VERSION ""

NS_ :

BS_:

BU_: TM

BO_ 732 TPMS1: 8 Vector__XXX
 SG_ TpmsTireSensorConfig : 47|2@0+ (1,0) [0|3] ""  TM
 SG_ TPMSPresence : 49|1@0+ (1,0) [0|1] ""  TM
 SG_ LowTirePresAlertSpare : 14|1@0+ (1,0) [0|1] ""  TM
 SG_ LowTirePresAlertRL : 13|1@0+ (1,0) [0|1] ""  TM
 SG_ LowTirePresAlertRR : 12|1@0+ (1,0) [0|1] ""  TM
 SG_ LowTirePresAlertFR : 11|1@0+ (1,0) [0|1] ""  TM
 SG_ LowTirePresAlertFL : 10|1@0+ (1,0) [0|1] ""  TM
 SG_ HighTirePresAlertSpare : 4|1@0+ (1,0) [0|1] ""  TM
 SG_ HighTirePresAlertRL : 2|1@0+ (1,0) [0|1] ""  TM
 SG_ HighTirePresAlertRR : 3|1@0+ (1,0) [0|1] ""  TM
 SG_ HighTirePresAlertFR : 1|1@0+ (1,0) [0|1] ""  TM
 SG_ HighTirePresAlertFL : 0|1@0+ (1,0) [0|1] ""  TM
 SG_ HighTireTempAlertSpare : 9|1@0+ (1,0) [0|1] ""  TM
 SG_ HighTireTempAlertRL : 7|1@0+ (1,0) [0|1] ""  TM
 SG_ HighTireTempAlertRR : 8|1@0+ (1,0) [0|1] ""  TM
 SG_ HighTireTempAlertFR : 6|1@0+ (1,0) [0|1] ""  TM
 SG_ HighTireTempAlertFL : 5|1@0+ (1,0) [0|1] ""  TM
 SG_ PresLeakageAlertSpare : 19|1@0+ (1,0) [0|1] ""  TM
 SG_ PresLeakageAlertRL : 17|1@0+ (1,0) [0|1] ""  TM
 SG_ PresLeakageAlertRR : 18|1@0+ (1,0) [0|1] ""  TM
 SG_ PresLeakageAlertFR : 16|1@0+ (1,0) [0|1] ""  TM
 SG_ PresLeakageAlertFL : 15|1@0+ (1,0) [0|1] ""  TM
 SG_ TpmsAlertStatus : 45|2@0+ (1,0) [0|3] ""  TM
 SG_ TpmsReceiverRXFault : 48|1@0+ (1,0) [0|1] ""  TM
 SG_ SensorMalfncFaultSpare : 29|1@0+ (1,0) [0|1] ""  TM
 SG_ SensorMalfncFaultRL : 27|1@0+ (1,0) [0|1] ""  TM
 SG_ SensorMalfncFaultRR : 28|1@0+ (1,0) [0|1] ""  TM
 SG_ SensorMalfncFaultFR : 26|1@0+ (1,0) [0|1] ""  TM
 SG_ SensorMalfncFaultFL : 25|1@0+ (1,0) [0|1] ""  TM
 SG_ TpmsFaultStatus : 39|2@0+ (1,0) [0|3] ""  TM
 SG_ TpmsNotLearntFault : 40|1@0+ (1,0) [0|1] ""  TM
 SG_ SensorMissingFaultRL : 32|1@0+ (1,0) [0|1] ""  TM
 SG_ SensorMissingFaultRR : 33|1@0+ (1,0) [0|1] ""  TM
 SG_ SensorMissingFaultFR : 31|1@0+ (1,0) [0|1] ""  TM
 SG_ SensorMissingFaultFL : 30|1@0+ (1,0) [0|1] ""  TM
 SG_ TpmsLearnStatus : 51|2@0+ (1,0) [0|3] ""  TM
 SG_ SpareTireSwapFlagRL : 36|1@0+ (1,0) [0|1] ""  TM
 SG_ SpareTireSwapFlagRR : 37|1@0+ (1,0) [0|1] ""  TM
 SG_ SpareTireSwapFlagFR : 35|1@0+ (1,0) [0|1] ""  TM
 SG_ SpareTireSwapFlagFL : 34|1@0+ (1,0) [0|1] ""  TM
 SG_ SensorLearningStatus : 43|3@0+ (1,0) [0|7] ""  TM
 SG_ SensorDetectFlagSpare : 24|1@0+ (1,0) [0|1] ""  TM
 SG_ SensorDetectFlagRL : 22|1@0+ (1,0) [0|1] ""  TM
 SG_ SensorDetectFlagRR : 23|1@0+ (1,0) [0|1] ""  TM
 SG_ SensorDetectFlagFR : 21|1@0+ (1,0) [0|1] ""  TM
 SG_ SensorDetectFlagFL : 20|1@0+ (1,0) [0|1] ""  TM

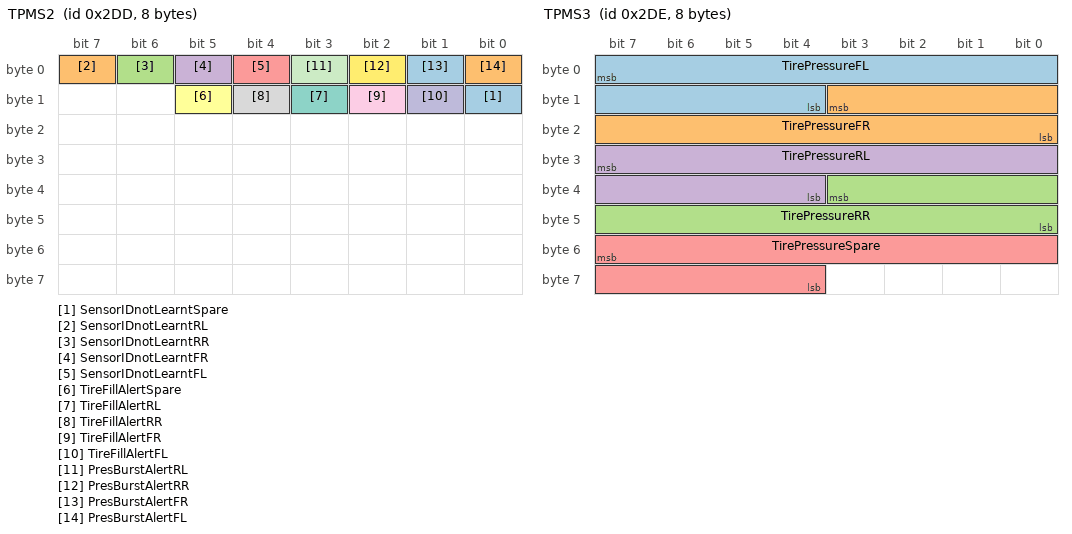
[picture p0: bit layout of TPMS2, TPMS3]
BO_ 733 TPMS2: 8 Vector__XXX
 SG_ SensorIDnotLearntSpare : 8|1@0+ (1,0) [0|1] ""  TM
 SG_ SensorIDnotLearntRL : 7|1@0+ (1,0) [0|1] ""  TM
 SG_ SensorIDnotLearntRR : 6|1@0+ (1,0) [0|1] ""  TM
 SG_ SensorIDnotLearntFR : 5|1@0+ (1,0) [0|1] ""  TM
 SG_ SensorIDnotLearntFL : 4|1@0+ (1,0) [0|1] ""  TM
 SG_ TireFillAlertSpare : 13|1@0+ (1,0) [0|1] ""  TM
 SG_ TireFillAlertRL : 11|1@0+ (1,0) [0|1] ""  TM
 SG_ TireFillAlertRR : 12|1@0+ (1,0) [0|1] ""  TM
 SG_ TireFillAlertFR : 10|1@0+ (1,0) [0|1] ""  TM
 SG_ TireFillAlertFL : 9|1@0+ (1,0) [0|1] ""  TM
 SG_ PresBurstAlertRL : 3|1@0+ (1,0) [0|1] ""  TM
 SG_ PresBurstAlertRR : 2|1@0+ (1,0) [0|1] ""  TM
 SG_ PresBurstAlertFR : 1|1@0+ (1,0) [0|1] ""  TM
 SG_ PresBurstAlertFL : 0|1@0+ (1,0) [0|1] ""  TM

BO_ 734 TPMS3: 8 Vector__XXX
 SG_ TirePressureFL : 7|12@0+ (0.1,0) [0|409.5] "Psi"  TM
 SG_ TirePressureFR : 11|12@0+ (0.1,0) [0|409.5] "Psi"  TM
 SG_ TirePressureRR : 35|12@0+ (0.1,0) [0|409.5] "Psi"  TM
 SG_ TirePressureRL : 31|12@0+ (0.1,0) [0|409.5] "Psi"  TM
 SG_ TirePressureSpare : 55|12@0+ (0.1,0) [0|409.5] "Psi"  TM

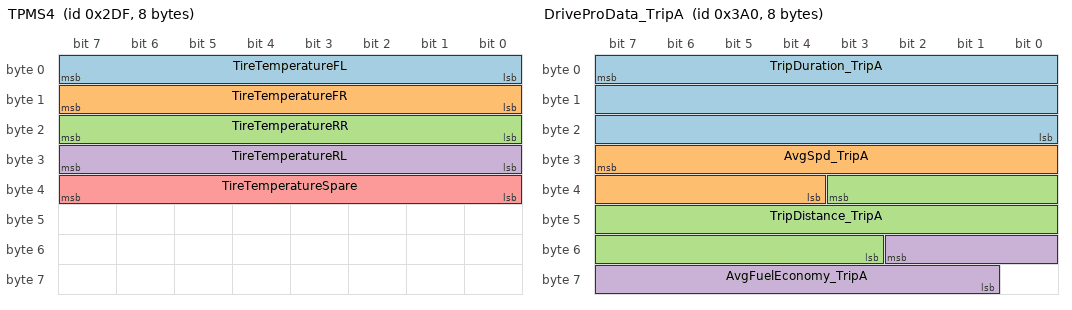
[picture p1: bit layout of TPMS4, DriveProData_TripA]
BO_ 735 TPMS4: 8 Vector__XXX
 SG_ TireTemperatureFL : 7|8@0+ (1,-40) [-40|215] "Deg C"  TM
 SG_ TireTemperatureFR : 15|8@0+ (1,-40) [-40|215] "Deg C"  TM
 SG_ TireTemperatureRR : 23|8@0+ (1,-40) [-40|215] "Deg C"  TM
 SG_ TireTemperatureRL : 31|8@0+ (1,-40) [-40|215] "Deg C"  TM
 SG_ TireTemperatureSpare : 39|8@0+ (1,-40) [-40|215] "Deg C"  TM

BO_ 744 HU_CCM_VR_Control: 8 Vector__XXX
 SG_ HuCCmFanSpdDuringVR : 5|4@0+ (1,0) [0|15] ""  TM
 SG_ HuCCmVRSession : 7|2@0+ (1,0) [0|3] ""  TM

BO_ 928 DriveProData_TripA: 8 Vector__XXX
 SG_ TripDuration_TripA : 7|24@0+ (1,0) [0|3600000] "sec"  TM
 SG_ AvgSpd_TripA : 31|12@0+ (0.03125,0) [0|127.96875] "m/s"  TM
 SG_ TripDistance_TripA : 35|17@0+ (0.1,0) [0|9999.9] "Km"  TM
 SG_ AvgFuelEconomy_TripA : 50|10@0+ (0.1,0) [0|99.9] "Km/L"  TM

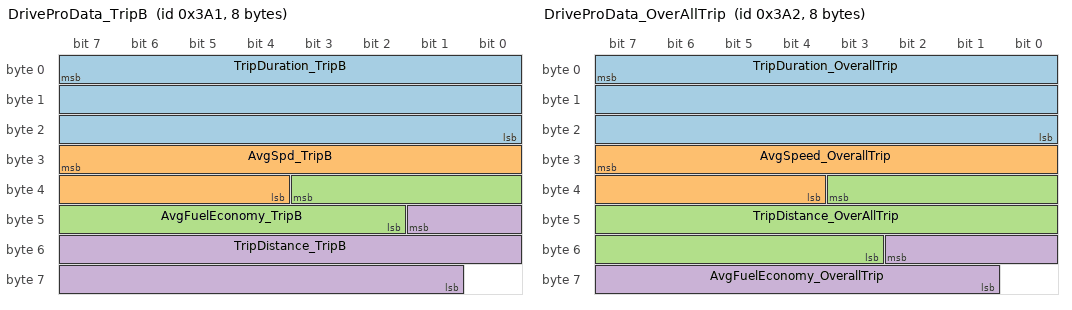
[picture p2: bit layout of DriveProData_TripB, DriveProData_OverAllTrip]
BO_ 929 DriveProData_TripB: 8 Vector__XXX
 SG_ TripDuration_TripB : 7|24@0+ (1,0) [0|3600000] "sec"  TM
 SG_ AvgSpd_TripB : 31|12@0+ (0.03125,0) [0|127.96875] "m/s"  TM
 SG_ AvgFuelEconomy_TripB : 35|10@0+ (0.1,0) [0|99.9] "Km/L"  TM
 SG_ TripDistance_TripB : 41|17@0+ (0.1,0) [0|9999.9] "Km"  TM

BO_ 930 DriveProData_OverAllTrip: 8 Vector__XXX
 SG_ TripDuration_OverallTrip : 7|24@0+ (1,0) [0|3600000] "sec"  TM
 SG_ AvgSpeed_OverallTrip : 31|12@0+ (0.03125,0) [0|127.96875] "m/s"  TM
 SG_ TripDistance_OverAllTrip : 35|17@0+ (0.1,0) [0|9999.9] "Km"  TM
 SG_ AvgFuelEconomy_OverallTrip : 50|10@0+ (0.1,0) [0|99.9] "Km/L"  TM

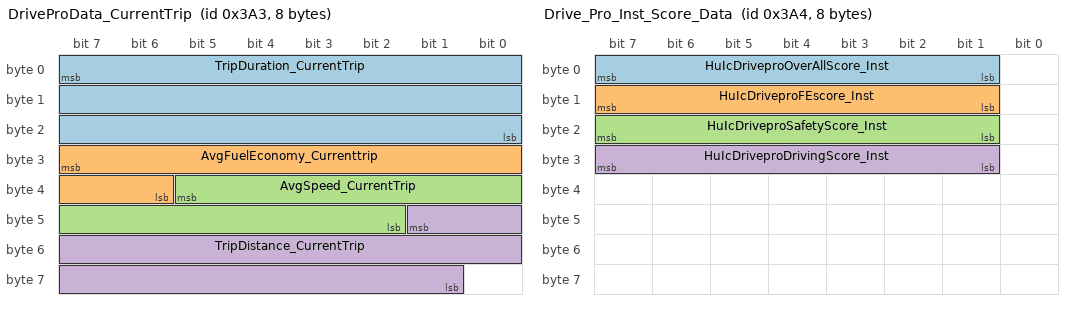
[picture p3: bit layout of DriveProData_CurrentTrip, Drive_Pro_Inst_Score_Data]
BO_ 931 DriveProData_CurrentTrip: 8 Vector__XXX
 SG_ TripDuration_CurrentTrip : 7|24@0+ (1,0) [0|3600000] "sec"  TM
 SG_ AvgFuelEconomy_Currenttrip : 31|10@0+ (0.1,0) [0|99.9] "Km/L"  TM
 SG_ AvgSpeed_CurrentTrip : 37|12@0+ (0.03125,0) [0|127.96875] "m/s"  TM
 SG_ TripDistance_CurrentTrip : 41|17@0+ (0.1,0) [0|9999.9] "Km"  TM

BO_ 932 Drive_Pro_Inst_Score_Data: 8 Vector__XXX
 SG_ HuIcDriveproOverAllScore_Inst : 7|7@0+ (0.1,0) [0|10] ""  TM
 SG_ HuIcDriveproFEscore_Inst : 15|7@0+ (0.1,0) [0|10] ""  TM
 SG_ HuIcDriveproSafetyScore_Inst : 23|7@0+ (0.1,0) [0|10] ""  TM
 SG_ HuIcDriveproDrivingScore_Inst : 31|7@0+ (0.1,0) [0|10] ""  TM

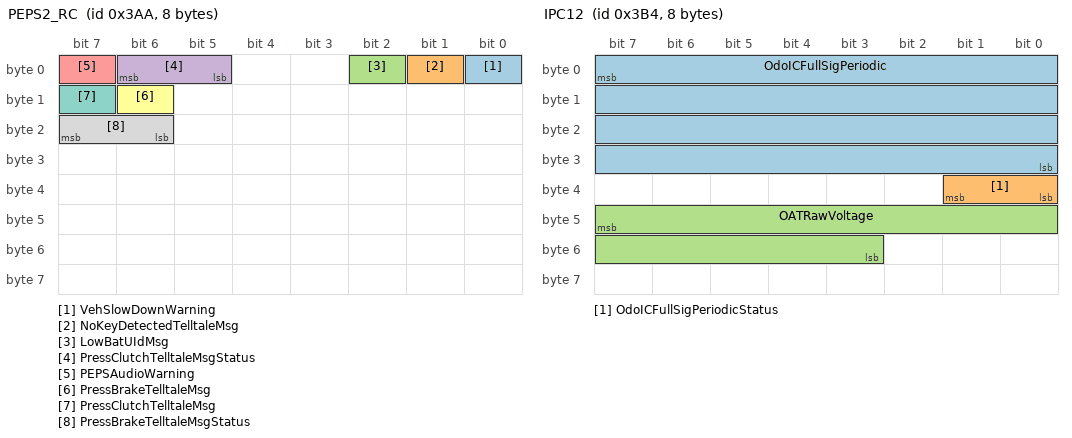
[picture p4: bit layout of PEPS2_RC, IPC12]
BO_ 938 PEPS2_RC: 8 Vector__XXX
 SG_ VehSlowDownWarning : 0|1@0+ (1,0) [0|1] ""  TM
 SG_ NoKeyDetectedTelltaleMsg : 1|1@0+ (1,0) [0|1] ""  TM
 SG_ LowBatUIdMsg : 2|1@0+ (1,0) [0|1] ""  TM
 SG_ PressClutchTelltaleMsgStatus : 6|2@0+ (1,0) [0|3] ""  TM
 SG_ PEPSAudioWarning : 7|1@0+ (1,0) [0|1] ""  TM
 SG_ PressBrakeTelltaleMsg : 14|1@0+ (1,0) [0|1] ""  TM
 SG_ PressClutchTelltaleMsg : 15|1@0+ (1,0) [0|1] ""  TM
 SG_ PressBrakeTelltaleMsgStatus : 23|2@0+ (1,0) [0|3] ""  TM

BO_ 946 BCM_IC_RC4: 8 Vector__XXX
 SG_ DoorStateRearLHStatus : 1|2@0+ (1,0) [0|3] ""  TM
 SG_ DoorStatePassStatus : 3|2@0+ (1,0) [0|3] ""  TM
 SG_ DoorStatePass : 4|1@0+ (1,0) [0|1] ""  TM
 SG_ DoorStateDrvrStatus : 6|2@0+ (1,0) [0|3] ""  TM
 SG_ DoorStateDrvr : 7|1@0+ (1,0) [0|1] ""  TM
 SG_ DoorStateRearRH : 8|1@0+ (1,0) [0|1] ""  TM
 SG_ DoorStateRearRHStatus : 10|2@0+ (1,0) [0|3] ""  TM
 SG_ DoorStateRearLH : 11|1@0+ (1,0) [0|1] ""  TM
 SG_ WiperState : 14|3@0+ (1,0) [0|7] ""  TM
 SG_ TailgateState : 15|1@0+ (1,0) [0|1] ""  TM
 SG_ WiperStateStatus : 17|2@0+ (1,0) [0|3] ""  TM
 SG_ TailgateStateStatus : 19|2@0+ (1,0) [0|3] ""  TM
 SG_ PositionLmpMalFn : 20|1@0+ (1,0) [0|1] ""  TM
 SG_ TrailerState : 21|1@0+ (1,0) [0|1] ""  TM
 SG_ PositionLmpMalFnStatus : 23|2@0+ (1,0) [0|3] ""  TM
 SG_ BrakeLmpMalFn : 24|1@0+ (1,0) [0|1] ""  TM
 SG_ BrakeLmpMalFnStatus : 26|2@0+ (1,0) [0|3] ""  TM
 SG_ RevLampMalFn : 27|1@0+ (1,0) [0|1] ""  TM
 SG_ RevLampMalFnStatus : 29|2@0+ (1,0) [0|3] ""  TM
 SG_ TrailerStateStatus : 31|2@0+ (1,0) [0|3] ""  TM
 SG_ LowBeamMalFn : 32|1@0+ (1,0) [0|1] ""  TM
 SG_ HighBeamTelltale : 33|1@0+ (1,0) [0|1] ""  TM
 SG_ HighBeamTelltaleStatus : 35|2@0+ (1,0) [0|3] ""  TM
 SG_ DRLTelltale : 36|1@0+ (1,0) [0|1] ""  TM
 SG_ FrontFogTelltale : 37|1@0+ (1,0) [0|1] ""  TM
 SG_ RearFogTelltaleStatus : 39|2@0+ (1,0) [0|3] ""  TM
 SG_ FrontFogTelltaleStatus : 41|2@0+ (1,0) [0|3] ""  TM
 SG_ DRLTelltaleStatus : 43|2@0+ (1,0) [0|3] ""  TM
 SG_ InfoTheftMsg : 45|2@0+ (1,0) [0|3] ""  TM
 SG_ WiperHighLowIntermtStateStatus : 47|2@0+ (1,0) [0|3] ""  TM
 SG_ WiperHighLowIntermtState : 50|3@0+ (1,0) [0|7] ""  TM
 SG_ LowBeamMalFnStatus : 52|2@0+ (1,0) [0|3] ""  TM
 SG_ ESSSwSig : 53|1@0+ (1,0) [0|1] ""  TM
 SG_ BonnetState : 54|1@0+ (1,0) [0|1] ""  TM
 SG_ RearFogTelltale : 55|1@0+ (1,0) [0|1] ""  TM
 SG_ BonnetStateStatus : 57|2@0+ (1,0) [0|3] ""  TM
 SG_ VehicleUnLockTypeConfgStatus : 59|2@0+ (1,0) [0|3] ""  TM
 SG_ VehicleUnLockTypeConfg : 61|2@0+ (1,0) [0|3] ""  TM
 SG_ ESSSwSigStatus : 63|2@0+ (1,0) [0|3] ""  TM

BO_ 948 IPC12: 8 Vector__XXX
 SG_ OdoICFullSigPeriodic : 7|32@0+ (1,0) [0|999999000] "m"  TM
 SG_ OdoICFullSigPeriodicStatus : 33|2@0+ (1,0) [0|3] ""  TM
 SG_ OATRawVoltage : 47|13@0+ (0.001,0) [0|5] "v"  TM

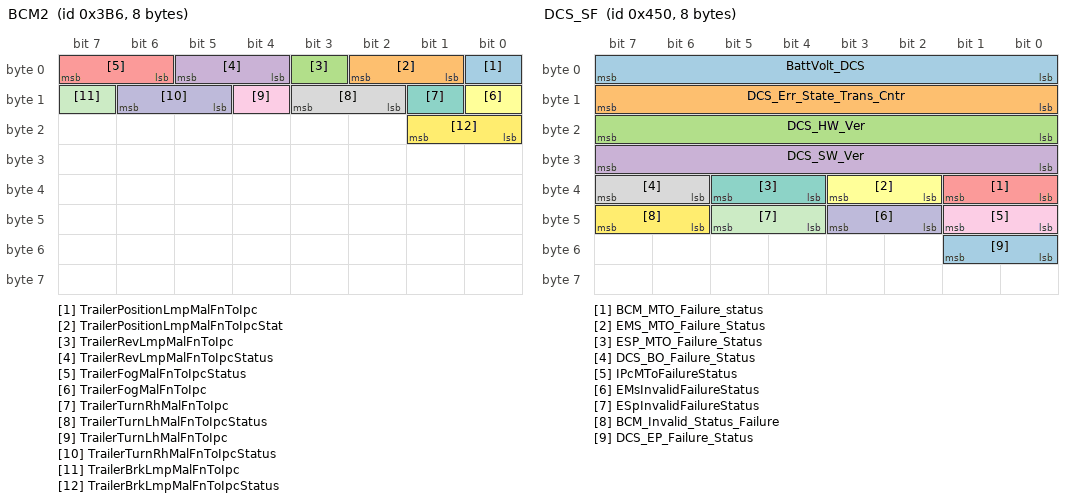
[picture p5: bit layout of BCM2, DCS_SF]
BO_ 950 BCM2: 8 Vector__XXX
 SG_ TrailerPositionLmpMalFnToIpc : 0|1@0+ (1,0) [0|1] ""  TM
 SG_ TrailerPositionLmpMalFnToIpcStat : 2|2@0+ (1,0) [0|3] ""  TM
 SG_ TrailerRevLmpMalFnToIpc : 3|1@0+ (1,0) [0|1] ""  TM
 SG_ TrailerRevLmpMalFnToIpcStatus : 5|2@0+ (1,0) [0|3] ""  TM
 SG_ TrailerFogMalFnToIpcStatus : 7|2@0+ (1,0) [0|3] ""  TM
 SG_ TrailerFogMalFnToIpc : 8|1@0+ (1,0) [0|1] ""  TM
 SG_ TrailerTurnRhMalFnToIpc : 9|1@0+ (1,0) [0|1] ""  TM
 SG_ TrailerTurnLhMalFnToIpcStatus : 11|2@0+ (1,0) [0|3] ""  TM
 SG_ TrailerTurnLhMalFnToIpc : 12|1@0+ (1,0) [0|1] ""  TM
 SG_ TrailerTurnRhMalFnToIpcStatus : 14|2@0+ (1,0) [0|3] ""  TM
 SG_ TrailerBrkLmpMalFnToIpc : 15|1@0+ (1,0) [0|1] ""  TM
 SG_ TrailerBrkLmpMalFnToIpcStatus : 17|2@0+ (1,0) [0|3] ""  TM

BO_ 1068 IPC7: 8 Vector__XXX
 SG_ IcHuVcInfo : 7|40@0+ (1,0) [0|0] ""  TM
 SG_ ICDrvModeFunVariant : 47|16@0+ (1,0) [0|65535] ""  TM

BO_ 1069 IPC9: 8 Vector__XXX
 SG_ IcHuVcInfonew : 7|64@0+ (1,0) [0|1.8446744074E+019] ""  TM

BO_ 1104 DCS_SF: 8 Vector__XXX
 SG_ BattVolt_DCS : 7|8@0+ (0.1,0) [0|25] "V"  TM
 SG_ DCS_Err_State_Trans_Cntr : 15|8@0+ (1,0) [0|255] ""  TM
 SG_ DCS_HW_Ver : 23|8@0+ (1,0) [0|99] ""  TM
 SG_ DCS_SW_Ver : 31|8@0+ (1,0) [0|255] ""  TM
 SG_ BCM_MTO_Failure_status : 33|2@0+ (1,0) [0|3] ""  TM
 SG_ EMS_MTO_Failure_Status : 35|2@0+ (1,0) [0|3] ""  TM
 SG_ ESP_MTO_Failure_Status : 37|2@0+ (1,0) [0|3] ""  TM
 SG_ DCS_BO_Failure_Status : 39|2@0+ (1,0) [0|3] ""  TM
 SG_ IPcMToFailureStatus : 41|2@0+ (1,0) [0|3] ""  TM
 SG_ EMsInvalidFailureStatus : 43|2@0+ (1,0) [0|3] ""  TM
 SG_ ESpInvalidFailureStatus : 45|2@0+ (1,0) [0|3] ""  TM
 SG_ BCM_Invalid_Status_Failure : 47|2@0+ (1,0) [0|3] ""  TM
 SG_ DCS_EP_Failure_Status : 49|2@0+ (1,0) [0|3] ""  TM

BO_ 1120 HU6: 8 Vector__XXX
 SG_ HuIcTpSig : 7|64@0+ (1,0) [0|0] ""  TM

BO_ 1121 IPC13: 8 Vector__XXX
 SG_ IcHuTpSig : 7|64@0+ (1,0) [0|0] ""  TM

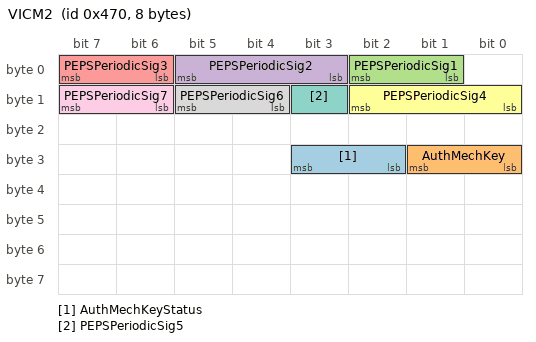
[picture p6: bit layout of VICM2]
BO_ 1136 VICM2: 8 Vector__XXX
 SG_ AuthMechKeyStatus : 27|2@0+ (1,0) [0|3] ""  TM
 SG_ AuthMechKey : 25|2@0+ (1,0) [0|3] ""  TM
 SG_ PEPSPeriodicSig1 : 2|2@0+ (1,0) [0|3] ""  TM
 SG_ PEPSPeriodicSig2 : 5|3@0+ (1,0) [0|7] ""  TM
 SG_ PEPSPeriodicSig3 : 7|2@0+ (1,0) [0|3] ""  TM
 SG_ PEPSPeriodicSig4 : 10|3@0+ (1,0) [0|7] ""  TM
 SG_ PEPSPeriodicSig5 : 11|1@0+ (1,0) [0|1] ""  TM
 SG_ PEPSPeriodicSig6 : 13|2@0+ (1,0) [0|3] ""  TM
 SG_ PEPSPeriodicSig7 : 15|2@0+ (1,0) [0|3] ""  TM

BO_ 1140 EMS_SF: 8 Vector__XXX
 SG_ Telematics_MTO_Failure_Status : 29|2@0+ (1,0) [0|3] ""  TM
 SG_ Telematics_Invalid_Failure__0000 : 31|2@0+ (1,0) [0|3] ""  TM
 SG_ HU_MTO_Failure_Status : 25|2@0+ (1,0) [0|3] ""  TM
 SG_ HU_Invalid_Failure_Status : 27|2@0+ (1,0) [0|3] ""  TM
 SG_ CCM_Invalid_Failure_Status : 37|2@0+ (1,0) [0|3] ""  TM
 SG_ EMS_SW_Version : 7|16@0+ (1,0) [0|255] ""  TM
 SG_ AT_AMT_DCT_MTO_Failure_Status : 17|2@0+ (1,0) [0|3] ""  TM
 SG_ EPAS_Invalid_Failure_Status : 19|2@0+ (1,0) [0|3] ""  TM
 SG_ BCmMToFailureStatus : 21|2@0+ (1,0) [0|3] ""  TM
 SG_ EPAS_MTO_Failure_Status : 23|2@0+ (1,0) [0|3] ""  TM
 SG_ EMS_BO_Failure_Status : 33|2@0+ (1,0) [0|3] ""  TM
 SG_ EMS_EP_Failure_Status : 35|2@0+ (1,0) [0|3] ""  TM
 SG_ ABS_ESP_MTO_Failure_Status : 39|2@0+ (1,0) [0|3] ""  TM
 SG_ PEPS_MTO_Failure_Status : 41|2@0+ (1,0) [0|3] ""  TM
 SG_ AT_AMT_DCT_Invalid_Failure_Statu : 43|2@0+ (1,0) [0|3] ""  TM
 SG_ ABS_ESP_Invalid_Failure_Status : 45|2@0+ (1,0) [0|3] ""  TM
 SG_ IPcInvalidFailureStatus : 47|2@0+ (1,0) [0|3] ""  TM
 SG_ BCmInvalidFailureStatus : 49|2@0+ (1,0) [0|3] ""  TM
 SG_ IPcMToFailureStatus : 51|2@0+ (1,0) [0|3] ""  TM
 SG_ CCM_MTO_Failure_Status : 53|2@0+ (1,0) [0|3] ""  TM
 SG_ DCS_Invalid_Failure_Status : 55|2@0+ (1,0) [0|3] ""  TM
 SG_ DCS_MTO_Failure_Status : 57|2@0+ (1,0) [0|3] ""  TM
 SG_ ABS_ESP_MRC_Failure_Status : 59|2@0+ (1,0) [0|3] ""  TM
 SG_ ABS_ESP_CRC_Failure_Status : 61|2@0+ (1,0) [0|3] ""  TM
 SG_ SRS_MTO_Failure_Status : 63|2@0+ (1,0) [0|3] ""  TM

BO_ 1154 EPAS_SF: 8 Vector__XXX
 SG_ EPAS_SW_Version : 7|8@0+ (1,0) [0|255] ""  TM
 SG_ BattVolt_EPAS : 23|8@0+ (0.1,0) [0|25] "V"  TM
 SG_ ABsESpMRcFailureStatus : 33|2@0+ (1,0) [0|3] ""  TM
 SG_ ABsESpCRcFailureStatus : 35|2@0+ (1,0) [0|3] ""  TM
 SG_ EMsInvalidFailureStatus : 37|2@0+ (1,0) [0|3] ""  TM
 SG_ ABsESpMToFailureStatus : 39|2@0+ (1,0) [0|3] ""  TM
 SG_ IPC_MRC_Failure_Status : 41|2@0+ (1,0) [0|3] ""  TM
 SG_ IPC_CRC_Failure_Status : 43|2@0+ (1,0) [0|3] ""  TM
 SG_ EPAS_EP_Failure_Status : 45|2@0+ (1,0) [0|3] ""  TM
 SG_ EPAS_BO_Failure_Status : 47|2@0+ (1,0) [0|3] ""  TM
 SG_ IPcInvalidFailureStatus : 49|2@0+ (1,0) [0|3] ""  TM
 SG_ BCM_MTO_Failure_status : 51|2@0+ (1,0) [0|3] ""  TM
 SG_ IPcMToFailureStatus : 53|2@0+ (1,0) [0|3] ""  TM
 SG_ EMsMToFailureStatus : 55|2@0+ (1,0) [0|3] ""  TM
 SG_ ABsESpInvalidFailureStatus : 57|2@0+ (1,0) [0|3] ""  TM
 SG_ AMT_AT_DCT_MTO_Failure_Status : 59|2@0+ (1,0) [0|3] ""  TM
 SG_ AMT_AT_DCT_Invalid_Failure_Statu : 63|2@0+ (1,0) [0|3] ""  TM

CM_ SG_ 732 TpmsTireSensorConfig "TPMS Tire Sensor Configuration";
CM_ SG_ 732 TPMSPresence "TPMS Presence";
CM_ SG_ 732 LowTirePresAlertSpare "Low Tire Pressure Alert Spare";
CM_ SG_ 732 LowTirePresAlertRL "Low Tire Pressure Alert Rear Left";
CM_ SG_ 732 LowTirePresAlertRR "Low Tire Pressure Alert Rear Right";
CM_ SG_ 732 LowTirePresAlertFR "Low Tire Pressure Alert Front Right
";
CM_ SG_ 732 LowTirePresAlertFL "Low Tire Pressure Alert Front Left";
CM_ SG_ 732 HighTirePresAlertSpare "High Tire Pressure Alert Spare";
CM_ SG_ 732 HighTirePresAlertRL "High Tire Pressure Alert Rear Left";
CM_ SG_ 732 HighTirePresAlertRR "High Tire Pressure Alert Rear Right";
CM_ SG_ 732 HighTirePresAlertFR "High Tire Pressure Alert Front Right";
CM_ SG_ 732 HighTirePresAlertFL "High Tire Pressure Alert Front Left";
CM_ SG_ 732 HighTireTempAlertSpare "High Tire Temperature Alert Spart";
CM_ SG_ 732 HighTireTempAlertRL "High Tire Temperature Alert Rear Left";
CM_ SG_ 732 HighTireTempAlertRR "High Tire Temperature Alert Rear Right";
CM_ SG_ 732 HighTireTempAlertFR "High Tire Temperature Alert Front Right";
CM_ SG_ 732 HighTireTempAlertFL "High Tire Temperature Alert Front Left";
CM_ SG_ 732 PresLeakageAlertSpare "Pressure Leakage Alert Spare";
CM_ SG_ 732 PresLeakageAlertRL "Pressure Leakage Alert Rear Left";
CM_ SG_ 732 PresLeakageAlertRR "Pressure Leakage Alert Rear Right";
CM_ SG_ 732 PresLeakageAlertFR "Pressure Leakage Alert Front Right";
CM_ SG_ 732 PresLeakageAlertFL "Pressure Leakage Alert Front Left";
CM_ SG_ 732 TpmsAlertStatus "PMS Alert Status";
CM_ SG_ 732 TpmsReceiverRXFault "TPMS Receiver Rx Fault";
CM_ SG_ 732 SensorMalfncFaultSpare "Sensor Malfunction Fault Spare";
CM_ SG_ 732 SensorMalfncFaultRL "Sensor Malfunction Fault Rear Left";
CM_ SG_ 732 SensorMalfncFaultRR "Sensor Malfunction Fault Rear Right";
CM_ SG_ 732 SensorMalfncFaultFR "Sensor Malfunction Fault Front Right
";
CM_ SG_ 732 SensorMalfncFaultFL "Sensor Malfunction Fault Front Left";
CM_ SG_ 732 TpmsFaultStatus "TPMS Fault Status";
CM_ SG_ 732 TpmsNotLearntFault "TPMS Not Learnt Fault";
CM_ SG_ 732 SensorMissingFaultRL "Sensor Missing Fault Rear Left";
CM_ SG_ 732 SensorMissingFaultRR "Sensor Missing Fault Rear Right";
CM_ SG_ 732 SensorMissingFaultFR "Sensor Missing Fault Front Right";
CM_ SG_ 732 SensorMissingFaultFL "Sensor Missing Fault Front Left";
CM_ SG_ 732 TpmsLearnStatus "TPMS Learning Status";
CM_ SG_ 732 SpareTireSwapFlagRL "Spare Tire Swap Flag Rear Left";
CM_ SG_ 732 SpareTireSwapFlagRR "Spare Tire Swap Flag Rear Right";
CM_ SG_ 732 SpareTireSwapFlagFR "Spare Tire Swap Flag Front Right";
CM_ SG_ 732 SpareTireSwapFlagFL "Spare Tire Swap Flag Front Left";
CM_ SG_ 732 SensorLearningStatus "Tire Sensor Learning Status";
CM_ SG_ 732 SensorDetectFlagSpare "Sensor Detect Flag Spare";
CM_ SG_ 732 SensorDetectFlagRL "Sensor Detect Flag Rear Left";
CM_ SG_ 732 SensorDetectFlagRR "Sensor Detect Flag Rear Right";
CM_ SG_ 732 SensorDetectFlagFR "Sensor Detect Flag Front Right";
CM_ SG_ 732 SensorDetectFlagFL "Sensor Detect Flag Front Left";
CM_ SG_ 733 SensorIDnotLearntSpare "Sensor ID Not Learnt Spare";
CM_ SG_ 733 SensorIDnotLearntRL "Sensor ID Not Learnt Rear Left";
CM_ SG_ 733 SensorIDnotLearntRR "Sensor ID Not Learnt Rear Right";
CM_ SG_ 733 SensorIDnotLearntFR "Sensor ID Not Learnt Front Right";
CM_ SG_ 733 SensorIDnotLearntFL "Sensor ID Not Learnt Front Left";
CM_ SG_ 733 TireFillAlertSpare "Tire Fill Alert Spare";
CM_ SG_ 733 TireFillAlertRL "Tire Fill Alert Rear Left";
CM_ SG_ 733 TireFillAlertRR "Tire Fill Alert Rear Right";
CM_ SG_ 733 TireFillAlertFR "Tire Fill Alert Front Right";
CM_ SG_ 733 TireFillAlertFL "Tire Fill Alert Front Left";
CM_ SG_ 733 PresBurstAlertRL "Pressure Burst Alert Rear Left";
CM_ SG_ 733 PresBurstAlertRR "Pressure Burst Alert Rear Right";
CM_ SG_ 733 PresBurstAlertFR "Pressure Burst Alert Front Right";
CM_ SG_ 733 PresBurstAlertFL "Pressure Burst Alert Front Left";
CM_ BO_ 734 "TPMS Test Msg";
CM_ SG_ 734 TirePressureFL "Tire Pressure Front Left Tire";
CM_ SG_ 734 TirePressureFR "Tire Pressure Front Right Tire";
CM_ SG_ 734 TirePressureRR "Tire Pressure Rear Right Tire";
CM_ SG_ 734 TirePressureRL "Tire Pressure Rear Left Tire";
CM_ SG_ 734 TirePressureSpare "Tire Pressure Spare Tire";
CM_ BO_ 735 "TPMS Test Msg";
CM_ SG_ 735 TireTemperatureFL "Tire Temperature Front Left Tire";
CM_ SG_ 735 TireTemperatureFR "Tire Temperature Front Right Tire";
CM_ SG_ 735 TireTemperatureRR "Tire Temperature Rear Right Tire";
CM_ SG_ 735 TireTemperatureRL "Tire Temperature Rear Left Tire";
CM_ SG_ 735 TireTemperatureSpare "Tire Temperature Spare Tire";
CM_ SG_ 744 HuCCmFanSpdDuringVR "HU should tell to CCM about the FAN speed during VR seesion active";
CM_ SG_ 744 HuCCmVRSession "HU should tell to CCM about the VR session state";
CM_ SG_ 928 TripDuration_TripA "IC shall send Trip A Duration to HU";
CM_ SG_ 928 AvgSpd_TripA "IC shall send Trip A Average speed to HU";
CM_ SG_ 928 TripDistance_TripA "IC shall send Trip A Distance to HU";
CM_ SG_ 928 AvgFuelEconomy_TripA "IC shall send Trip A Average  Fuel Economy to HU";
CM_ SG_ 929 TripDuration_TripB "IC shall send  Trip B Duration to HU";
CM_ SG_ 929 AvgSpd_TripB "IC shall send TripB Average speed to HU";
CM_ SG_ 929 AvgFuelEconomy_TripB "IC shall send Trip B Average  Fuel Economy to HU";
CM_ SG_ 929 TripDistance_TripB "IC shall send Trip B Distance to HU";
CM_ SG_ 930 TripDuration_OverallTrip "IC shall send overall Trip Duration to HU";
CM_ SG_ 930 AvgSpeed_OverallTrip "IC shall send Overall Trip  Average speed to HU";
CM_ SG_ 930 TripDistance_OverAllTrip "IC shall send Over allTrip  Distance to HU";
CM_ SG_ 930 AvgFuelEconomy_OverallTrip "IC shall send Over all trip Average  Fuel Economy to HU";
CM_ SG_ 931 TripDuration_CurrentTrip "IC shall send Current Trip Duration to HU";
CM_ SG_ 931 AvgFuelEconomy_Currenttrip "IC shall send Current Trip Fuel Economy to HU";
CM_ SG_ 931 AvgSpeed_CurrentTrip "IC shall send Current Trip Average speed to HU";
CM_ SG_ 931 TripDistance_CurrentTrip "IC shall send Current Trip Distance to HU";
CM_ SG_ 932 HuIcDriveproOverAllScore_Inst "HU shall send Overall trip Reset to IC";
CM_ SG_ 932 HuIcDriveproFEscore_Inst "Drive Pro Instantaneous Trip Data fron HU to IC";
CM_ SG_ 932 HuIcDriveproSafetyScore_Inst "Drive Pro Instantaneous Trip Data fron HU to IC";
CM_ SG_ 932 HuIcDriveproDrivingScore_Inst "Drive Pro Instantaneous score from HU to IC";
CM_ SG_ 938 VehSlowDownWarning "To Inform user for slow down the vehicle speed";
CM_ SG_ 938 NoKeyDetectedTelltaleMsg "Display message request from PEPS to IC & HU - Key Not Detected";
CM_ SG_ 938 LowBatUIdMsg "Display message request from PEPS to IC & HU - UID battery is low";
CM_ SG_ 938 PressClutchTelltaleMsgStatus "Status of the 'PressClutchTelltaleMsgStatus' signal";
CM_ SG_ 938 PEPSAudioWarning "Audio warning request from PEPS to IC for invalid door handle switch press operation";
CM_ SG_ 938 PressBrakeTelltaleMsg "Display telltale & message request from PEPS to IC - Press Brake Pedal to Start Engine";
CM_ SG_ 938 PressClutchTelltaleMsg "Display telltale & message request from PEPS to IC - Press Clutch Pedal to Start Engine";
CM_ SG_ 938 PressBrakeTelltaleMsgStatus "Status of the 'PressBrakeTelltaleMsg' signal";
CM_ SG_ 946 DoorStateRearLHStatus "Rear left side door valid Status





";
CM_ SG_ 946 DoorStatePassStatus "Driver Door Passenger valid Status";
CM_ SG_ 946 DoorStatePass "Co-Driver door switch state from BCM ";
CM_ SG_ 946 DoorStateDrvrStatus "DoorStateDrvr valid Status";
CM_ SG_ 946 DoorStateDrvr "Driver door switch state from BCM ";
CM_ SG_ 946 DoorStateRearRH "Rear right side door switch state from BCM to FATC and IC";
CM_ SG_ 946 DoorStateRearRHStatus "Rear right side door valid status



";
CM_ SG_ 946 DoorStateRearLH "Rear left side door switch state from BCM";
CM_ SG_ 946 WiperState "Status of the Wiper to various ECUs";
CM_ SG_ 946 TailgateState "Tailgate switch state (open or close) from BCM to various ECUs";
CM_ SG_ 946 WiperStateStatus "Status of the Wiper whether Valid or not";
CM_ SG_ 946 TailgateStateStatus "Tailgate switch state vaild status";
CM_ SG_ 946 PositionLmpMalFn "IC to display the message when failure in Position lamp";
CM_ SG_ 946 TrailerState "State (connected or not connected) of the trailer";
CM_ SG_ 946 PositionLmpMalFnStatus "Status of the Malfunction Position Lamp";
CM_ SG_ 946 BrakeLmpMalFn "IC to display the message when failure in brake lamp";
CM_ SG_ 946 BrakeLmpMalFnStatus "Status of the Malfunction Break Lamp





";
CM_ SG_ 946 RevLampMalFn "IC to display the message when failure in reverse lamp";
CM_ SG_ 946 RevLampMalFnStatus "Status of the Malfunction Reverse Lamp";
CM_ SG_ 946 TrailerStateStatus "Status of the Trailer state";
CM_ SG_ 946 LowBeamMalFn "IC to display the message when failure in low beam lamp";
CM_ SG_ 946 HighBeamTelltale "IC to display the high beam tell-tale when the high beam lamp is active";
CM_ SG_ 946 HighBeamTelltaleStatus "Status of the High Beam Telltale";
CM_ SG_ 946 DRLTelltale "IC to display the Daytime Running Light (DRL) telltale";
CM_ SG_ 946 FrontFogTelltale "IC to display the front fog tell-tale when the front fog lamp is active";
CM_ SG_ 946 RearFogTelltaleStatus "Status of the Rear Fog Telltale";
CM_ SG_ 946 FrontFogTelltaleStatus "Status of the Front Fog Telltale";
CM_ SG_ 946 DRLTelltaleStatus "Status of the Daytime Running Light (DRL) telltale";
CM_ SG_ 946 InfoTheftMsg "BCM send this signal to IC for Infotainment theft detection message.";
CM_ SG_ 946 WiperHighLowIntermtStateStatus "Status of the Wiper Wiper High, Low, Intermittent state whether Valid or not";
CM_ SG_ 946 WiperHighLowIntermtState "Status of the Wiper High, Low, Intermittent state to various ECUs";
CM_ SG_ 946 LowBeamMalFnStatus "Status of the Low Beam Malfunction";
CM_ SG_ 946 ESSSwSig "Engine Start-Stop switch signal";
CM_ SG_ 946 BonnetState "Bonnet switch state (open or close) from BCM";
CM_ SG_ 946 RearFogTelltale "IC to display the rear fog tell-tale when the rear fog lamp is active";
CM_ SG_ 946 BonnetStateStatus "BonnetState vaild status";
CM_ SG_ 946 VehicleUnLockTypeConfgStatus "Status of the 'VehicleUnLockTypeConfg' signal";
CM_ SG_ 946 VehicleUnLockTypeConfg "Vehicle unlock type configuration command from BCM to PEPS ECU";
CM_ SG_ 946 ESSSwSigStatus "Status of the Engine Start-Stop switch signal";
CM_ SG_ 948 OdoICFullSigPeriodic "Signal represents Odometer information in full range.";
CM_ SG_ 948 OdoICFullSigPeriodicStatus "Status of Signal representing Odometer information in full range.";
CM_ SG_ 948 OATRawVoltage "OAT signal raw votage value";
CM_ SG_ 950 TrailerPositionLmpMalFnToIpc "Trailer Position Lamp malfunction to IPC signal";
CM_ SG_ 950 TrailerPositionLmpMalFnToIpcStat "Trailer Position Lamp malfunction to IPC signal status";
CM_ SG_ 950 TrailerRevLmpMalFnToIpc "Trailer Reverse Lamp malfunction signal";
CM_ SG_ 950 TrailerRevLmpMalFnToIpcStatus "Trailer reverse Lamp malfunction to IPC signal status";
CM_ SG_ 950 TrailerFogMalFnToIpcStatus "Trailer Fog Lamp malfunction to IPC signal status";
CM_ SG_ 950 TrailerFogMalFnToIpc "Trailer Fog Lamp malfunction to IPC signal";
CM_ SG_ 950 TrailerTurnRhMalFnToIpc "Trailer Turn right side indicator lamp malfunction to IPC signal";
CM_ SG_ 950 TrailerTurnLhMalFnToIpcStatus "Trailer Turn left side indicator lamp malfunction to IPC signal status";
CM_ SG_ 950 TrailerTurnLhMalFnToIpc "Trailer Turn left side indicator lamp malfunction to IPC signal";
CM_ SG_ 950 TrailerTurnRhMalFnToIpcStatus "Trailer Turn right side indicator lamp malfunction to IPC signal status";
CM_ SG_ 950 TrailerBrkLmpMalFnToIpc "Trailer Brake Lamp malfunction to IPC signal";
CM_ SG_ 950 TrailerBrkLmpMalFnToIpcStatus "Trailer brake Lamp malfunction to IPC signal status";
CM_ SG_ 1068 ICDrvModeFunVariant "Indicates the type of drive mode available in vehicle.";
CM_ SG_ 1069 IcHuVcInfonew "VC number of vehicle.";
CM_ SG_ 1104 BattVolt_DCS "Battery voltage evaluated by AMT

";
CM_ SG_ 1104 DCS_Err_State_Trans_Cntr "Number of state transitions from bus ON to bus OFF state. Reset this value to Zero in each new Ignition cycle. Freeze this value to 65535 if number of state transitions are more than this value in a given Ignition cycle.
";
CM_ SG_ 1104 DCS_HW_Ver "SW version of EEM ECU.";
CM_ SG_ 1104 DCS_SW_Ver "SW version of EEM ECU.
";
CM_ SG_ 1104 BCM_MTO_Failure_status "Message timeout failure flag against BCM ECU";
CM_ SG_ 1104 EMS_MTO_Failure_Status "Status of the EMS message timeout failure detected by AT ECU as per Tata-IVN_Specification_Network_Management.";
CM_ SG_ 1104 ESP_MTO_Failure_Status "Status of the ESP  Message timeout failure detected as per Tata-IVN_Specification_Network_Management.";
CM_ SG_ 1104 DCS_BO_Failure_Status "Status of the bus-off failure detected by EEM ECU as per Tata-IVN_Specification_Network_Management.

";
CM_ SG_ 1104 IPcMToFailureStatus "Status of the IPC Message Timeout  failure detected as per Tata-IVN_Specification_Network_Management.";
CM_ SG_ 1104 EMsInvalidFailureStatus "status of the EMS Invalid  signal  failure detected as per Tata-IVN_Specification_Network_Management.";
CM_ SG_ 1104 ESpInvalidFailureStatus "Status of the ESP signal implausible  failure detected  by EPAS  as per  communication layer spec";
CM_ SG_ 1104 BCM_Invalid_Status_Failure "Invalid data reception from BCM ECU failure flag";
CM_ SG_ 1104 DCS_EP_Failure_Status "Status of the error passive detected by DCS ECU as per Tata-IVN_Specification_Network_Management.";
CM_ BO_ 1120 "CAN TP Message";
CM_ BO_ 1121 "CAN TP Message";
CM_ SG_ 1136 AuthMechKeyStatus "Status of the AuthMechKey";
CM_ SG_ 1136 AuthMechKey "BCM receives the authorized mechanical key status over CAN signal from Immobilizer ECU.";
CM_ BO_ 1140 "Supervision frame transmitted by EMS.";
CM_ SG_ 1140 Telematics_MTO_Failure_Status "Status of the Telematics Message timeout failure detected as per Tata-IVN_Specification_Network_Management.";
CM_ SG_ 1140 Telematics_Invalid_Failure__0000 "Status of the Telematics Invalid failure detected as per Tata-IVN_Specification_Network_Management.";
CM_ SG_ 1140 HU_MTO_Failure_Status "Status of the HU Message timeout failure detected as per Tata-IVN_Specification_Network_Management.";
CM_ SG_ 1140 HU_Invalid_Failure_Status "Status of the HU  invalid failure detected as per Tata-IVN_Specification_Network_Management.";
CM_ SG_ 1140 CCM_Invalid_Failure_Status "Status of the  FATC Invalid  signal  failure detected as per Tata-IVN_Specification_Network_Management.";
CM_ SG_ 1140 AT_AMT_DCT_MTO_Failure_Status "Status of the TCM Message Timeout  failure detected as per Tata-IVN_Specification_Network_Management.";
CM_ SG_ 1140 EPAS_Invalid_Failure_Status "Status of the EPAS signal implausible  failure detected    as per  communication layer spec";
CM_ SG_ 1140 BCmMToFailureStatus "Status of the BCM Message timeout  failure detected as per Tata-IVN_Specification_Network_Management.";
CM_ SG_ 1140 EPAS_MTO_Failure_Status "Status of the EPAS  Message timeout failure detected as per Tata-IVN_Specification_Network_Management.";
CM_ SG_ 1140 EMS_BO_Failure_Status "Status of the bus off failure detected by EMS  ECU as per Tata-IVN_Specification_Network_Management.";
CM_ SG_ 1140 EMS_EP_Failure_Status "Status of the error-passive failure detected by EMS ECU as per Tata-IVN_Specification_Network_Management.";
CM_ SG_ 1140 ABS_ESP_MTO_Failure_Status "Status of the ESP  Message timeout failure detected as per Tata-IVN_Specification_Network_Management.";
CM_ SG_ 1140 PEPS_MTO_Failure_Status "Status of the PEPS  Message timeout  failure detected as per Tata-IVN_Specification_Network_Management.";
CM_ SG_ 1140 AT_AMT_DCT_Invalid_Failure_Statu "Status of the TCM invalid failure detected as per Tata-IVN_Specification_Network_Management.";
CM_ SG_ 1140 ABS_ESP_Invalid_Failure_Status "Status of the ESP signal implausible  failure detected  by EPAS  as per  communication layer spec";
CM_ SG_ 1140 IPcInvalidFailureStatus "Status of the IC Invalid  signal  failure detected as per Tata-IVN_Specification_Network_Management.";
CM_ SG_ 1140 IPcMToFailureStatus "Status of the IPC Message Timeout  failure detected as per Tata-IVN_Specification_Network_Management.";
CM_ SG_ 1140 CCM_MTO_Failure_Status "Status of the FATC Message timeout failure detected as per Tata-IVN_Specification_Network_Management.";
CM_ SG_ 1140 DCS_Invalid_Failure_Status "Status of the  DCS Invalid  signal  failure detected as per Tata-IVN_Specification_Network_Management.Status of the  DCS Invalid  signal  failure detected as per Tata-IVN_Specification_Network_Management.";
CM_ SG_ 1140 DCS_MTO_Failure_Status "Status of the DCS messege timeout";
CM_ SG_ 1140 ABS_ESP_MRC_Failure_Status "Status of the message rolling counter failure detected by IC ECU as per communication layer spec";
CM_ SG_ 1140 ABS_ESP_CRC_Failure_Status "Status of the cyclic reduntancy failure detected by IC ECU as per communication layer spec.";
CM_ SG_ 1140 SRS_MTO_Failure_Status "Status of the SRS  Message timeout  failure detected as per Tata-IVN_Specification_Network_Management.";
CM_ BO_ 1154 "Supervision frame transmitted by EPAS.";
CM_ SG_ 1154 EPAS_SW_Version "EPAS software version";
CM_ SG_ 1154 BattVolt_EPAS "Battery voltage of EPAS.";
CM_ SG_ 1154 ABsESpMRcFailureStatus "Status of the message rolling counter failure detected by IC ECU as per communication layer spec";
CM_ SG_ 1154 ABsESpCRcFailureStatus "Status of the cyclic reduntancy failure detected by IC ECU as per communication layer spec.";
CM_ SG_ 1154 EMsInvalidFailureStatus "status of the EMS Invalid  signal  failure detected as per Tata-IVN_Specification_Network_Management.";
CM_ SG_ 1154 ABsESpMToFailureStatus "Status of the ESP  Message timeout failure detected as per Tata-IVN_Specification_Network_Management.";
CM_ SG_ 1154 IPC_MRC_Failure_Status "Status of the message rolling counter failure detected by IC ECU as per communication layer spec";
CM_ SG_ 1154 IPC_CRC_Failure_Status "Status of the cyclic reduntancy failure detected by IC ECU as per communication layer spec.";
CM_ SG_ 1154 EPAS_EP_Failure_Status "Status of the error passive detected by EPAS ECU as per Tata-IVN_Specification_Network_Management.";
CM_ SG_ 1154 EPAS_BO_Failure_Status "Status of the bus-off failure detected by EPAS ECU as per Tata-IVN_Specification_Network_Management.";
CM_ SG_ 1154 IPcInvalidFailureStatus "Status of the IC Invalid  signal  failure detected as per Tata-IVN_Specification_Network_Management.";
CM_ SG_ 1154 BCM_MTO_Failure_status "Message timeout failure flag against BCM ECU";
CM_ SG_ 1154 IPcMToFailureStatus "Status of the IPC Message Timeout  failure detected as per Tata-IVN_Specification_Network_Management.";
CM_ SG_ 1154 EMsMToFailureStatus "Status of the EMS message timeout failure detected as per Tata-IVN_Specification_Network_Management.";
CM_ SG_ 1154 ABsESpInvalidFailureStatus "Status of the ESP signal implausible  failure detected  by EPAS  as per  communication layer spec";
CM_ SG_ 1154 AMT_AT_DCT_MTO_Failure_Status "Status of the TCM Message Timeout  failure detected as per Tata-IVN_Specification_Network_Management.";
CM_ SG_ 1154 AMT_AT_DCT_Invalid_Failure_Statu "Status of the TCM invalid failure detected as per Tata-IVN_Specification_Network_Management.";
BA_DEF_ SG_  "Remarks" STRING ;
BA_DEF_ SG_  "NWM_WakeupAllowed" ENUM  "No","Yes";
BA_DEF_ SG_  "GenSigTimeoutTime_HU_Mid_X451" INT 0 65535;
BA_DEF_ SG_  "GenSigTimeoutTime_HU_High_X451" INT 0 65535;
BA_DEF_ SG_  "GenSigTimeoutTime_HU_B" INT 0 65535;
BA_DEF_ SG_  "GenSigTimeoutTime_HU_A" INT 0 65535;
BA_DEF_ SG_  "GenSigTimeoutTime_BCM_Mid" INT 0 65535;
BA_DEF_ SG_  "GenSigTimeoutMsg_HU_Mid_X451" INT 0 65535;
BA_DEF_ SG_  "GenSigTimeoutMsg_HU_High_X451" INT 0 65535;
BA_DEF_ SG_  "GenSigTimeoutMsg_HU_B" INT 0 65535;
BA_DEF_ SG_  "GenSigTimeoutMsg_HU_A" INT 0 65535;
BA_DEF_ SG_  "GenSigStartValue" INT 0 0;
BA_DEF_ SG_  "GenSigSendType" ENUM  "Cyclic","OnWrite","OnWriteWithRepetition","OnChange","OnChangeWithRepetition","IfActive","IfActiveWithRepetition","NoSigSendType","NotUsed","NotUsed","NotUsed","NotUsed","NotUsed";
BA_DEF_ SG_  "GenSigInactiveValue" INT 0 0;
BA_DEF_ SG_  "GenSigEnvVarType" ENUM  "int","float","undef";
BA_DEF_ SG_  "GenSigCycleTimeActive" INT 0 0;
BA_DEF_ SG_  "GenSigCycleTime" INT 0 0;
BA_DEF_ SG_  "GenSigTimeoutMsg_HU_High_X445" INT 0 65535;
BA_DEF_ SG_  "GenSigTimeoutMsg_HU_Mid_X445" INT 0 65535;
BA_DEF_ SG_  "GenSigTimeoutTime_HU_High_X445" INT 0 65535;
BA_DEF_ SG_  "GenSigTimeoutTime_HU_Mid_X445" INT 0 65535;
BA_DEF_ SG_  "GenSigTimeoutMsg_IVI" INT 0 65535;
BA_DEF_ SG_  "GenSigTimeoutTime_IVI" INT 0 65535;
BA_DEF_ BO_  "NmMessage" ENUM  "no","yes";
BA_DEF_ BO_  "NmAsrMessage" ENUM  "<n.a.>","No","Yes";
BA_DEF_ BO_  "MessageTimeout" INT 0 65535;
BA_DEF_ BO_  "Me" INT 0 0;
BA_DEF_ BO_  "GenMsgStartDelayTime" INT 0 0;
BA_DEF_ BO_  "GenMsgSendType" ENUM  "Cyclic","NotUsed","NotUsed","NotUsed","NotUsed","NotUsed","NotUsed","IfActive","NoMsgSendType","NotUsed";
BA_DEF_ BO_  "GenMsgNrOfRepetition" INT 0 0;
BA_DEF_ BO_  "GenMsgILSupport" ENUM  "No","Yes";
BA_DEF_ BO_  "GenMsgDelayTime" INT 0 0;
BA_DEF_ BO_  "GenMsgCycleTimeFast" INT 0 0;
BA_DEF_ BO_  "GenMsgCycleTime" INT 0 0;
BA_DEF_ BO_  "DiagUudtResponse" ENUM  "false","true";
BA_DEF_ BO_  "DiagUsdtResponse" ENUM  "false","true";
BA_DEF_ BO_  "DiagState" ENUM  "No","Yes";
BA_DEF_ BO_  "DiagResponse" ENUM  "No","Yes";
BA_DEF_ BO_  "DiagRequest" ENUM  "No","Yes";
BA_DEF_ BO_  "MsgType" ENUM  "Application","NM","NMH";
BA_DEF_ SG_  "SystemSignalLongSymbol" STRING ;
BA_DEF_DEF_  "Remarks" "null";
BA_DEF_DEF_  "NWM_WakeupAllowed" "No";
BA_DEF_DEF_  "GenSigTimeoutTime_HU_Mid_X451" 500;
BA_DEF_DEF_  "GenSigTimeoutTime_HU_High_X451" 500;
BA_DEF_DEF_  "GenSigTimeoutTime_HU_B" 500;
BA_DEF_DEF_  "GenSigTimeoutTime_HU_A" 500;
BA_DEF_DEF_  "GenSigTimeoutTime_BCM_Mid" 0;
BA_DEF_DEF_  "GenSigTimeoutMsg_HU_Mid_X451" 500;
BA_DEF_DEF_  "GenSigTimeoutMsg_HU_High_X451" 500;
BA_DEF_DEF_  "GenSigTimeoutMsg_HU_B" 500;
BA_DEF_DEF_  "GenSigTimeoutMsg_HU_A" 500;
BA_DEF_DEF_  "GenSigStartValue" 0;
BA_DEF_DEF_  "GenSigSendType" "Cyclic";
BA_DEF_DEF_  "GenSigInactiveValue" 0;
BA_DEF_DEF_  "GenSigEnvVarType" "undef";
BA_DEF_DEF_  "GenSigCycleTimeActive" 0;
BA_DEF_DEF_  "GenSigCycleTime" 0;
BA_DEF_DEF_  "GenSigTimeoutMsg_HU_High_X445" 500;
BA_DEF_DEF_  "GenSigTimeoutMsg_HU_Mid_X445" 500;
BA_DEF_DEF_  "GenSigTimeoutTime_HU_High_X445" 500;
BA_DEF_DEF_  "GenSigTimeoutTime_HU_Mid_X445" 500;
BA_DEF_DEF_  "GenSigTimeoutMsg_IVI" 500;
BA_DEF_DEF_  "GenSigTimeoutTime_IVI" 500;
BA_DEF_DEF_  "NmMessage" "no";
BA_DEF_DEF_  "NmAsrMessage" "<n.a.>";
BA_DEF_DEF_  "MessageTimeout" 500;
BA_DEF_DEF_  "Me" 0;
BA_DEF_DEF_  "GenMsgStartDelayTime" 0;
BA_DEF_DEF_  "GenMsgSendType" "Cyclic";
BA_DEF_DEF_  "GenMsgNrOfRepetition" 0;
BA_DEF_DEF_  "GenMsgILSupport" "Yes";
BA_DEF_DEF_  "GenMsgDelayTime" 0;
BA_DEF_DEF_  "GenMsgCycleTimeFast" 0;
BA_DEF_DEF_  "GenMsgCycleTime" 0;
BA_DEF_DEF_  "DiagUudtResponse" "false";
BA_DEF_DEF_  "DiagUsdtResponse" "false";
BA_DEF_DEF_  "DiagState" "No";
BA_DEF_DEF_  "DiagResponse" "No";
BA_DEF_DEF_  "DiagRequest" "No";
BA_DEF_DEF_  "MsgType" "Application";
BA_DEF_DEF_  "SystemSignalLongSymbol" "";
BA_ "GenMsgCycleTime" BO_ 732 100;
BA_ "GenMsgCycleTime" BO_ 733 100;
BA_ "GenMsgCycleTime" BO_ 734 100;
BA_ "GenMsgCycleTime" BO_ 735 100;
BA_ "MessageTimeout" BO_ 744 1000;
BA_ "GenMsgCycleTime" BO_ 744 200;
BA_ "MessageTimeout" BO_ 928 2500;
BA_ "GenMsgCycleTime" BO_ 928 500;
BA_ "MessageTimeout" BO_ 929 2500;
BA_ "GenMsgCycleTime" BO_ 929 500;
BA_ "MessageTimeout" BO_ 930 2500;
BA_ "GenMsgCycleTime" BO_ 930 500;
BA_ "MessageTimeout" BO_ 931 2500;
BA_ "GenMsgCycleTime" BO_ 931 500;
BA_ "MessageTimeout" BO_ 932 2500;
BA_ "GenMsgCycleTime" BO_ 932 500;
BA_ "MessageTimeout" BO_ 938 2500;
BA_ "GenMsgStartDelayTime" BO_ 938 5;
BA_ "GenMsgCycleTime" BO_ 938 500;
BA_ "MessageTimeout" BO_ 946 2500;
BA_ "GenMsgCycleTime" BO_ 946 500;
BA_ "MessageTimeout" BO_ 948 2500;
BA_ "GenMsgCycleTime" BO_ 948 500;
BA_ "MessageTimeout" BO_ 950 2500;
BA_ "GenMsgCycleTime" BO_ 950 500;
BA_ "MessageTimeout" BO_ 1068 5000;
BA_ "GenMsgCycleTime" BO_ 1068 1000;
BA_ "MessageTimeout" BO_ 1069 5000;
BA_ "GenMsgCycleTime" BO_ 1069 1000;
BA_ "GenMsgCycleTime" BO_ 1104 100;
BA_ "MessageTimeout" BO_ 1120 0;
BA_ "GenMsgSendType" BO_ 1120 8;
BA_ "MessageTimeout" BO_ 1121 0;
BA_ "GenMsgSendType" BO_ 1121 8;
BA_ "GenMsgStartDelayTime" BO_ 1136 10;
BA_ "GenMsgCycleTime" BO_ 1136 100;
BA_ "MessageTimeout" BO_ 1140 0;
BA_ "GenMsgStartDelayTime" BO_ 1140 24;
BA_ "GenMsgCycleTime" BO_ 1140 100;
BA_ "MessageTimeout" BO_ 1154 0;
BA_ "GenMsgCycleTime" BO_ 1154 100;
BA_ "GenSigSendType" SG_ 732 TpmsTireSensorConfig 7;
BA_ "GenSigCycleTimeActive" SG_ 732 TpmsTireSensorConfig 100;
BA_ "GenSigCycleTime" SG_ 732 TpmsTireSensorConfig 100;
BA_ "GenSigSendType" SG_ 732 TPMSPresence 7;
BA_ "GenSigCycleTimeActive" SG_ 732 TPMSPresence 100;
BA_ "GenSigCycleTime" SG_ 732 TPMSPresence 100;
BA_ "GenSigSendType" SG_ 732 LowTirePresAlertSpare 7;
BA_ "GenSigCycleTimeActive" SG_ 732 LowTirePresAlertSpare 100;
BA_ "GenSigCycleTime" SG_ 732 LowTirePresAlertSpare 100;
BA_ "GenSigSendType" SG_ 732 LowTirePresAlertRL 7;
BA_ "GenSigCycleTimeActive" SG_ 732 LowTirePresAlertRL 100;
BA_ "GenSigCycleTime" SG_ 732 LowTirePresAlertRL 100;
BA_ "GenSigSendType" SG_ 732 LowTirePresAlertRR 7;
BA_ "GenSigCycleTimeActive" SG_ 732 LowTirePresAlertRR 100;
BA_ "GenSigCycleTime" SG_ 732 LowTirePresAlertRR 100;
BA_ "GenSigSendType" SG_ 732 LowTirePresAlertFR 7;
BA_ "GenSigCycleTimeActive" SG_ 732 LowTirePresAlertFR 100;
BA_ "GenSigCycleTime" SG_ 732 LowTirePresAlertFR 100;
BA_ "GenSigSendType" SG_ 732 LowTirePresAlertFL 7;
BA_ "GenSigCycleTimeActive" SG_ 732 LowTirePresAlertFL 100;
BA_ "GenSigCycleTime" SG_ 732 LowTirePresAlertFL 100;
BA_ "GenSigSendType" SG_ 732 HighTirePresAlertSpare 7;
BA_ "GenSigCycleTimeActive" SG_ 732 HighTirePresAlertSpare 100;
BA_ "GenSigCycleTime" SG_ 732 HighTirePresAlertSpare 100;
BA_ "GenSigSendType" SG_ 732 HighTirePresAlertRL 7;
BA_ "GenSigCycleTimeActive" SG_ 732 HighTirePresAlertRL 100;
BA_ "GenSigCycleTime" SG_ 732 HighTirePresAlertRL 100;
BA_ "GenSigSendType" SG_ 732 HighTirePresAlertRR 7;
BA_ "GenSigCycleTimeActive" SG_ 732 HighTirePresAlertRR 100;
BA_ "GenSigCycleTime" SG_ 732 HighTirePresAlertRR 100;
BA_ "GenSigSendType" SG_ 732 HighTirePresAlertFR 7;
BA_ "GenSigCycleTimeActive" SG_ 732 HighTirePresAlertFR 100;
BA_ "GenSigCycleTime" SG_ 732 HighTirePresAlertFR 100;
BA_ "GenSigSendType" SG_ 732 HighTirePresAlertFL 7;
BA_ "GenSigCycleTimeActive" SG_ 732 HighTirePresAlertFL 100;
BA_ "GenSigCycleTime" SG_ 732 HighTirePresAlertFL 100;
BA_ "GenSigSendType" SG_ 732 HighTireTempAlertSpare 7;
BA_ "GenSigCycleTimeActive" SG_ 732 HighTireTempAlertSpare 100;
BA_ "GenSigCycleTime" SG_ 732 HighTireTempAlertSpare 100;
BA_ "GenSigSendType" SG_ 732 HighTireTempAlertRL 7;
BA_ "GenSigCycleTimeActive" SG_ 732 HighTireTempAlertRL 100;
BA_ "GenSigCycleTime" SG_ 732 HighTireTempAlertRL 100;
BA_ "GenSigSendType" SG_ 732 HighTireTempAlertRR 7;
BA_ "GenSigCycleTimeActive" SG_ 732 HighTireTempAlertRR 100;
BA_ "GenSigCycleTime" SG_ 732 HighTireTempAlertRR 100;
BA_ "GenSigSendType" SG_ 732 HighTireTempAlertFR 7;
BA_ "GenSigCycleTimeActive" SG_ 732 HighTireTempAlertFR 100;
BA_ "GenSigCycleTime" SG_ 732 HighTireTempAlertFR 100;
BA_ "GenSigSendType" SG_ 732 HighTireTempAlertFL 7;
BA_ "GenSigCycleTimeActive" SG_ 732 HighTireTempAlertFL 100;
BA_ "GenSigCycleTime" SG_ 732 HighTireTempAlertFL 100;
BA_ "GenSigSendType" SG_ 732 PresLeakageAlertSpare 7;
BA_ "GenSigCycleTimeActive" SG_ 732 PresLeakageAlertSpare 100;
BA_ "GenSigCycleTime" SG_ 732 PresLeakageAlertSpare 100;
BA_ "GenSigSendType" SG_ 732 PresLeakageAlertRL 7;
BA_ "GenSigCycleTimeActive" SG_ 732 PresLeakageAlertRL 100;
BA_ "GenSigCycleTime" SG_ 732 PresLeakageAlertRL 100;
BA_ "GenSigSendType" SG_ 732 PresLeakageAlertRR 7;
BA_ "GenSigCycleTimeActive" SG_ 732 PresLeakageAlertRR 100;
BA_ "GenSigCycleTime" SG_ 732 PresLeakageAlertRR 100;
BA_ "GenSigSendType" SG_ 732 PresLeakageAlertFR 7;
BA_ "GenSigCycleTimeActive" SG_ 732 PresLeakageAlertFR 100;
BA_ "GenSigCycleTime" SG_ 732 PresLeakageAlertFR 100;
BA_ "GenSigSendType" SG_ 732 PresLeakageAlertFL 7;
BA_ "GenSigCycleTimeActive" SG_ 732 PresLeakageAlertFL 100;
BA_ "GenSigCycleTime" SG_ 732 PresLeakageAlertFL 100;
BA_ "GenSigSendType" SG_ 732 TpmsAlertStatus 7;
BA_ "GenSigCycleTimeActive" SG_ 732 TpmsAlertStatus 100;
BA_ "GenSigCycleTime" SG_ 732 TpmsAlertStatus 100;
BA_ "GenSigSendType" SG_ 732 TpmsReceiverRXFault 7;
BA_ "GenSigCycleTimeActive" SG_ 732 TpmsReceiverRXFault 100;
BA_ "GenSigCycleTime" SG_ 732 TpmsReceiverRXFault 100;
BA_ "GenSigSendType" SG_ 732 SensorMalfncFaultSpare 7;
BA_ "GenSigCycleTimeActive" SG_ 732 SensorMalfncFaultSpare 100;
BA_ "GenSigCycleTime" SG_ 732 SensorMalfncFaultSpare 100;
BA_ "GenSigSendType" SG_ 732 SensorMalfncFaultRL 7;
BA_ "GenSigCycleTimeActive" SG_ 732 SensorMalfncFaultRL 100;
BA_ "GenSigCycleTime" SG_ 732 SensorMalfncFaultRL 100;
BA_ "GenSigSendType" SG_ 732 SensorMalfncFaultRR 7;
BA_ "GenSigCycleTimeActive" SG_ 732 SensorMalfncFaultRR 100;
BA_ "GenSigCycleTime" SG_ 732 SensorMalfncFaultRR 100;
BA_ "GenSigSendType" SG_ 732 SensorMalfncFaultFR 7;
BA_ "GenSigCycleTimeActive" SG_ 732 SensorMalfncFaultFR 100;
BA_ "GenSigCycleTime" SG_ 732 SensorMalfncFaultFR 100;
BA_ "GenSigSendType" SG_ 732 SensorMalfncFaultFL 7;
BA_ "GenSigCycleTimeActive" SG_ 732 SensorMalfncFaultFL 100;
BA_ "GenSigCycleTime" SG_ 732 SensorMalfncFaultFL 100;
BA_ "GenSigSendType" SG_ 732 TpmsFaultStatus 7;
BA_ "GenSigCycleTimeActive" SG_ 732 TpmsFaultStatus 100;
BA_ "GenSigCycleTime" SG_ 732 TpmsFaultStatus 100;
BA_ "GenSigSendType" SG_ 732 TpmsNotLearntFault 7;
BA_ "GenSigCycleTimeActive" SG_ 732 TpmsNotLearntFault 100;
BA_ "GenSigCycleTime" SG_ 732 TpmsNotLearntFault 100;
BA_ "GenSigSendType" SG_ 732 SensorMissingFaultRL 7;
BA_ "GenSigCycleTimeActive" SG_ 732 SensorMissingFaultRL 100;
BA_ "GenSigCycleTime" SG_ 732 SensorMissingFaultRL 100;
BA_ "GenSigSendType" SG_ 732 SensorMissingFaultRR 7;
BA_ "GenSigCycleTimeActive" SG_ 732 SensorMissingFaultRR 100;
BA_ "GenSigCycleTime" SG_ 732 SensorMissingFaultRR 100;
BA_ "GenSigSendType" SG_ 732 SensorMissingFaultFR 7;
BA_ "GenSigCycleTimeActive" SG_ 732 SensorMissingFaultFR 100;
BA_ "GenSigCycleTime" SG_ 732 SensorMissingFaultFR 100;
BA_ "GenSigSendType" SG_ 732 SensorMissingFaultFL 7;
BA_ "GenSigCycleTimeActive" SG_ 732 SensorMissingFaultFL 100;
BA_ "GenSigCycleTime" SG_ 732 SensorMissingFaultFL 100;
BA_ "GenSigSendType" SG_ 732 TpmsLearnStatus 7;
BA_ "GenSigCycleTimeActive" SG_ 732 TpmsLearnStatus 100;
BA_ "GenSigCycleTime" SG_ 732 TpmsLearnStatus 100;
BA_ "GenSigSendType" SG_ 732 SpareTireSwapFlagRL 7;
BA_ "GenSigCycleTimeActive" SG_ 732 SpareTireSwapFlagRL 100;
BA_ "GenSigCycleTime" SG_ 732 SpareTireSwapFlagRL 100;
BA_ "GenSigSendType" SG_ 732 SpareTireSwapFlagRR 7;
BA_ "GenSigCycleTimeActive" SG_ 732 SpareTireSwapFlagRR 100;
BA_ "GenSigCycleTime" SG_ 732 SpareTireSwapFlagRR 100;
BA_ "GenSigSendType" SG_ 732 SpareTireSwapFlagFR 7;
BA_ "GenSigCycleTimeActive" SG_ 732 SpareTireSwapFlagFR 100;
BA_ "GenSigCycleTime" SG_ 732 SpareTireSwapFlagFR 100;
BA_ "GenSigSendType" SG_ 732 SpareTireSwapFlagFL 7;
BA_ "GenSigCycleTimeActive" SG_ 732 SpareTireSwapFlagFL 100;
BA_ "GenSigCycleTime" SG_ 732 SpareTireSwapFlagFL 100;
BA_ "GenSigSendType" SG_ 732 SensorLearningStatus 7;
BA_ "GenSigCycleTimeActive" SG_ 732 SensorLearningStatus 100;
BA_ "GenSigCycleTime" SG_ 732 SensorLearningStatus 100;
BA_ "GenSigSendType" SG_ 732 SensorDetectFlagSpare 7;
BA_ "GenSigCycleTimeActive" SG_ 732 SensorDetectFlagSpare 100;
BA_ "GenSigCycleTime" SG_ 732 SensorDetectFlagSpare 100;
BA_ "GenSigSendType" SG_ 732 SensorDetectFlagRL 7;
BA_ "GenSigCycleTimeActive" SG_ 732 SensorDetectFlagRL 100;
BA_ "GenSigCycleTime" SG_ 732 SensorDetectFlagRL 100;
BA_ "GenSigSendType" SG_ 732 SensorDetectFlagRR 7;
BA_ "GenSigCycleTimeActive" SG_ 732 SensorDetectFlagRR 100;
BA_ "GenSigCycleTime" SG_ 732 SensorDetectFlagRR 100;
BA_ "GenSigSendType" SG_ 732 SensorDetectFlagFR 7;
BA_ "GenSigCycleTimeActive" SG_ 732 SensorDetectFlagFR 100;
BA_ "GenSigCycleTime" SG_ 732 SensorDetectFlagFR 100;
BA_ "GenSigSendType" SG_ 732 SensorDetectFlagFL 7;
BA_ "GenSigCycleTimeActive" SG_ 732 SensorDetectFlagFL 100;
BA_ "GenSigCycleTime" SG_ 732 SensorDetectFlagFL 100;
BA_ "GenSigSendType" SG_ 733 SensorIDnotLearntSpare 7;
BA_ "GenSigCycleTimeActive" SG_ 733 SensorIDnotLearntSpare 100;
BA_ "GenSigCycleTime" SG_ 733 SensorIDnotLearntSpare 100;
BA_ "GenSigSendType" SG_ 733 SensorIDnotLearntRL 7;
BA_ "GenSigCycleTimeActive" SG_ 733 SensorIDnotLearntRL 100;
BA_ "GenSigCycleTime" SG_ 733 SensorIDnotLearntRL 100;
BA_ "GenSigSendType" SG_ 733 SensorIDnotLearntRR 7;
BA_ "GenSigCycleTimeActive" SG_ 733 SensorIDnotLearntRR 100;
BA_ "GenSigCycleTime" SG_ 733 SensorIDnotLearntRR 100;
BA_ "GenSigSendType" SG_ 733 SensorIDnotLearntFR 7;
BA_ "GenSigCycleTimeActive" SG_ 733 SensorIDnotLearntFR 100;
BA_ "GenSigCycleTime" SG_ 733 SensorIDnotLearntFR 100;
BA_ "GenSigSendType" SG_ 733 SensorIDnotLearntFL 7;
BA_ "GenSigCycleTimeActive" SG_ 733 SensorIDnotLearntFL 100;
BA_ "GenSigCycleTime" SG_ 733 SensorIDnotLearntFL 100;
BA_ "GenSigSendType" SG_ 733 TireFillAlertSpare 7;
BA_ "GenSigCycleTimeActive" SG_ 733 TireFillAlertSpare 100;
BA_ "GenSigCycleTime" SG_ 733 TireFillAlertSpare 100;
BA_ "GenSigSendType" SG_ 733 TireFillAlertRL 7;
BA_ "GenSigCycleTimeActive" SG_ 733 TireFillAlertRL 100;
BA_ "GenSigCycleTime" SG_ 733 TireFillAlertRL 100;
BA_ "GenSigSendType" SG_ 733 TireFillAlertRR 7;
BA_ "GenSigCycleTimeActive" SG_ 733 TireFillAlertRR 100;
BA_ "GenSigCycleTime" SG_ 733 TireFillAlertRR 100;
BA_ "GenSigSendType" SG_ 733 TireFillAlertFR 7;
BA_ "GenSigCycleTimeActive" SG_ 733 TireFillAlertFR 100;
BA_ "GenSigCycleTime" SG_ 733 TireFillAlertFR 100;
BA_ "GenSigSendType" SG_ 733 TireFillAlertFL 7;
BA_ "GenSigCycleTimeActive" SG_ 733 TireFillAlertFL 100;
BA_ "GenSigCycleTime" SG_ 733 TireFillAlertFL 100;
BA_ "GenSigSendType" SG_ 733 PresBurstAlertRL 7;
BA_ "GenSigCycleTimeActive" SG_ 733 PresBurstAlertRL 100;
BA_ "GenSigCycleTime" SG_ 733 PresBurstAlertRL 100;
BA_ "GenSigSendType" SG_ 733 PresBurstAlertRR 7;
BA_ "GenSigCycleTimeActive" SG_ 733 PresBurstAlertRR 100;
BA_ "GenSigCycleTime" SG_ 733 PresBurstAlertRR 100;
BA_ "GenSigSendType" SG_ 733 PresBurstAlertFR 7;
BA_ "GenSigCycleTimeActive" SG_ 733 PresBurstAlertFR 100;
BA_ "GenSigCycleTime" SG_ 733 PresBurstAlertFR 100;
BA_ "GenSigSendType" SG_ 733 PresBurstAlertFL 7;
BA_ "GenSigCycleTimeActive" SG_ 733 PresBurstAlertFL 100;
BA_ "GenSigCycleTime" SG_ 733 PresBurstAlertFL 100;
BA_ "GenSigSendType" SG_ 734 TirePressureFL 7;
BA_ "GenSigCycleTimeActive" SG_ 734 TirePressureFL 100;
BA_ "GenSigCycleTime" SG_ 734 TirePressureFL 100;
BA_ "GenSigSendType" SG_ 734 TirePressureFR 7;
BA_ "GenSigCycleTimeActive" SG_ 734 TirePressureFR 100;
BA_ "GenSigCycleTime" SG_ 734 TirePressureFR 100;
BA_ "GenSigSendType" SG_ 734 TirePressureRR 7;
BA_ "GenSigCycleTimeActive" SG_ 734 TirePressureRR 100;
BA_ "GenSigCycleTime" SG_ 734 TirePressureRR 100;
BA_ "GenSigSendType" SG_ 734 TirePressureRL 7;
BA_ "GenSigCycleTimeActive" SG_ 734 TirePressureRL 100;
BA_ "GenSigCycleTime" SG_ 734 TirePressureRL 100;
BA_ "GenSigSendType" SG_ 734 TirePressureSpare 7;
BA_ "GenSigCycleTimeActive" SG_ 734 TirePressureSpare 100;
BA_ "GenSigCycleTime" SG_ 734 TirePressureSpare 100;
BA_ "GenSigStartValue" SG_ 735 TireTemperatureFL 40;
BA_ "GenSigSendType" SG_ 735 TireTemperatureFL 7;
BA_ "GenSigCycleTimeActive" SG_ 735 TireTemperatureFL 100;
BA_ "GenSigCycleTime" SG_ 735 TireTemperatureFL 100;
BA_ "GenSigStartValue" SG_ 735 TireTemperatureFR 40;
BA_ "GenSigSendType" SG_ 735 TireTemperatureFR 7;
BA_ "GenSigCycleTimeActive" SG_ 735 TireTemperatureFR 100;
BA_ "GenSigCycleTime" SG_ 735 TireTemperatureFR 100;
BA_ "GenSigStartValue" SG_ 735 TireTemperatureRR 40;
BA_ "GenSigSendType" SG_ 735 TireTemperatureRR 7;
BA_ "GenSigCycleTimeActive" SG_ 735 TireTemperatureRR 100;
BA_ "GenSigCycleTime" SG_ 735 TireTemperatureRR 100;
BA_ "GenSigStartValue" SG_ 735 TireTemperatureRL 40;
BA_ "GenSigSendType" SG_ 735 TireTemperatureRL 7;
BA_ "GenSigCycleTimeActive" SG_ 735 TireTemperatureRL 100;
BA_ "GenSigCycleTime" SG_ 735 TireTemperatureRL 100;
BA_ "GenSigStartValue" SG_ 735 TireTemperatureSpare 40;
BA_ "GenSigSendType" SG_ 735 TireTemperatureSpare 7;
BA_ "GenSigCycleTimeActive" SG_ 735 TireTemperatureSpare 100;
BA_ "GenSigCycleTime" SG_ 735 TireTemperatureSpare 100;
BA_ "GenSigTimeoutTime_HU_Mid_X451" SG_ 744 HuCCmFanSpdDuringVR 1000;
BA_ "GenSigTimeoutTime_HU_High_X451" SG_ 744 HuCCmFanSpdDuringVR 1000;
BA_ "GenSigTimeoutTime_HU_B" SG_ 744 HuCCmFanSpdDuringVR 1000;
BA_ "GenSigTimeoutTime_HU_A" SG_ 744 HuCCmFanSpdDuringVR 1000;
BA_ "GenSigTimeoutMsg_HU_Mid_X451" SG_ 744 HuCCmFanSpdDuringVR 1000;
BA_ "GenSigTimeoutMsg_HU_High_X451" SG_ 744 HuCCmFanSpdDuringVR 1000;
BA_ "GenSigTimeoutMsg_HU_B" SG_ 744 HuCCmFanSpdDuringVR 1000;
BA_ "GenSigTimeoutMsg_HU_A" SG_ 744 HuCCmFanSpdDuringVR 1000;
BA_ "GenSigSendType" SG_ 744 HuCCmFanSpdDuringVR 7;
BA_ "GenSigCycleTimeActive" SG_ 744 HuCCmFanSpdDuringVR 200;
BA_ "GenSigCycleTime" SG_ 744 HuCCmFanSpdDuringVR 200;
BA_ "GenSigTimeoutMsg_HU_High_X445" SG_ 744 HuCCmFanSpdDuringVR 1000;
BA_ "GenSigTimeoutMsg_HU_Mid_X445" SG_ 744 HuCCmFanSpdDuringVR 1000;
BA_ "GenSigTimeoutTime_HU_High_X445" SG_ 744 HuCCmFanSpdDuringVR 1000;
BA_ "GenSigTimeoutTime_HU_Mid_X445" SG_ 744 HuCCmFanSpdDuringVR 1000;
BA_ "GenSigTimeoutMsg_IVI" SG_ 744 HuCCmFanSpdDuringVR 1000;
BA_ "GenSigTimeoutTime_IVI" SG_ 744 HuCCmFanSpdDuringVR 1000;
BA_ "GenSigTimeoutTime_HU_Mid_X451" SG_ 744 HuCCmVRSession 1000;
BA_ "GenSigTimeoutTime_HU_High_X451" SG_ 744 HuCCmVRSession 1000;
BA_ "GenSigTimeoutTime_HU_B" SG_ 744 HuCCmVRSession 1000;
BA_ "GenSigTimeoutTime_HU_A" SG_ 744 HuCCmVRSession 1000;
BA_ "GenSigTimeoutMsg_HU_Mid_X451" SG_ 744 HuCCmVRSession 1000;
BA_ "GenSigTimeoutMsg_HU_High_X451" SG_ 744 HuCCmVRSession 1000;
BA_ "GenSigTimeoutMsg_HU_B" SG_ 744 HuCCmVRSession 1000;
BA_ "GenSigTimeoutMsg_HU_A" SG_ 744 HuCCmVRSession 1000;
BA_ "GenSigSendType" SG_ 744 HuCCmVRSession 7;
BA_ "GenSigCycleTimeActive" SG_ 744 HuCCmVRSession 200;
BA_ "GenSigCycleTime" SG_ 744 HuCCmVRSession 200;
BA_ "GenSigTimeoutMsg_HU_High_X445" SG_ 744 HuCCmVRSession 1000;
BA_ "GenSigTimeoutMsg_HU_Mid_X445" SG_ 744 HuCCmVRSession 1000;
BA_ "GenSigTimeoutTime_HU_High_X445" SG_ 744 HuCCmVRSession 1000;
BA_ "GenSigTimeoutTime_HU_Mid_X445" SG_ 744 HuCCmVRSession 1000;
BA_ "GenSigTimeoutMsg_IVI" SG_ 744 HuCCmVRSession 1000;
BA_ "GenSigTimeoutTime_IVI" SG_ 744 HuCCmVRSession 1000;
BA_ "GenSigTimeoutTime_HU_Mid_X451" SG_ 928 TripDuration_TripA 2500;
BA_ "GenSigTimeoutTime_HU_High_X451" SG_ 928 TripDuration_TripA 2500;
BA_ "GenSigTimeoutTime_HU_B" SG_ 928 TripDuration_TripA 2500;
BA_ "GenSigTimeoutTime_HU_A" SG_ 928 TripDuration_TripA 2500;
BA_ "GenSigTimeoutMsg_HU_Mid_X451" SG_ 928 TripDuration_TripA 2500;
BA_ "GenSigTimeoutMsg_HU_High_X451" SG_ 928 TripDuration_TripA 2500;
BA_ "GenSigTimeoutMsg_HU_B" SG_ 928 TripDuration_TripA 2500;
BA_ "GenSigTimeoutMsg_HU_A" SG_ 928 TripDuration_TripA 2500;
BA_ "GenSigSendType" SG_ 928 TripDuration_TripA 7;
BA_ "GenSigCycleTimeActive" SG_ 928 TripDuration_TripA 500;
BA_ "GenSigCycleTime" SG_ 928 TripDuration_TripA 500;
BA_ "GenSigTimeoutMsg_HU_High_X445" SG_ 928 TripDuration_TripA 2500;
BA_ "GenSigTimeoutMsg_HU_Mid_X445" SG_ 928 TripDuration_TripA 2500;
BA_ "GenSigTimeoutTime_HU_High_X445" SG_ 928 TripDuration_TripA 2500;
BA_ "GenSigTimeoutTime_HU_Mid_X445" SG_ 928 TripDuration_TripA 2500;
BA_ "GenSigTimeoutMsg_IVI" SG_ 928 TripDuration_TripA 2500;
BA_ "GenSigTimeoutTime_IVI" SG_ 928 TripDuration_TripA 2500;
BA_ "GenSigTimeoutTime_HU_Mid_X451" SG_ 928 AvgSpd_TripA 2500;
BA_ "GenSigTimeoutTime_HU_High_X451" SG_ 928 AvgSpd_TripA 2500;
BA_ "GenSigTimeoutTime_HU_B" SG_ 928 AvgSpd_TripA 2500;
BA_ "GenSigTimeoutTime_HU_A" SG_ 928 AvgSpd_TripA 2500;
BA_ "GenSigTimeoutMsg_HU_Mid_X451" SG_ 928 AvgSpd_TripA 2500;
BA_ "GenSigTimeoutMsg_HU_High_X451" SG_ 928 AvgSpd_TripA 2500;
BA_ "GenSigTimeoutMsg_HU_B" SG_ 928 AvgSpd_TripA 2500;
BA_ "GenSigTimeoutMsg_HU_A" SG_ 928 AvgSpd_TripA 2500;
BA_ "GenSigSendType" SG_ 928 AvgSpd_TripA 7;
BA_ "GenSigCycleTimeActive" SG_ 928 AvgSpd_TripA 500;
BA_ "GenSigCycleTime" SG_ 928 AvgSpd_TripA 500;
BA_ "GenSigTimeoutMsg_HU_High_X445" SG_ 928 AvgSpd_TripA 2500;
BA_ "GenSigTimeoutMsg_HU_Mid_X445" SG_ 928 AvgSpd_TripA 2500;
BA_ "GenSigTimeoutTime_HU_High_X445" SG_ 928 AvgSpd_TripA 2500;
BA_ "GenSigTimeoutTime_HU_Mid_X445" SG_ 928 AvgSpd_TripA 2500;
BA_ "GenSigTimeoutMsg_IVI" SG_ 928 AvgSpd_TripA 2500;
BA_ "GenSigTimeoutTime_IVI" SG_ 928 AvgSpd_TripA 2500;
BA_ "GenSigTimeoutTime_HU_Mid_X451" SG_ 928 TripDistance_TripA 2500;
BA_ "GenSigTimeoutTime_HU_High_X451" SG_ 928 TripDistance_TripA 2500;
BA_ "GenSigTimeoutTime_HU_B" SG_ 928 TripDistance_TripA 2500;
BA_ "GenSigTimeoutTime_HU_A" SG_ 928 TripDistance_TripA 2500;
BA_ "GenSigTimeoutMsg_HU_Mid_X451" SG_ 928 TripDistance_TripA 2500;
BA_ "GenSigTimeoutMsg_HU_High_X451" SG_ 928 TripDistance_TripA 2500;
BA_ "GenSigTimeoutMsg_HU_B" SG_ 928 TripDistance_TripA 2500;
BA_ "GenSigTimeoutMsg_HU_A" SG_ 928 TripDistance_TripA 2500;
BA_ "GenSigSendType" SG_ 928 TripDistance_TripA 7;
BA_ "GenSigCycleTimeActive" SG_ 928 TripDistance_TripA 500;
BA_ "GenSigCycleTime" SG_ 928 TripDistance_TripA 500;
BA_ "GenSigTimeoutMsg_HU_High_X445" SG_ 928 TripDistance_TripA 2500;
BA_ "GenSigTimeoutMsg_HU_Mid_X445" SG_ 928 TripDistance_TripA 2500;
BA_ "GenSigTimeoutTime_HU_High_X445" SG_ 928 TripDistance_TripA 2500;
BA_ "GenSigTimeoutTime_HU_Mid_X445" SG_ 928 TripDistance_TripA 2500;
BA_ "GenSigTimeoutMsg_IVI" SG_ 928 TripDistance_TripA 2500;
BA_ "GenSigTimeoutTime_IVI" SG_ 928 TripDistance_TripA 2500;
BA_ "GenSigTimeoutTime_HU_Mid_X451" SG_ 928 AvgFuelEconomy_TripA 2500;
BA_ "GenSigTimeoutTime_HU_High_X451" SG_ 928 AvgFuelEconomy_TripA 2500;
BA_ "GenSigTimeoutTime_HU_B" SG_ 928 AvgFuelEconomy_TripA 2500;
BA_ "GenSigTimeoutTime_HU_A" SG_ 928 AvgFuelEconomy_TripA 2500;
BA_ "GenSigTimeoutMsg_HU_Mid_X451" SG_ 928 AvgFuelEconomy_TripA 2500;
BA_ "GenSigTimeoutMsg_HU_High_X451" SG_ 928 AvgFuelEconomy_TripA 2500;
BA_ "GenSigTimeoutMsg_HU_B" SG_ 928 AvgFuelEconomy_TripA 2500;
BA_ "GenSigTimeoutMsg_HU_A" SG_ 928 AvgFuelEconomy_TripA 2500;
BA_ "GenSigSendType" SG_ 928 AvgFuelEconomy_TripA 7;
BA_ "GenSigCycleTimeActive" SG_ 928 AvgFuelEconomy_TripA 500;
BA_ "GenSigCycleTime" SG_ 928 AvgFuelEconomy_TripA 500;
BA_ "GenSigTimeoutMsg_HU_High_X445" SG_ 928 AvgFuelEconomy_TripA 2500;
BA_ "GenSigTimeoutMsg_HU_Mid_X445" SG_ 928 AvgFuelEconomy_TripA 2500;
BA_ "GenSigTimeoutTime_HU_High_X445" SG_ 928 AvgFuelEconomy_TripA 2500;
BA_ "GenSigTimeoutTime_HU_Mid_X445" SG_ 928 AvgFuelEconomy_TripA 2500;
BA_ "GenSigTimeoutMsg_IVI" SG_ 928 AvgFuelEconomy_TripA 2500;
BA_ "GenSigTimeoutTime_IVI" SG_ 928 AvgFuelEconomy_TripA 2500;
BA_ "GenSigTimeoutTime_HU_Mid_X451" SG_ 929 TripDuration_TripB 2500;
BA_ "GenSigTimeoutTime_HU_High_X451" SG_ 929 TripDuration_TripB 2500;
BA_ "GenSigTimeoutTime_HU_B" SG_ 929 TripDuration_TripB 2500;
BA_ "GenSigTimeoutTime_HU_A" SG_ 929 TripDuration_TripB 2500;
BA_ "GenSigTimeoutMsg_HU_Mid_X451" SG_ 929 TripDuration_TripB 2500;
BA_ "GenSigTimeoutMsg_HU_High_X451" SG_ 929 TripDuration_TripB 2500;
BA_ "GenSigTimeoutMsg_HU_B" SG_ 929 TripDuration_TripB 2500;
BA_ "GenSigTimeoutMsg_HU_A" SG_ 929 TripDuration_TripB 2500;
BA_ "GenSigSendType" SG_ 929 TripDuration_TripB 7;
BA_ "GenSigCycleTimeActive" SG_ 929 TripDuration_TripB 500;
BA_ "GenSigCycleTime" SG_ 929 TripDuration_TripB 500;
BA_ "GenSigTimeoutMsg_HU_High_X445" SG_ 929 TripDuration_TripB 2500;
BA_ "GenSigTimeoutMsg_HU_Mid_X445" SG_ 929 TripDuration_TripB 2500;
BA_ "GenSigTimeoutTime_HU_High_X445" SG_ 929 TripDuration_TripB 2500;
BA_ "GenSigTimeoutTime_HU_Mid_X445" SG_ 929 TripDuration_TripB 2500;
BA_ "GenSigTimeoutMsg_IVI" SG_ 929 TripDuration_TripB 2500;
BA_ "GenSigTimeoutTime_IVI" SG_ 929 TripDuration_TripB 2500;
BA_ "GenSigTimeoutTime_HU_Mid_X451" SG_ 929 AvgSpd_TripB 2500;
BA_ "GenSigTimeoutTime_HU_High_X451" SG_ 929 AvgSpd_TripB 2500;
BA_ "GenSigTimeoutTime_HU_B" SG_ 929 AvgSpd_TripB 2500;
BA_ "GenSigTimeoutTime_HU_A" SG_ 929 AvgSpd_TripB 2500;
BA_ "GenSigTimeoutMsg_HU_Mid_X451" SG_ 929 AvgSpd_TripB 2500;
BA_ "GenSigTimeoutMsg_HU_High_X451" SG_ 929 AvgSpd_TripB 2500;
BA_ "GenSigTimeoutMsg_HU_B" SG_ 929 AvgSpd_TripB 2500;
BA_ "GenSigTimeoutMsg_HU_A" SG_ 929 AvgSpd_TripB 2500;
BA_ "GenSigSendType" SG_ 929 AvgSpd_TripB 7;
BA_ "GenSigCycleTimeActive" SG_ 929 AvgSpd_TripB 500;
BA_ "GenSigCycleTime" SG_ 929 AvgSpd_TripB 500;
BA_ "GenSigTimeoutMsg_HU_High_X445" SG_ 929 AvgSpd_TripB 2500;
BA_ "GenSigTimeoutMsg_HU_Mid_X445" SG_ 929 AvgSpd_TripB 2500;
BA_ "GenSigTimeoutTime_HU_High_X445" SG_ 929 AvgSpd_TripB 2500;
BA_ "GenSigTimeoutTime_HU_Mid_X445" SG_ 929 AvgSpd_TripB 2500;
BA_ "GenSigTimeoutMsg_IVI" SG_ 929 AvgSpd_TripB 2500;
BA_ "GenSigTimeoutTime_IVI" SG_ 929 AvgSpd_TripB 2500;
BA_ "GenSigTimeoutTime_HU_Mid_X451" SG_ 929 AvgFuelEconomy_TripB 2500;
BA_ "GenSigTimeoutTime_HU_High_X451" SG_ 929 AvgFuelEconomy_TripB 2500;
BA_ "GenSigTimeoutTime_HU_B" SG_ 929 AvgFuelEconomy_TripB 2500;
BA_ "GenSigTimeoutTime_HU_A" SG_ 929 AvgFuelEconomy_TripB 2500;
BA_ "GenSigTimeoutMsg_HU_Mid_X451" SG_ 929 AvgFuelEconomy_TripB 2500;
BA_ "GenSigTimeoutMsg_HU_High_X451" SG_ 929 AvgFuelEconomy_TripB 2500;
BA_ "GenSigTimeoutMsg_HU_B" SG_ 929 AvgFuelEconomy_TripB 2500;
BA_ "GenSigTimeoutMsg_HU_A" SG_ 929 AvgFuelEconomy_TripB 2500;
BA_ "GenSigSendType" SG_ 929 AvgFuelEconomy_TripB 7;
BA_ "GenSigCycleTimeActive" SG_ 929 AvgFuelEconomy_TripB 500;
BA_ "GenSigCycleTime" SG_ 929 AvgFuelEconomy_TripB 500;
BA_ "GenSigTimeoutMsg_HU_High_X445" SG_ 929 AvgFuelEconomy_TripB 2500;
BA_ "GenSigTimeoutMsg_HU_Mid_X445" SG_ 929 AvgFuelEconomy_TripB 2500;
BA_ "GenSigTimeoutTime_HU_High_X445" SG_ 929 AvgFuelEconomy_TripB 2500;
BA_ "GenSigTimeoutTime_HU_Mid_X445" SG_ 929 AvgFuelEconomy_TripB 2500;
BA_ "GenSigTimeoutMsg_IVI" SG_ 929 AvgFuelEconomy_TripB 2500;
BA_ "GenSigTimeoutTime_IVI" SG_ 929 AvgFuelEconomy_TripB 2500;
BA_ "GenSigTimeoutTime_HU_Mid_X451" SG_ 929 TripDistance_TripB 2500;
BA_ "GenSigTimeoutTime_HU_High_X451" SG_ 929 TripDistance_TripB 2500;
BA_ "GenSigTimeoutTime_HU_B" SG_ 929 TripDistance_TripB 2500;
BA_ "GenSigTimeoutTime_HU_A" SG_ 929 TripDistance_TripB 2500;
BA_ "GenSigTimeoutMsg_HU_Mid_X451" SG_ 929 TripDistance_TripB 2500;
BA_ "GenSigTimeoutMsg_HU_High_X451" SG_ 929 TripDistance_TripB 2500;
BA_ "GenSigTimeoutMsg_HU_B" SG_ 929 TripDistance_TripB 2500;
BA_ "GenSigTimeoutMsg_HU_A" SG_ 929 TripDistance_TripB 2500;
BA_ "GenSigSendType" SG_ 929 TripDistance_TripB 7;
BA_ "GenSigCycleTimeActive" SG_ 929 TripDistance_TripB 500;
BA_ "GenSigCycleTime" SG_ 929 TripDistance_TripB 500;
BA_ "GenSigTimeoutMsg_HU_High_X445" SG_ 929 TripDistance_TripB 2500;
BA_ "GenSigTimeoutMsg_HU_Mid_X445" SG_ 929 TripDistance_TripB 2500;
BA_ "GenSigTimeoutTime_HU_High_X445" SG_ 929 TripDistance_TripB 2500;
BA_ "GenSigTimeoutTime_HU_Mid_X445" SG_ 929 TripDistance_TripB 2500;
BA_ "GenSigTimeoutMsg_IVI" SG_ 929 TripDistance_TripB 2500;
BA_ "GenSigTimeoutTime_IVI" SG_ 929 TripDistance_TripB 2500;
BA_ "GenSigTimeoutTime_HU_Mid_X451" SG_ 930 TripDuration_OverallTrip 2500;
BA_ "GenSigTimeoutTime_HU_High_X451" SG_ 930 TripDuration_OverallTrip 2500;
BA_ "GenSigTimeoutTime_HU_B" SG_ 930 TripDuration_OverallTrip 2500;
BA_ "GenSigTimeoutTime_HU_A" SG_ 930 TripDuration_OverallTrip 2500;
BA_ "GenSigTimeoutMsg_HU_Mid_X451" SG_ 930 TripDuration_OverallTrip 2500;
BA_ "GenSigTimeoutMsg_HU_High_X451" SG_ 930 TripDuration_OverallTrip 2500;
BA_ "GenSigTimeoutMsg_HU_B" SG_ 930 TripDuration_OverallTrip 2500;
BA_ "GenSigTimeoutMsg_HU_A" SG_ 930 TripDuration_OverallTrip 2500;
BA_ "GenSigSendType" SG_ 930 TripDuration_OverallTrip 7;
BA_ "GenSigCycleTimeActive" SG_ 930 TripDuration_OverallTrip 500;
BA_ "GenSigCycleTime" SG_ 930 TripDuration_OverallTrip 500;
BA_ "GenSigTimeoutMsg_HU_High_X445" SG_ 930 TripDuration_OverallTrip 2500;
BA_ "GenSigTimeoutMsg_HU_Mid_X445" SG_ 930 TripDuration_OverallTrip 2500;
BA_ "GenSigTimeoutTime_HU_High_X445" SG_ 930 TripDuration_OverallTrip 2500;
BA_ "GenSigTimeoutTime_HU_Mid_X445" SG_ 930 TripDuration_OverallTrip 2500;
BA_ "GenSigTimeoutMsg_IVI" SG_ 930 TripDuration_OverallTrip 2500;
BA_ "GenSigTimeoutTime_IVI" SG_ 930 TripDuration_OverallTrip 2500;
BA_ "GenSigTimeoutTime_HU_Mid_X451" SG_ 930 AvgSpeed_OverallTrip 2500;
BA_ "GenSigTimeoutTime_HU_High_X451" SG_ 930 AvgSpeed_OverallTrip 2500;
BA_ "GenSigTimeoutTime_HU_B" SG_ 930 AvgSpeed_OverallTrip 2500;
BA_ "GenSigTimeoutTime_HU_A" SG_ 930 AvgSpeed_OverallTrip 2500;
BA_ "GenSigTimeoutMsg_HU_Mid_X451" SG_ 930 AvgSpeed_OverallTrip 2500;
BA_ "GenSigTimeoutMsg_HU_High_X451" SG_ 930 AvgSpeed_OverallTrip 2500;
BA_ "GenSigTimeoutMsg_HU_B" SG_ 930 AvgSpeed_OverallTrip 2500;
BA_ "GenSigTimeoutMsg_HU_A" SG_ 930 AvgSpeed_OverallTrip 2500;
BA_ "GenSigSendType" SG_ 930 AvgSpeed_OverallTrip 7;
BA_ "GenSigCycleTimeActive" SG_ 930 AvgSpeed_OverallTrip 500;
BA_ "GenSigCycleTime" SG_ 930 AvgSpeed_OverallTrip 500;
BA_ "GenSigTimeoutMsg_HU_High_X445" SG_ 930 AvgSpeed_OverallTrip 2500;
BA_ "GenSigTimeoutMsg_HU_Mid_X445" SG_ 930 AvgSpeed_OverallTrip 2500;
BA_ "GenSigTimeoutTime_HU_High_X445" SG_ 930 AvgSpeed_OverallTrip 2500;
BA_ "GenSigTimeoutTime_HU_Mid_X445" SG_ 930 AvgSpeed_OverallTrip 2500;
BA_ "GenSigTimeoutMsg_IVI" SG_ 930 AvgSpeed_OverallTrip 2500;
BA_ "GenSigTimeoutTime_IVI" SG_ 930 AvgSpeed_OverallTrip 2500;
BA_ "GenSigTimeoutTime_HU_Mid_X451" SG_ 930 TripDistance_OverAllTrip 2500;
BA_ "GenSigTimeoutTime_HU_High_X451" SG_ 930 TripDistance_OverAllTrip 2500;
BA_ "GenSigTimeoutTime_HU_B" SG_ 930 TripDistance_OverAllTrip 2500;
BA_ "GenSigTimeoutTime_HU_A" SG_ 930 TripDistance_OverAllTrip 2500;
BA_ "GenSigTimeoutMsg_HU_Mid_X451" SG_ 930 TripDistance_OverAllTrip 2500;
BA_ "GenSigTimeoutMsg_HU_High_X451" SG_ 930 TripDistance_OverAllTrip 2500;
BA_ "GenSigTimeoutMsg_HU_B" SG_ 930 TripDistance_OverAllTrip 2500;
BA_ "GenSigTimeoutMsg_HU_A" SG_ 930 TripDistance_OverAllTrip 2500;
BA_ "GenSigSendType" SG_ 930 TripDistance_OverAllTrip 7;
BA_ "GenSigCycleTimeActive" SG_ 930 TripDistance_OverAllTrip 500;
BA_ "GenSigCycleTime" SG_ 930 TripDistance_OverAllTrip 500;
BA_ "GenSigTimeoutMsg_HU_High_X445" SG_ 930 TripDistance_OverAllTrip 2500;
BA_ "GenSigTimeoutMsg_HU_Mid_X445" SG_ 930 TripDistance_OverAllTrip 2500;
BA_ "GenSigTimeoutTime_HU_High_X445" SG_ 930 TripDistance_OverAllTrip 2500;
BA_ "GenSigTimeoutTime_HU_Mid_X445" SG_ 930 TripDistance_OverAllTrip 2500;
BA_ "GenSigTimeoutMsg_IVI" SG_ 930 TripDistance_OverAllTrip 2500;
BA_ "GenSigTimeoutTime_IVI" SG_ 930 TripDistance_OverAllTrip 2500;
BA_ "GenSigTimeoutTime_HU_Mid_X451" SG_ 930 AvgFuelEconomy_OverallTrip 2500;
BA_ "GenSigTimeoutTime_HU_High_X451" SG_ 930 AvgFuelEconomy_OverallTrip 2500;
BA_ "GenSigTimeoutTime_HU_B" SG_ 930 AvgFuelEconomy_OverallTrip 2500;
BA_ "GenSigTimeoutTime_HU_A" SG_ 930 AvgFuelEconomy_OverallTrip 2500;
BA_ "GenSigTimeoutMsg_HU_Mid_X451" SG_ 930 AvgFuelEconomy_OverallTrip 2500;
BA_ "GenSigTimeoutMsg_HU_High_X451" SG_ 930 AvgFuelEconomy_OverallTrip 2500;
BA_ "GenSigTimeoutMsg_HU_B" SG_ 930 AvgFuelEconomy_OverallTrip 2500;
BA_ "GenSigTimeoutMsg_HU_A" SG_ 930 AvgFuelEconomy_OverallTrip 2500;
BA_ "GenSigSendType" SG_ 930 AvgFuelEconomy_OverallTrip 7;
BA_ "GenSigCycleTimeActive" SG_ 930 AvgFuelEconomy_OverallTrip 500;
BA_ "GenSigCycleTime" SG_ 930 AvgFuelEconomy_OverallTrip 500;
BA_ "GenSigTimeoutMsg_HU_High_X445" SG_ 930 AvgFuelEconomy_OverallTrip 2500;
BA_ "GenSigTimeoutMsg_HU_Mid_X445" SG_ 930 AvgFuelEconomy_OverallTrip 2500;
BA_ "GenSigTimeoutTime_HU_High_X445" SG_ 930 AvgFuelEconomy_OverallTrip 2500;
BA_ "GenSigTimeoutTime_HU_Mid_X445" SG_ 930 AvgFuelEconomy_OverallTrip 2500;
BA_ "GenSigTimeoutMsg_IVI" SG_ 930 AvgFuelEconomy_OverallTrip 2500;
BA_ "GenSigTimeoutTime_IVI" SG_ 930 AvgFuelEconomy_OverallTrip 2500;
BA_ "GenSigTimeoutTime_HU_Mid_X451" SG_ 931 TripDuration_CurrentTrip 2500;
BA_ "GenSigTimeoutTime_HU_High_X451" SG_ 931 TripDuration_CurrentTrip 2500;
BA_ "GenSigTimeoutTime_HU_B" SG_ 931 TripDuration_CurrentTrip 2500;
BA_ "GenSigTimeoutTime_HU_A" SG_ 931 TripDuration_CurrentTrip 2500;
BA_ "GenSigTimeoutMsg_HU_Mid_X451" SG_ 931 TripDuration_CurrentTrip 2500;
BA_ "GenSigTimeoutMsg_HU_High_X451" SG_ 931 TripDuration_CurrentTrip 2500;
BA_ "GenSigTimeoutMsg_HU_B" SG_ 931 TripDuration_CurrentTrip 2500;
BA_ "GenSigTimeoutMsg_HU_A" SG_ 931 TripDuration_CurrentTrip 2500;
BA_ "GenSigSendType" SG_ 931 TripDuration_CurrentTrip 7;
BA_ "GenSigCycleTimeActive" SG_ 931 TripDuration_CurrentTrip 500;
BA_ "GenSigCycleTime" SG_ 931 TripDuration_CurrentTrip 500;
BA_ "GenSigTimeoutMsg_HU_High_X445" SG_ 931 TripDuration_CurrentTrip 2500;
BA_ "GenSigTimeoutMsg_HU_Mid_X445" SG_ 931 TripDuration_CurrentTrip 2500;
BA_ "GenSigTimeoutTime_HU_High_X445" SG_ 931 TripDuration_CurrentTrip 2500;
BA_ "GenSigTimeoutTime_HU_Mid_X445" SG_ 931 TripDuration_CurrentTrip 2500;
BA_ "GenSigTimeoutMsg_IVI" SG_ 931 TripDuration_CurrentTrip 2500;
BA_ "GenSigTimeoutTime_IVI" SG_ 931 TripDuration_CurrentTrip 2500;
BA_ "GenSigTimeoutTime_HU_Mid_X451" SG_ 931 AvgFuelEconomy_Currenttrip 2500;
BA_ "GenSigTimeoutTime_HU_High_X451" SG_ 931 AvgFuelEconomy_Currenttrip 2500;
BA_ "GenSigTimeoutTime_HU_B" SG_ 931 AvgFuelEconomy_Currenttrip 2500;
BA_ "GenSigTimeoutTime_HU_A" SG_ 931 AvgFuelEconomy_Currenttrip 2500;
BA_ "GenSigTimeoutMsg_HU_Mid_X451" SG_ 931 AvgFuelEconomy_Currenttrip 2500;
BA_ "GenSigTimeoutMsg_HU_High_X451" SG_ 931 AvgFuelEconomy_Currenttrip 2500;
BA_ "GenSigTimeoutMsg_HU_B" SG_ 931 AvgFuelEconomy_Currenttrip 2500;
BA_ "GenSigTimeoutMsg_HU_A" SG_ 931 AvgFuelEconomy_Currenttrip 2500;
BA_ "GenSigSendType" SG_ 931 AvgFuelEconomy_Currenttrip 7;
BA_ "GenSigCycleTimeActive" SG_ 931 AvgFuelEconomy_Currenttrip 500;
BA_ "GenSigCycleTime" SG_ 931 AvgFuelEconomy_Currenttrip 500;
BA_ "GenSigTimeoutMsg_HU_High_X445" SG_ 931 AvgFuelEconomy_Currenttrip 2500;
BA_ "GenSigTimeoutMsg_HU_Mid_X445" SG_ 931 AvgFuelEconomy_Currenttrip 2500;
BA_ "GenSigTimeoutTime_HU_High_X445" SG_ 931 AvgFuelEconomy_Currenttrip 2500;
BA_ "GenSigTimeoutTime_HU_Mid_X445" SG_ 931 AvgFuelEconomy_Currenttrip 2500;
BA_ "GenSigTimeoutMsg_IVI" SG_ 931 AvgFuelEconomy_Currenttrip 2500;
BA_ "GenSigTimeoutTime_IVI" SG_ 931 AvgFuelEconomy_Currenttrip 2500;
BA_ "GenSigTimeoutTime_HU_Mid_X451" SG_ 931 AvgSpeed_CurrentTrip 2500;
BA_ "GenSigTimeoutTime_HU_High_X451" SG_ 931 AvgSpeed_CurrentTrip 2500;
BA_ "GenSigTimeoutTime_HU_B" SG_ 931 AvgSpeed_CurrentTrip 2500;
BA_ "GenSigTimeoutTime_HU_A" SG_ 931 AvgSpeed_CurrentTrip 2500;
BA_ "GenSigTimeoutMsg_HU_Mid_X451" SG_ 931 AvgSpeed_CurrentTrip 2500;
BA_ "GenSigTimeoutMsg_HU_High_X451" SG_ 931 AvgSpeed_CurrentTrip 2500;
BA_ "GenSigTimeoutMsg_HU_B" SG_ 931 AvgSpeed_CurrentTrip 2500;
BA_ "GenSigTimeoutMsg_HU_A" SG_ 931 AvgSpeed_CurrentTrip 2500;
BA_ "GenSigSendType" SG_ 931 AvgSpeed_CurrentTrip 7;
BA_ "GenSigCycleTimeActive" SG_ 931 AvgSpeed_CurrentTrip 500;
BA_ "GenSigCycleTime" SG_ 931 AvgSpeed_CurrentTrip 500;
BA_ "GenSigTimeoutMsg_HU_High_X445" SG_ 931 AvgSpeed_CurrentTrip 2500;
BA_ "GenSigTimeoutMsg_HU_Mid_X445" SG_ 931 AvgSpeed_CurrentTrip 2500;
BA_ "GenSigTimeoutTime_HU_High_X445" SG_ 931 AvgSpeed_CurrentTrip 2500;
BA_ "GenSigTimeoutTime_HU_Mid_X445" SG_ 931 AvgSpeed_CurrentTrip 2500;
BA_ "GenSigTimeoutMsg_IVI" SG_ 931 AvgSpeed_CurrentTrip 2500;
BA_ "GenSigTimeoutTime_IVI" SG_ 931 AvgSpeed_CurrentTrip 2500;
BA_ "GenSigTimeoutTime_HU_Mid_X451" SG_ 931 TripDistance_CurrentTrip 2500;
BA_ "GenSigTimeoutTime_HU_High_X451" SG_ 931 TripDistance_CurrentTrip 2500;
BA_ "GenSigTimeoutTime_HU_B" SG_ 931 TripDistance_CurrentTrip 2500;
BA_ "GenSigTimeoutTime_HU_A" SG_ 931 TripDistance_CurrentTrip 2500;
BA_ "GenSigTimeoutMsg_HU_Mid_X451" SG_ 931 TripDistance_CurrentTrip 2500;
BA_ "GenSigTimeoutMsg_HU_High_X451" SG_ 931 TripDistance_CurrentTrip 2500;
BA_ "GenSigTimeoutMsg_HU_B" SG_ 931 TripDistance_CurrentTrip 2500;
BA_ "GenSigTimeoutMsg_HU_A" SG_ 931 TripDistance_CurrentTrip 2500;
BA_ "GenSigSendType" SG_ 931 TripDistance_CurrentTrip 7;
BA_ "GenSigCycleTimeActive" SG_ 931 TripDistance_CurrentTrip 500;
BA_ "GenSigCycleTime" SG_ 931 TripDistance_CurrentTrip 500;
BA_ "GenSigTimeoutMsg_HU_High_X445" SG_ 931 TripDistance_CurrentTrip 2500;
BA_ "GenSigTimeoutMsg_HU_Mid_X445" SG_ 931 TripDistance_CurrentTrip 2500;
BA_ "GenSigTimeoutTime_HU_High_X445" SG_ 931 TripDistance_CurrentTrip 2500;
BA_ "GenSigTimeoutTime_HU_Mid_X445" SG_ 931 TripDistance_CurrentTrip 2500;
BA_ "GenSigTimeoutMsg_IVI" SG_ 931 TripDistance_CurrentTrip 2500;
BA_ "GenSigTimeoutTime_IVI" SG_ 931 TripDistance_CurrentTrip 2500;
BA_ "GenSigSendType" SG_ 932 HuIcDriveproOverAllScore_Inst 7;
BA_ "GenSigCycleTimeActive" SG_ 932 HuIcDriveproOverAllScore_Inst 500;
BA_ "GenSigCycleTime" SG_ 932 HuIcDriveproOverAllScore_Inst 500;
BA_ "GenSigSendType" SG_ 932 HuIcDriveproFEscore_Inst 7;
BA_ "GenSigCycleTimeActive" SG_ 932 HuIcDriveproFEscore_Inst 500;
BA_ "GenSigCycleTime" SG_ 932 HuIcDriveproFEscore_Inst 500;
BA_ "GenSigSendType" SG_ 932 HuIcDriveproSafetyScore_Inst 7;
BA_ "GenSigCycleTimeActive" SG_ 932 HuIcDriveproSafetyScore_Inst 500;
BA_ "GenSigCycleTime" SG_ 932 HuIcDriveproSafetyScore_Inst 500;
BA_ "GenSigSendType" SG_ 932 HuIcDriveproDrivingScore_Inst 7;
BA_ "GenSigCycleTimeActive" SG_ 932 HuIcDriveproDrivingScore_Inst 500;
BA_ "GenSigCycleTime" SG_ 932 HuIcDriveproDrivingScore_Inst 500;
BA_ "GenSigTimeoutTime_HU_Mid_X451" SG_ 938 VehSlowDownWarning 0;
BA_ "GenSigTimeoutTime_HU_High_X451" SG_ 938 VehSlowDownWarning 0;
BA_ "GenSigTimeoutTime_HU_B" SG_ 938 VehSlowDownWarning 0;
BA_ "GenSigTimeoutTime_HU_A" SG_ 938 VehSlowDownWarning 0;
BA_ "GenSigTimeoutMsg_HU_Mid_X451" SG_ 938 VehSlowDownWarning 0;
BA_ "GenSigTimeoutMsg_HU_High_X451" SG_ 938 VehSlowDownWarning 0;
BA_ "GenSigTimeoutMsg_HU_B" SG_ 938 VehSlowDownWarning 0;
BA_ "GenSigTimeoutMsg_HU_A" SG_ 938 VehSlowDownWarning 0;
BA_ "GenSigSendType" SG_ 938 VehSlowDownWarning 7;
BA_ "GenSigCycleTimeActive" SG_ 938 VehSlowDownWarning 500;
BA_ "GenSigCycleTime" SG_ 938 VehSlowDownWarning 500;
BA_ "GenSigTimeoutMsg_HU_High_X445" SG_ 938 VehSlowDownWarning 0;
BA_ "GenSigTimeoutMsg_HU_Mid_X445" SG_ 938 VehSlowDownWarning 0;
BA_ "GenSigTimeoutTime_HU_High_X445" SG_ 938 VehSlowDownWarning 0;
BA_ "GenSigTimeoutTime_HU_Mid_X445" SG_ 938 VehSlowDownWarning 0;
BA_ "GenSigTimeoutTime_HU_Mid_X451" SG_ 938 NoKeyDetectedTelltaleMsg 2500;
BA_ "GenSigTimeoutTime_HU_High_X451" SG_ 938 NoKeyDetectedTelltaleMsg 2500;
BA_ "GenSigTimeoutTime_HU_B" SG_ 938 NoKeyDetectedTelltaleMsg 2500;
BA_ "GenSigTimeoutTime_HU_A" SG_ 938 NoKeyDetectedTelltaleMsg 2500;
BA_ "GenSigTimeoutMsg_HU_Mid_X451" SG_ 938 NoKeyDetectedTelltaleMsg 2500;
BA_ "GenSigTimeoutMsg_HU_High_X451" SG_ 938 NoKeyDetectedTelltaleMsg 2500;
BA_ "GenSigTimeoutMsg_HU_B" SG_ 938 NoKeyDetectedTelltaleMsg 2500;
BA_ "GenSigTimeoutMsg_HU_A" SG_ 938 NoKeyDetectedTelltaleMsg 2500;
BA_ "GenSigSendType" SG_ 938 NoKeyDetectedTelltaleMsg 7;
BA_ "GenSigCycleTimeActive" SG_ 938 NoKeyDetectedTelltaleMsg 500;
BA_ "GenSigCycleTime" SG_ 938 NoKeyDetectedTelltaleMsg 500;
BA_ "GenSigTimeoutMsg_HU_High_X445" SG_ 938 NoKeyDetectedTelltaleMsg 2500;
BA_ "GenSigTimeoutMsg_HU_Mid_X445" SG_ 938 NoKeyDetectedTelltaleMsg 2500;
BA_ "GenSigTimeoutTime_HU_High_X445" SG_ 938 NoKeyDetectedTelltaleMsg 2500;
BA_ "GenSigTimeoutTime_HU_Mid_X445" SG_ 938 NoKeyDetectedTelltaleMsg 2500;
BA_ "GenSigTimeoutMsg_IVI" SG_ 938 NoKeyDetectedTelltaleMsg 2500;
BA_ "GenSigTimeoutTime_IVI" SG_ 938 NoKeyDetectedTelltaleMsg 2500;
BA_ "GenSigTimeoutTime_HU_Mid_X451" SG_ 938 LowBatUIdMsg 2500;
BA_ "GenSigTimeoutTime_HU_High_X451" SG_ 938 LowBatUIdMsg 2500;
BA_ "GenSigTimeoutTime_HU_B" SG_ 938 LowBatUIdMsg 2500;
BA_ "GenSigTimeoutTime_HU_A" SG_ 938 LowBatUIdMsg 2500;
BA_ "GenSigTimeoutMsg_HU_Mid_X451" SG_ 938 LowBatUIdMsg 2500;
BA_ "GenSigTimeoutMsg_HU_High_X451" SG_ 938 LowBatUIdMsg 2500;
BA_ "GenSigTimeoutMsg_HU_B" SG_ 938 LowBatUIdMsg 2500;
BA_ "GenSigTimeoutMsg_HU_A" SG_ 938 LowBatUIdMsg 2500;
BA_ "GenSigSendType" SG_ 938 LowBatUIdMsg 7;
BA_ "GenSigCycleTimeActive" SG_ 938 LowBatUIdMsg 500;
BA_ "GenSigCycleTime" SG_ 938 LowBatUIdMsg 500;
BA_ "GenSigTimeoutMsg_HU_High_X445" SG_ 938 LowBatUIdMsg 2500;
BA_ "GenSigTimeoutMsg_HU_Mid_X445" SG_ 938 LowBatUIdMsg 2500;
BA_ "GenSigTimeoutTime_HU_High_X445" SG_ 938 LowBatUIdMsg 2500;
BA_ "GenSigTimeoutTime_HU_Mid_X445" SG_ 938 LowBatUIdMsg 2500;
BA_ "GenSigTimeoutMsg_IVI" SG_ 938 LowBatUIdMsg 2500;
BA_ "GenSigTimeoutTime_IVI" SG_ 938 LowBatUIdMsg 2500;
BA_ "GenSigTimeoutTime_HU_Mid_X451" SG_ 938 PressClutchTelltaleMsgStatus 2500;
BA_ "GenSigTimeoutTime_HU_High_X451" SG_ 938 PressClutchTelltaleMsgStatus 2500;
BA_ "GenSigTimeoutTime_HU_B" SG_ 938 PressClutchTelltaleMsgStatus 2500;
BA_ "GenSigTimeoutTime_HU_A" SG_ 938 PressClutchTelltaleMsgStatus 2500;
BA_ "GenSigTimeoutMsg_HU_Mid_X451" SG_ 938 PressClutchTelltaleMsgStatus 2500;
BA_ "GenSigTimeoutMsg_HU_High_X451" SG_ 938 PressClutchTelltaleMsgStatus 2500;
BA_ "GenSigTimeoutMsg_HU_B" SG_ 938 PressClutchTelltaleMsgStatus 2500;
BA_ "GenSigTimeoutMsg_HU_A" SG_ 938 PressClutchTelltaleMsgStatus 2500;
BA_ "GenSigSendType" SG_ 938 PressClutchTelltaleMsgStatus 7;
BA_ "GenSigCycleTimeActive" SG_ 938 PressClutchTelltaleMsgStatus 500;
BA_ "GenSigCycleTime" SG_ 938 PressClutchTelltaleMsgStatus 500;
BA_ "GenSigTimeoutMsg_HU_High_X445" SG_ 938 PressClutchTelltaleMsgStatus 2500;
BA_ "GenSigTimeoutMsg_HU_Mid_X445" SG_ 938 PressClutchTelltaleMsgStatus 2500;
BA_ "GenSigTimeoutTime_HU_High_X445" SG_ 938 PressClutchTelltaleMsgStatus 2500;
BA_ "GenSigTimeoutTime_HU_Mid_X445" SG_ 938 PressClutchTelltaleMsgStatus 2500;
BA_ "GenSigTimeoutMsg_IVI" SG_ 938 PressClutchTelltaleMsgStatus 2500;
BA_ "GenSigTimeoutTime_IVI" SG_ 938 PressClutchTelltaleMsgStatus 2500;
BA_ "GenSigTimeoutTime_HU_Mid_X451" SG_ 938 PEPSAudioWarning 2500;
BA_ "GenSigTimeoutTime_HU_High_X451" SG_ 938 PEPSAudioWarning 2500;
BA_ "GenSigTimeoutTime_HU_B" SG_ 938 PEPSAudioWarning 2500;
BA_ "GenSigTimeoutTime_HU_A" SG_ 938 PEPSAudioWarning 2500;
BA_ "GenSigTimeoutMsg_HU_Mid_X451" SG_ 938 PEPSAudioWarning 2500;
BA_ "GenSigTimeoutMsg_HU_High_X451" SG_ 938 PEPSAudioWarning 2500;
BA_ "GenSigTimeoutMsg_HU_B" SG_ 938 PEPSAudioWarning 2500;
BA_ "GenSigTimeoutMsg_HU_A" SG_ 938 PEPSAudioWarning 2500;
BA_ "GenSigSendType" SG_ 938 PEPSAudioWarning 7;
BA_ "GenSigCycleTimeActive" SG_ 938 PEPSAudioWarning 500;
BA_ "GenSigCycleTime" SG_ 938 PEPSAudioWarning 500;
BA_ "GenSigTimeoutMsg_HU_High_X445" SG_ 938 PEPSAudioWarning 2500;
BA_ "GenSigTimeoutMsg_HU_Mid_X445" SG_ 938 PEPSAudioWarning 2500;
BA_ "GenSigTimeoutTime_HU_High_X445" SG_ 938 PEPSAudioWarning 2500;
BA_ "GenSigTimeoutTime_HU_Mid_X445" SG_ 938 PEPSAudioWarning 2500;
BA_ "GenSigTimeoutMsg_IVI" SG_ 938 PEPSAudioWarning 2500;
BA_ "GenSigTimeoutTime_IVI" SG_ 938 PEPSAudioWarning 2500;
BA_ "GenSigTimeoutTime_HU_Mid_X451" SG_ 938 PressBrakeTelltaleMsg 2500;
BA_ "GenSigTimeoutTime_HU_High_X451" SG_ 938 PressBrakeTelltaleMsg 2500;
BA_ "GenSigTimeoutTime_HU_B" SG_ 938 PressBrakeTelltaleMsg 2500;
BA_ "GenSigTimeoutTime_HU_A" SG_ 938 PressBrakeTelltaleMsg 2500;
BA_ "GenSigTimeoutMsg_HU_Mid_X451" SG_ 938 PressBrakeTelltaleMsg 2500;
BA_ "GenSigTimeoutMsg_HU_High_X451" SG_ 938 PressBrakeTelltaleMsg 2500;
BA_ "GenSigTimeoutMsg_HU_B" SG_ 938 PressBrakeTelltaleMsg 2500;
BA_ "GenSigTimeoutMsg_HU_A" SG_ 938 PressBrakeTelltaleMsg 2500;
BA_ "GenSigSendType" SG_ 938 PressBrakeTelltaleMsg 7;
BA_ "GenSigCycleTimeActive" SG_ 938 PressBrakeTelltaleMsg 500;
BA_ "GenSigCycleTime" SG_ 938 PressBrakeTelltaleMsg 500;
BA_ "GenSigTimeoutMsg_HU_High_X445" SG_ 938 PressBrakeTelltaleMsg 2500;
BA_ "GenSigTimeoutMsg_HU_Mid_X445" SG_ 938 PressBrakeTelltaleMsg 2500;
BA_ "GenSigTimeoutTime_HU_High_X445" SG_ 938 PressBrakeTelltaleMsg 2500;
BA_ "GenSigTimeoutTime_HU_Mid_X445" SG_ 938 PressBrakeTelltaleMsg 2500;
BA_ "GenSigTimeoutMsg_IVI" SG_ 938 PressBrakeTelltaleMsg 2500;
BA_ "GenSigTimeoutTime_IVI" SG_ 938 PressBrakeTelltaleMsg 2500;
BA_ "GenSigTimeoutTime_HU_Mid_X451" SG_ 938 PressClutchTelltaleMsg 2500;
BA_ "GenSigTimeoutTime_HU_High_X451" SG_ 938 PressClutchTelltaleMsg 2500;
BA_ "GenSigTimeoutTime_HU_B" SG_ 938 PressClutchTelltaleMsg 2500;
BA_ "GenSigTimeoutTime_HU_A" SG_ 938 PressClutchTelltaleMsg 2500;
BA_ "GenSigTimeoutMsg_HU_Mid_X451" SG_ 938 PressClutchTelltaleMsg 2500;
BA_ "GenSigTimeoutMsg_HU_High_X451" SG_ 938 PressClutchTelltaleMsg 2500;
BA_ "GenSigTimeoutMsg_HU_B" SG_ 938 PressClutchTelltaleMsg 2500;
BA_ "GenSigTimeoutMsg_HU_A" SG_ 938 PressClutchTelltaleMsg 2500;
BA_ "GenSigSendType" SG_ 938 PressClutchTelltaleMsg 7;
BA_ "GenSigCycleTimeActive" SG_ 938 PressClutchTelltaleMsg 500;
BA_ "GenSigCycleTime" SG_ 938 PressClutchTelltaleMsg 500;
BA_ "GenSigTimeoutMsg_HU_High_X445" SG_ 938 PressClutchTelltaleMsg 2500;
BA_ "GenSigTimeoutMsg_HU_Mid_X445" SG_ 938 PressClutchTelltaleMsg 2500;
BA_ "GenSigTimeoutTime_HU_High_X445" SG_ 938 PressClutchTelltaleMsg 2500;
BA_ "GenSigTimeoutTime_HU_Mid_X445" SG_ 938 PressClutchTelltaleMsg 2500;
BA_ "GenSigTimeoutMsg_IVI" SG_ 938 PressClutchTelltaleMsg 2500;
BA_ "GenSigTimeoutTime_IVI" SG_ 938 PressClutchTelltaleMsg 2500;
BA_ "GenSigTimeoutTime_HU_Mid_X451" SG_ 938 PressBrakeTelltaleMsgStatus 2500;
BA_ "GenSigTimeoutTime_HU_High_X451" SG_ 938 PressBrakeTelltaleMsgStatus 2500;
BA_ "GenSigTimeoutTime_HU_B" SG_ 938 PressBrakeTelltaleMsgStatus 2500;
BA_ "GenSigTimeoutTime_HU_A" SG_ 938 PressBrakeTelltaleMsgStatus 2500;
BA_ "GenSigTimeoutMsg_HU_Mid_X451" SG_ 938 PressBrakeTelltaleMsgStatus 2500;
BA_ "GenSigTimeoutMsg_HU_High_X451" SG_ 938 PressBrakeTelltaleMsgStatus 2500;
BA_ "GenSigTimeoutMsg_HU_B" SG_ 938 PressBrakeTelltaleMsgStatus 2500;
BA_ "GenSigTimeoutMsg_HU_A" SG_ 938 PressBrakeTelltaleMsgStatus 2500;
BA_ "GenSigSendType" SG_ 938 PressBrakeTelltaleMsgStatus 7;
BA_ "GenSigCycleTimeActive" SG_ 938 PressBrakeTelltaleMsgStatus 500;
BA_ "GenSigCycleTime" SG_ 938 PressBrakeTelltaleMsgStatus 500;
BA_ "GenSigTimeoutMsg_HU_High_X445" SG_ 938 PressBrakeTelltaleMsgStatus 2500;
BA_ "GenSigTimeoutMsg_HU_Mid_X445" SG_ 938 PressBrakeTelltaleMsgStatus 2500;
BA_ "GenSigTimeoutTime_HU_High_X445" SG_ 938 PressBrakeTelltaleMsgStatus 2500;
BA_ "GenSigTimeoutTime_HU_Mid_X445" SG_ 938 PressBrakeTelltaleMsgStatus 2500;
BA_ "GenSigTimeoutMsg_IVI" SG_ 938 PressBrakeTelltaleMsgStatus 2500;
BA_ "GenSigTimeoutTime_IVI" SG_ 938 PressBrakeTelltaleMsgStatus 2500;
BA_ "GenSigTimeoutTime_HU_Mid_X451" SG_ 946 DoorStateRearLHStatus 2500;
BA_ "GenSigTimeoutTime_HU_High_X451" SG_ 946 DoorStateRearLHStatus 2500;
BA_ "GenSigTimeoutTime_HU_B" SG_ 946 DoorStateRearLHStatus 2500;
BA_ "GenSigTimeoutTime_HU_A" SG_ 946 DoorStateRearLHStatus 2500;
BA_ "GenSigTimeoutMsg_HU_Mid_X451" SG_ 946 DoorStateRearLHStatus 2500;
BA_ "GenSigTimeoutMsg_HU_High_X451" SG_ 946 DoorStateRearLHStatus 2500;
BA_ "GenSigTimeoutMsg_HU_B" SG_ 946 DoorStateRearLHStatus 2500;
BA_ "GenSigTimeoutMsg_HU_A" SG_ 946 DoorStateRearLHStatus 2500;
BA_ "GenSigSendType" SG_ 946 DoorStateRearLHStatus 7;
BA_ "GenSigCycleTimeActive" SG_ 946 DoorStateRearLHStatus 500;
BA_ "GenSigCycleTime" SG_ 946 DoorStateRearLHStatus 500;
BA_ "GenSigTimeoutMsg_HU_High_X445" SG_ 946 DoorStateRearLHStatus 2500;
BA_ "GenSigTimeoutMsg_HU_Mid_X445" SG_ 946 DoorStateRearLHStatus 2500;
BA_ "GenSigTimeoutTime_HU_High_X445" SG_ 946 DoorStateRearLHStatus 2500;
BA_ "GenSigTimeoutTime_HU_Mid_X445" SG_ 946 DoorStateRearLHStatus 2500;
BA_ "GenSigTimeoutMsg_IVI" SG_ 946 DoorStateRearLHStatus 2500;
BA_ "GenSigTimeoutTime_IVI" SG_ 946 DoorStateRearLHStatus 2500;
BA_ "GenSigTimeoutTime_HU_Mid_X451" SG_ 946 DoorStatePassStatus 2500;
BA_ "GenSigTimeoutTime_HU_High_X451" SG_ 946 DoorStatePassStatus 2500;
BA_ "GenSigTimeoutTime_HU_B" SG_ 946 DoorStatePassStatus 2500;
BA_ "GenSigTimeoutTime_HU_A" SG_ 946 DoorStatePassStatus 2500;
BA_ "GenSigTimeoutMsg_HU_Mid_X451" SG_ 946 DoorStatePassStatus 2500;
BA_ "GenSigTimeoutMsg_HU_High_X451" SG_ 946 DoorStatePassStatus 2500;
BA_ "GenSigTimeoutMsg_HU_B" SG_ 946 DoorStatePassStatus 2500;
BA_ "GenSigTimeoutMsg_HU_A" SG_ 946 DoorStatePassStatus 2500;
BA_ "GenSigSendType" SG_ 946 DoorStatePassStatus 7;
BA_ "GenSigCycleTimeActive" SG_ 946 DoorStatePassStatus 500;
BA_ "GenSigCycleTime" SG_ 946 DoorStatePassStatus 500;
BA_ "GenSigTimeoutMsg_HU_High_X445" SG_ 946 DoorStatePassStatus 2500;
BA_ "GenSigTimeoutMsg_HU_Mid_X445" SG_ 946 DoorStatePassStatus 2500;
BA_ "GenSigTimeoutTime_HU_High_X445" SG_ 946 DoorStatePassStatus 2500;
BA_ "GenSigTimeoutTime_HU_Mid_X445" SG_ 946 DoorStatePassStatus 2500;
BA_ "GenSigTimeoutMsg_IVI" SG_ 946 DoorStatePassStatus 2500;
BA_ "GenSigTimeoutTime_IVI" SG_ 946 DoorStatePassStatus 2500;
BA_ "GenSigTimeoutTime_HU_Mid_X451" SG_ 946 DoorStatePass 2500;
BA_ "GenSigTimeoutTime_HU_High_X451" SG_ 946 DoorStatePass 2500;
BA_ "GenSigTimeoutTime_HU_B" SG_ 946 DoorStatePass 2500;
BA_ "GenSigTimeoutTime_HU_A" SG_ 946 DoorStatePass 2500;
BA_ "GenSigTimeoutMsg_HU_Mid_X451" SG_ 946 DoorStatePass 2500;
BA_ "GenSigTimeoutMsg_HU_High_X451" SG_ 946 DoorStatePass 2500;
BA_ "GenSigTimeoutMsg_HU_B" SG_ 946 DoorStatePass 2500;
BA_ "GenSigTimeoutMsg_HU_A" SG_ 946 DoorStatePass 2500;
BA_ "GenSigSendType" SG_ 946 DoorStatePass 7;
BA_ "GenSigCycleTimeActive" SG_ 946 DoorStatePass 500;
BA_ "GenSigCycleTime" SG_ 946 DoorStatePass 500;
BA_ "GenSigTimeoutMsg_HU_High_X445" SG_ 946 DoorStatePass 2500;
BA_ "GenSigTimeoutMsg_HU_Mid_X445" SG_ 946 DoorStatePass 2500;
BA_ "GenSigTimeoutTime_HU_High_X445" SG_ 946 DoorStatePass 2500;
BA_ "GenSigTimeoutTime_HU_Mid_X445" SG_ 946 DoorStatePass 2500;
BA_ "GenSigTimeoutMsg_IVI" SG_ 946 DoorStatePass 2500;
BA_ "GenSigTimeoutTime_IVI" SG_ 946 DoorStatePass 2500;
BA_ "GenSigTimeoutTime_HU_Mid_X451" SG_ 946 DoorStateDrvrStatus 2500;
BA_ "GenSigTimeoutTime_HU_High_X451" SG_ 946 DoorStateDrvrStatus 2500;
BA_ "GenSigTimeoutTime_HU_B" SG_ 946 DoorStateDrvrStatus 2500;
BA_ "GenSigTimeoutTime_HU_A" SG_ 946 DoorStateDrvrStatus 2500;
BA_ "GenSigTimeoutMsg_HU_Mid_X451" SG_ 946 DoorStateDrvrStatus 2500;
BA_ "GenSigTimeoutMsg_HU_High_X451" SG_ 946 DoorStateDrvrStatus 2500;
BA_ "GenSigTimeoutMsg_HU_B" SG_ 946 DoorStateDrvrStatus 2500;
BA_ "GenSigTimeoutMsg_HU_A" SG_ 946 DoorStateDrvrStatus 2500;
BA_ "GenSigSendType" SG_ 946 DoorStateDrvrStatus 7;
BA_ "GenSigCycleTimeActive" SG_ 946 DoorStateDrvrStatus 500;
BA_ "GenSigCycleTime" SG_ 946 DoorStateDrvrStatus 500;
BA_ "GenSigTimeoutMsg_HU_High_X445" SG_ 946 DoorStateDrvrStatus 2500;
BA_ "GenSigTimeoutMsg_HU_Mid_X445" SG_ 946 DoorStateDrvrStatus 2500;
BA_ "GenSigTimeoutTime_HU_High_X445" SG_ 946 DoorStateDrvrStatus 2500;
BA_ "GenSigTimeoutTime_HU_Mid_X445" SG_ 946 DoorStateDrvrStatus 2500;
BA_ "GenSigTimeoutMsg_IVI" SG_ 946 DoorStateDrvrStatus 2500;
BA_ "GenSigTimeoutTime_IVI" SG_ 946 DoorStateDrvrStatus 2500;
BA_ "GenSigTimeoutTime_HU_Mid_X451" SG_ 946 DoorStateDrvr 2500;
BA_ "GenSigTimeoutTime_HU_High_X451" SG_ 946 DoorStateDrvr 2500;
BA_ "GenSigTimeoutTime_HU_B" SG_ 946 DoorStateDrvr 2500;
BA_ "GenSigTimeoutTime_HU_A" SG_ 946 DoorStateDrvr 2500;
BA_ "GenSigTimeoutMsg_HU_Mid_X451" SG_ 946 DoorStateDrvr 2500;
BA_ "GenSigTimeoutMsg_HU_High_X451" SG_ 946 DoorStateDrvr 2500;
BA_ "GenSigTimeoutMsg_HU_B" SG_ 946 DoorStateDrvr 2500;
BA_ "GenSigTimeoutMsg_HU_A" SG_ 946 DoorStateDrvr 2500;
BA_ "GenSigSendType" SG_ 946 DoorStateDrvr 7;
BA_ "GenSigCycleTimeActive" SG_ 946 DoorStateDrvr 500;
BA_ "GenSigCycleTime" SG_ 946 DoorStateDrvr 500;
BA_ "GenSigTimeoutMsg_HU_High_X445" SG_ 946 DoorStateDrvr 2500;
BA_ "GenSigTimeoutMsg_HU_Mid_X445" SG_ 946 DoorStateDrvr 2500;
BA_ "GenSigTimeoutTime_HU_High_X445" SG_ 946 DoorStateDrvr 2500;
BA_ "GenSigTimeoutTime_HU_Mid_X445" SG_ 946 DoorStateDrvr 2500;
BA_ "GenSigTimeoutMsg_IVI" SG_ 946 DoorStateDrvr 2500;
BA_ "GenSigTimeoutTime_IVI" SG_ 946 DoorStateDrvr 2500;
BA_ "GenSigTimeoutTime_HU_Mid_X451" SG_ 946 DoorStateRearRH 2500;
BA_ "GenSigTimeoutTime_HU_High_X451" SG_ 946 DoorStateRearRH 2500;
BA_ "GenSigTimeoutTime_HU_B" SG_ 946 DoorStateRearRH 2500;
BA_ "GenSigTimeoutTime_HU_A" SG_ 946 DoorStateRearRH 2500;
BA_ "GenSigTimeoutMsg_HU_Mid_X451" SG_ 946 DoorStateRearRH 2500;
BA_ "GenSigTimeoutMsg_HU_High_X451" SG_ 946 DoorStateRearRH 2500;
BA_ "GenSigTimeoutMsg_HU_B" SG_ 946 DoorStateRearRH 2500;
BA_ "GenSigTimeoutMsg_HU_A" SG_ 946 DoorStateRearRH 2500;
BA_ "GenSigSendType" SG_ 946 DoorStateRearRH 7;
BA_ "GenSigCycleTimeActive" SG_ 946 DoorStateRearRH 500;
BA_ "GenSigCycleTime" SG_ 946 DoorStateRearRH 500;
BA_ "GenSigTimeoutMsg_HU_High_X445" SG_ 946 DoorStateRearRH 2500;
BA_ "GenSigTimeoutMsg_HU_Mid_X445" SG_ 946 DoorStateRearRH 2500;
BA_ "GenSigTimeoutTime_HU_High_X445" SG_ 946 DoorStateRearRH 2500;
BA_ "GenSigTimeoutTime_HU_Mid_X445" SG_ 946 DoorStateRearRH 2500;
BA_ "GenSigTimeoutMsg_IVI" SG_ 946 DoorStateRearRH 2500;
BA_ "GenSigTimeoutTime_IVI" SG_ 946 DoorStateRearRH 2500;
BA_ "GenSigTimeoutTime_HU_Mid_X451" SG_ 946 DoorStateRearRHStatus 2500;
BA_ "GenSigTimeoutTime_HU_High_X451" SG_ 946 DoorStateRearRHStatus 2500;
BA_ "GenSigTimeoutTime_HU_B" SG_ 946 DoorStateRearRHStatus 2500;
BA_ "GenSigTimeoutTime_HU_A" SG_ 946 DoorStateRearRHStatus 2500;
BA_ "GenSigTimeoutMsg_HU_Mid_X451" SG_ 946 DoorStateRearRHStatus 2500;
BA_ "GenSigTimeoutMsg_HU_High_X451" SG_ 946 DoorStateRearRHStatus 2500;
BA_ "GenSigTimeoutMsg_HU_B" SG_ 946 DoorStateRearRHStatus 2500;
BA_ "GenSigTimeoutMsg_HU_A" SG_ 946 DoorStateRearRHStatus 2500;
BA_ "GenSigSendType" SG_ 946 DoorStateRearRHStatus 7;
BA_ "GenSigCycleTimeActive" SG_ 946 DoorStateRearRHStatus 500;
BA_ "GenSigCycleTime" SG_ 946 DoorStateRearRHStatus 500;
BA_ "GenSigTimeoutMsg_HU_High_X445" SG_ 946 DoorStateRearRHStatus 2500;
BA_ "GenSigTimeoutMsg_HU_Mid_X445" SG_ 946 DoorStateRearRHStatus 2500;
BA_ "GenSigTimeoutTime_HU_High_X445" SG_ 946 DoorStateRearRHStatus 2500;
BA_ "GenSigTimeoutTime_HU_Mid_X445" SG_ 946 DoorStateRearRHStatus 2500;
BA_ "GenSigTimeoutMsg_IVI" SG_ 946 DoorStateRearRHStatus 2500;
BA_ "GenSigTimeoutTime_IVI" SG_ 946 DoorStateRearRHStatus 2500;
BA_ "GenSigTimeoutTime_HU_Mid_X451" SG_ 946 DoorStateRearLH 2500;
BA_ "GenSigTimeoutTime_HU_High_X451" SG_ 946 DoorStateRearLH 2500;
BA_ "GenSigTimeoutTime_HU_B" SG_ 946 DoorStateRearLH 2500;
BA_ "GenSigTimeoutTime_HU_A" SG_ 946 DoorStateRearLH 2500;
BA_ "GenSigTimeoutMsg_HU_Mid_X451" SG_ 946 DoorStateRearLH 2500;
BA_ "GenSigTimeoutMsg_HU_High_X451" SG_ 946 DoorStateRearLH 2500;
BA_ "GenSigTimeoutMsg_HU_B" SG_ 946 DoorStateRearLH 2500;
BA_ "GenSigTimeoutMsg_HU_A" SG_ 946 DoorStateRearLH 2500;
BA_ "GenSigSendType" SG_ 946 DoorStateRearLH 7;
BA_ "GenSigCycleTimeActive" SG_ 946 DoorStateRearLH 500;
BA_ "GenSigCycleTime" SG_ 946 DoorStateRearLH 500;
BA_ "GenSigTimeoutMsg_HU_High_X445" SG_ 946 DoorStateRearLH 2500;
BA_ "GenSigTimeoutMsg_HU_Mid_X445" SG_ 946 DoorStateRearLH 2500;
BA_ "GenSigTimeoutTime_HU_High_X445" SG_ 946 DoorStateRearLH 2500;
BA_ "GenSigTimeoutTime_HU_Mid_X445" SG_ 946 DoorStateRearLH 2500;
BA_ "GenSigTimeoutMsg_IVI" SG_ 946 DoorStateRearLH 2500;
BA_ "GenSigTimeoutTime_IVI" SG_ 946 DoorStateRearLH 2500;
BA_ "GenSigTimeoutTime_HU_B" SG_ 946 WiperState 0;
BA_ "GenSigTimeoutTime_HU_A" SG_ 946 WiperState 0;
BA_ "GenSigTimeoutMsg_HU_B" SG_ 946 WiperState 0;
BA_ "GenSigTimeoutMsg_HU_A" SG_ 946 WiperState 0;
BA_ "GenSigSendType" SG_ 946 WiperState 7;
BA_ "GenSigCycleTimeActive" SG_ 946 WiperState 500;
BA_ "GenSigCycleTime" SG_ 946 WiperState 500;
BA_ "GenSigTimeoutTime_HU_Mid_X451" SG_ 946 TailgateState 2500;
BA_ "GenSigTimeoutTime_HU_High_X451" SG_ 946 TailgateState 2500;
BA_ "GenSigTimeoutTime_HU_B" SG_ 946 TailgateState 2500;
BA_ "GenSigTimeoutTime_HU_A" SG_ 946 TailgateState 2500;
BA_ "GenSigTimeoutMsg_HU_Mid_X451" SG_ 946 TailgateState 2500;
BA_ "GenSigTimeoutMsg_HU_High_X451" SG_ 946 TailgateState 2500;
BA_ "GenSigTimeoutMsg_HU_B" SG_ 946 TailgateState 2500;
BA_ "GenSigTimeoutMsg_HU_A" SG_ 946 TailgateState 2500;
BA_ "GenSigSendType" SG_ 946 TailgateState 7;
BA_ "GenSigCycleTimeActive" SG_ 946 TailgateState 500;
BA_ "GenSigCycleTime" SG_ 946 TailgateState 500;
BA_ "GenSigTimeoutMsg_HU_High_X445" SG_ 946 TailgateState 2500;
BA_ "GenSigTimeoutMsg_HU_Mid_X445" SG_ 946 TailgateState 2500;
BA_ "GenSigTimeoutTime_HU_High_X445" SG_ 946 TailgateState 2500;
BA_ "GenSigTimeoutTime_HU_Mid_X445" SG_ 946 TailgateState 2500;
BA_ "GenSigTimeoutMsg_IVI" SG_ 946 TailgateState 2500;
BA_ "GenSigTimeoutTime_IVI" SG_ 946 TailgateState 2500;
BA_ "GenSigTimeoutTime_HU_B" SG_ 946 WiperStateStatus 0;
BA_ "GenSigTimeoutTime_HU_A" SG_ 946 WiperStateStatus 0;
BA_ "GenSigTimeoutMsg_HU_B" SG_ 946 WiperStateStatus 0;
BA_ "GenSigTimeoutMsg_HU_A" SG_ 946 WiperStateStatus 0;
BA_ "GenSigSendType" SG_ 946 WiperStateStatus 7;
BA_ "GenSigCycleTimeActive" SG_ 946 WiperStateStatus 500;
BA_ "GenSigCycleTime" SG_ 946 WiperStateStatus 500;
BA_ "GenSigTimeoutTime_HU_Mid_X451" SG_ 946 TailgateStateStatus 2500;
BA_ "GenSigTimeoutTime_HU_High_X451" SG_ 946 TailgateStateStatus 2500;
BA_ "GenSigTimeoutTime_HU_B" SG_ 946 TailgateStateStatus 2500;
BA_ "GenSigTimeoutTime_HU_A" SG_ 946 TailgateStateStatus 2500;
BA_ "GenSigTimeoutMsg_HU_Mid_X451" SG_ 946 TailgateStateStatus 2500;
BA_ "GenSigTimeoutMsg_HU_High_X451" SG_ 946 TailgateStateStatus 2500;
BA_ "GenSigTimeoutMsg_HU_B" SG_ 946 TailgateStateStatus 2500;
BA_ "GenSigTimeoutMsg_HU_A" SG_ 946 TailgateStateStatus 2500;
BA_ "GenSigSendType" SG_ 946 TailgateStateStatus 7;
BA_ "GenSigCycleTimeActive" SG_ 946 TailgateStateStatus 500;
BA_ "GenSigCycleTime" SG_ 946 TailgateStateStatus 500;
BA_ "GenSigTimeoutMsg_HU_High_X445" SG_ 946 TailgateStateStatus 2500;
BA_ "GenSigTimeoutMsg_HU_Mid_X445" SG_ 946 TailgateStateStatus 2500;
BA_ "GenSigTimeoutTime_HU_High_X445" SG_ 946 TailgateStateStatus 2500;
BA_ "GenSigTimeoutTime_HU_Mid_X445" SG_ 946 TailgateStateStatus 2500;
BA_ "GenSigTimeoutMsg_IVI" SG_ 946 TailgateStateStatus 2500;
BA_ "GenSigTimeoutTime_IVI" SG_ 946 TailgateStateStatus 2500;
BA_ "GenSigTimeoutTime_HU_Mid_X451" SG_ 946 PositionLmpMalFn 2500;
BA_ "GenSigTimeoutTime_HU_High_X451" SG_ 946 PositionLmpMalFn 2500;
BA_ "GenSigTimeoutTime_HU_B" SG_ 946 PositionLmpMalFn 2500;
BA_ "GenSigTimeoutTime_HU_A" SG_ 946 PositionLmpMalFn 2500;
BA_ "GenSigTimeoutMsg_HU_Mid_X451" SG_ 946 PositionLmpMalFn 2500;
BA_ "GenSigTimeoutMsg_HU_High_X451" SG_ 946 PositionLmpMalFn 2500;
BA_ "GenSigTimeoutMsg_HU_B" SG_ 946 PositionLmpMalFn 2500;
BA_ "GenSigTimeoutMsg_HU_A" SG_ 946 PositionLmpMalFn 2500;
BA_ "GenSigSendType" SG_ 946 PositionLmpMalFn 7;
BA_ "GenSigCycleTimeActive" SG_ 946 PositionLmpMalFn 500;
BA_ "GenSigCycleTime" SG_ 946 PositionLmpMalFn 500;
BA_ "GenSigTimeoutMsg_HU_High_X445" SG_ 946 PositionLmpMalFn 2500;
BA_ "GenSigTimeoutMsg_HU_Mid_X445" SG_ 946 PositionLmpMalFn 2500;
BA_ "GenSigTimeoutTime_HU_High_X445" SG_ 946 PositionLmpMalFn 2500;
BA_ "GenSigTimeoutTime_HU_Mid_X445" SG_ 946 PositionLmpMalFn 2500;
BA_ "GenSigTimeoutMsg_IVI" SG_ 946 PositionLmpMalFn 2500;
BA_ "GenSigTimeoutTime_IVI" SG_ 946 PositionLmpMalFn 2500;
BA_ "GenSigTimeoutTime_HU_B" SG_ 946 TrailerState 0;
BA_ "GenSigTimeoutTime_HU_A" SG_ 946 TrailerState 0;
BA_ "GenSigTimeoutMsg_HU_B" SG_ 946 TrailerState 0;
BA_ "GenSigTimeoutMsg_HU_A" SG_ 946 TrailerState 0;
BA_ "GenSigSendType" SG_ 946 TrailerState 7;
BA_ "GenSigCycleTimeActive" SG_ 946 TrailerState 500;
BA_ "GenSigCycleTime" SG_ 946 TrailerState 500;
BA_ "GenSigTimeoutTime_HU_Mid_X451" SG_ 946 PositionLmpMalFnStatus 2500;
BA_ "GenSigTimeoutTime_HU_High_X451" SG_ 946 PositionLmpMalFnStatus 2500;
BA_ "GenSigTimeoutTime_HU_B" SG_ 946 PositionLmpMalFnStatus 2500;
BA_ "GenSigTimeoutTime_HU_A" SG_ 946 PositionLmpMalFnStatus 2500;
BA_ "GenSigTimeoutMsg_HU_Mid_X451" SG_ 946 PositionLmpMalFnStatus 2500;
BA_ "GenSigTimeoutMsg_HU_High_X451" SG_ 946 PositionLmpMalFnStatus 2500;
BA_ "GenSigTimeoutMsg_HU_B" SG_ 946 PositionLmpMalFnStatus 2500;
BA_ "GenSigTimeoutMsg_HU_A" SG_ 946 PositionLmpMalFnStatus 2500;
BA_ "GenSigSendType" SG_ 946 PositionLmpMalFnStatus 7;
BA_ "GenSigCycleTimeActive" SG_ 946 PositionLmpMalFnStatus 500;
BA_ "GenSigCycleTime" SG_ 946 PositionLmpMalFnStatus 500;
BA_ "GenSigTimeoutMsg_HU_High_X445" SG_ 946 PositionLmpMalFnStatus 2500;
BA_ "GenSigTimeoutMsg_HU_Mid_X445" SG_ 946 PositionLmpMalFnStatus 2500;
BA_ "GenSigTimeoutTime_HU_High_X445" SG_ 946 PositionLmpMalFnStatus 2500;
BA_ "GenSigTimeoutTime_HU_Mid_X445" SG_ 946 PositionLmpMalFnStatus 2500;
BA_ "GenSigTimeoutMsg_IVI" SG_ 946 PositionLmpMalFnStatus 2500;
BA_ "GenSigTimeoutTime_IVI" SG_ 946 PositionLmpMalFnStatus 2500;
BA_ "GenSigTimeoutTime_HU_Mid_X451" SG_ 946 BrakeLmpMalFn 2500;
BA_ "GenSigTimeoutTime_HU_High_X451" SG_ 946 BrakeLmpMalFn 2500;
BA_ "GenSigTimeoutTime_HU_B" SG_ 946 BrakeLmpMalFn 2500;
BA_ "GenSigTimeoutTime_HU_A" SG_ 946 BrakeLmpMalFn 2500;
BA_ "GenSigTimeoutMsg_HU_Mid_X451" SG_ 946 BrakeLmpMalFn 2500;
BA_ "GenSigTimeoutMsg_HU_High_X451" SG_ 946 BrakeLmpMalFn 2500;
BA_ "GenSigTimeoutMsg_HU_B" SG_ 946 BrakeLmpMalFn 2500;
BA_ "GenSigTimeoutMsg_HU_A" SG_ 946 BrakeLmpMalFn 2500;
BA_ "GenSigSendType" SG_ 946 BrakeLmpMalFn 7;
BA_ "GenSigCycleTimeActive" SG_ 946 BrakeLmpMalFn 500;
BA_ "GenSigCycleTime" SG_ 946 BrakeLmpMalFn 500;
BA_ "GenSigTimeoutMsg_HU_High_X445" SG_ 946 BrakeLmpMalFn 2500;
BA_ "GenSigTimeoutMsg_HU_Mid_X445" SG_ 946 BrakeLmpMalFn 2500;
BA_ "GenSigTimeoutTime_HU_High_X445" SG_ 946 BrakeLmpMalFn 2500;
BA_ "GenSigTimeoutTime_HU_Mid_X445" SG_ 946 BrakeLmpMalFn 2500;
BA_ "GenSigTimeoutMsg_IVI" SG_ 946 BrakeLmpMalFn 2500;
BA_ "GenSigTimeoutTime_IVI" SG_ 946 BrakeLmpMalFn 2500;
BA_ "GenSigTimeoutTime_HU_Mid_X451" SG_ 946 BrakeLmpMalFnStatus 2500;
BA_ "GenSigTimeoutTime_HU_High_X451" SG_ 946 BrakeLmpMalFnStatus 2500;
BA_ "GenSigTimeoutTime_HU_B" SG_ 946 BrakeLmpMalFnStatus 2500;
BA_ "GenSigTimeoutTime_HU_A" SG_ 946 BrakeLmpMalFnStatus 2500;
BA_ "GenSigTimeoutMsg_HU_Mid_X451" SG_ 946 BrakeLmpMalFnStatus 2500;
BA_ "GenSigTimeoutMsg_HU_High_X451" SG_ 946 BrakeLmpMalFnStatus 2500;
BA_ "GenSigTimeoutMsg_HU_B" SG_ 946 BrakeLmpMalFnStatus 2500;
BA_ "GenSigTimeoutMsg_HU_A" SG_ 946 BrakeLmpMalFnStatus 2500;
BA_ "GenSigSendType" SG_ 946 BrakeLmpMalFnStatus 7;
BA_ "GenSigCycleTimeActive" SG_ 946 BrakeLmpMalFnStatus 500;
BA_ "GenSigCycleTime" SG_ 946 BrakeLmpMalFnStatus 500;
BA_ "GenSigTimeoutMsg_HU_High_X445" SG_ 946 BrakeLmpMalFnStatus 2500;
BA_ "GenSigTimeoutMsg_HU_Mid_X445" SG_ 946 BrakeLmpMalFnStatus 2500;
BA_ "GenSigTimeoutTime_HU_High_X445" SG_ 946 BrakeLmpMalFnStatus 2500;
BA_ "GenSigTimeoutTime_HU_Mid_X445" SG_ 946 BrakeLmpMalFnStatus 2500;
BA_ "GenSigTimeoutMsg_IVI" SG_ 946 BrakeLmpMalFnStatus 2500;
BA_ "GenSigTimeoutTime_IVI" SG_ 946 BrakeLmpMalFnStatus 2500;
BA_ "GenSigTimeoutTime_HU_Mid_X451" SG_ 946 RevLampMalFn 2500;
BA_ "GenSigTimeoutTime_HU_High_X451" SG_ 946 RevLampMalFn 2500;
BA_ "GenSigTimeoutTime_HU_B" SG_ 946 RevLampMalFn 2500;
BA_ "GenSigTimeoutTime_HU_A" SG_ 946 RevLampMalFn 2500;
BA_ "GenSigTimeoutMsg_HU_Mid_X451" SG_ 946 RevLampMalFn 2500;
BA_ "GenSigTimeoutMsg_HU_High_X451" SG_ 946 RevLampMalFn 2500;
BA_ "GenSigTimeoutMsg_HU_B" SG_ 946 RevLampMalFn 2500;
BA_ "GenSigTimeoutMsg_HU_A" SG_ 946 RevLampMalFn 2500;
BA_ "GenSigSendType" SG_ 946 RevLampMalFn 7;
BA_ "GenSigCycleTimeActive" SG_ 946 RevLampMalFn 500;
BA_ "GenSigCycleTime" SG_ 946 RevLampMalFn 500;
BA_ "GenSigTimeoutMsg_HU_High_X445" SG_ 946 RevLampMalFn 2500;
BA_ "GenSigTimeoutMsg_HU_Mid_X445" SG_ 946 RevLampMalFn 2500;
BA_ "GenSigTimeoutTime_HU_High_X445" SG_ 946 RevLampMalFn 2500;
BA_ "GenSigTimeoutTime_HU_Mid_X445" SG_ 946 RevLampMalFn 2500;
BA_ "GenSigTimeoutMsg_IVI" SG_ 946 RevLampMalFn 2500;
BA_ "GenSigTimeoutTime_IVI" SG_ 946 RevLampMalFn 2500;
BA_ "GenSigTimeoutTime_HU_Mid_X451" SG_ 946 RevLampMalFnStatus 2500;
BA_ "GenSigTimeoutTime_HU_High_X451" SG_ 946 RevLampMalFnStatus 2500;
BA_ "GenSigTimeoutTime_HU_B" SG_ 946 RevLampMalFnStatus 2500;
BA_ "GenSigTimeoutTime_HU_A" SG_ 946 RevLampMalFnStatus 2500;
BA_ "GenSigTimeoutMsg_HU_Mid_X451" SG_ 946 RevLampMalFnStatus 2500;
BA_ "GenSigTimeoutMsg_HU_High_X451" SG_ 946 RevLampMalFnStatus 2500;
BA_ "GenSigTimeoutMsg_HU_B" SG_ 946 RevLampMalFnStatus 2500;
BA_ "GenSigTimeoutMsg_HU_A" SG_ 946 RevLampMalFnStatus 2500;
BA_ "GenSigSendType" SG_ 946 RevLampMalFnStatus 7;
BA_ "GenSigCycleTimeActive" SG_ 946 RevLampMalFnStatus 500;
BA_ "GenSigCycleTime" SG_ 946 RevLampMalFnStatus 500;
BA_ "GenSigTimeoutMsg_HU_High_X445" SG_ 946 RevLampMalFnStatus 2500;
BA_ "GenSigTimeoutMsg_HU_Mid_X445" SG_ 946 RevLampMalFnStatus 2500;
BA_ "GenSigTimeoutTime_HU_High_X445" SG_ 946 RevLampMalFnStatus 2500;
BA_ "GenSigTimeoutTime_HU_Mid_X445" SG_ 946 RevLampMalFnStatus 2500;
BA_ "GenSigTimeoutMsg_IVI" SG_ 946 RevLampMalFnStatus 2500;
BA_ "GenSigTimeoutTime_IVI" SG_ 946 RevLampMalFnStatus 2500;
BA_ "GenSigTimeoutTime_HU_B" SG_ 946 TrailerStateStatus 0;
BA_ "GenSigTimeoutTime_HU_A" SG_ 946 TrailerStateStatus 0;
BA_ "GenSigTimeoutMsg_HU_B" SG_ 946 TrailerStateStatus 0;
BA_ "GenSigTimeoutMsg_HU_A" SG_ 946 TrailerStateStatus 0;
BA_ "GenSigSendType" SG_ 946 TrailerStateStatus 7;
BA_ "GenSigCycleTimeActive" SG_ 946 TrailerStateStatus 500;
BA_ "GenSigCycleTime" SG_ 946 TrailerStateStatus 500;
BA_ "GenSigTimeoutTime_HU_Mid_X451" SG_ 946 LowBeamMalFn 2500;
BA_ "GenSigTimeoutTime_HU_High_X451" SG_ 946 LowBeamMalFn 2500;
BA_ "GenSigTimeoutTime_HU_B" SG_ 946 LowBeamMalFn 2500;
BA_ "GenSigTimeoutTime_HU_A" SG_ 946 LowBeamMalFn 2500;
BA_ "GenSigTimeoutMsg_HU_Mid_X451" SG_ 946 LowBeamMalFn 2500;
BA_ "GenSigTimeoutMsg_HU_High_X451" SG_ 946 LowBeamMalFn 2500;
BA_ "GenSigTimeoutMsg_HU_B" SG_ 946 LowBeamMalFn 2500;
BA_ "GenSigTimeoutMsg_HU_A" SG_ 946 LowBeamMalFn 2500;
BA_ "GenSigSendType" SG_ 946 LowBeamMalFn 7;
BA_ "GenSigCycleTimeActive" SG_ 946 LowBeamMalFn 500;
BA_ "GenSigCycleTime" SG_ 946 LowBeamMalFn 500;
BA_ "GenSigTimeoutMsg_HU_High_X445" SG_ 946 LowBeamMalFn 2500;
BA_ "GenSigTimeoutMsg_HU_Mid_X445" SG_ 946 LowBeamMalFn 2500;
BA_ "GenSigTimeoutTime_HU_High_X445" SG_ 946 LowBeamMalFn 2500;
BA_ "GenSigTimeoutTime_HU_Mid_X445" SG_ 946 LowBeamMalFn 2500;
BA_ "GenSigTimeoutMsg_IVI" SG_ 946 LowBeamMalFn 2500;
BA_ "GenSigTimeoutTime_IVI" SG_ 946 LowBeamMalFn 2500;
BA_ "GenSigTimeoutTime_HU_Mid_X451" SG_ 946 HighBeamTelltale 2500;
BA_ "GenSigTimeoutTime_HU_High_X451" SG_ 946 HighBeamTelltale 2500;
BA_ "GenSigTimeoutTime_HU_B" SG_ 946 HighBeamTelltale 2500;
BA_ "GenSigTimeoutTime_HU_A" SG_ 946 HighBeamTelltale 2500;
BA_ "GenSigTimeoutMsg_HU_Mid_X451" SG_ 946 HighBeamTelltale 2500;
BA_ "GenSigTimeoutMsg_HU_High_X451" SG_ 946 HighBeamTelltale 2500;
BA_ "GenSigTimeoutMsg_HU_B" SG_ 946 HighBeamTelltale 2500;
BA_ "GenSigTimeoutMsg_HU_A" SG_ 946 HighBeamTelltale 2500;
BA_ "GenSigSendType" SG_ 946 HighBeamTelltale 7;
BA_ "GenSigCycleTimeActive" SG_ 946 HighBeamTelltale 500;
BA_ "GenSigCycleTime" SG_ 946 HighBeamTelltale 500;
BA_ "GenSigTimeoutMsg_HU_High_X445" SG_ 946 HighBeamTelltale 2500;
BA_ "GenSigTimeoutMsg_HU_Mid_X445" SG_ 946 HighBeamTelltale 2500;
BA_ "GenSigTimeoutTime_HU_High_X445" SG_ 946 HighBeamTelltale 2500;
BA_ "GenSigTimeoutTime_HU_Mid_X445" SG_ 946 HighBeamTelltale 2500;
BA_ "GenSigTimeoutMsg_IVI" SG_ 946 HighBeamTelltale 2500;
BA_ "GenSigTimeoutTime_IVI" SG_ 946 HighBeamTelltale 2500;
BA_ "GenSigTimeoutTime_HU_Mid_X451" SG_ 946 HighBeamTelltaleStatus 2500;
BA_ "GenSigTimeoutTime_HU_High_X451" SG_ 946 HighBeamTelltaleStatus 2500;
BA_ "GenSigTimeoutTime_HU_B" SG_ 946 HighBeamTelltaleStatus 2500;
BA_ "GenSigTimeoutTime_HU_A" SG_ 946 HighBeamTelltaleStatus 2500;
BA_ "GenSigTimeoutMsg_HU_Mid_X451" SG_ 946 HighBeamTelltaleStatus 2500;
BA_ "GenSigTimeoutMsg_HU_High_X451" SG_ 946 HighBeamTelltaleStatus 2500;
BA_ "GenSigTimeoutMsg_HU_B" SG_ 946 HighBeamTelltaleStatus 2500;
BA_ "GenSigTimeoutMsg_HU_A" SG_ 946 HighBeamTelltaleStatus 2500;
BA_ "GenSigSendType" SG_ 946 HighBeamTelltaleStatus 7;
BA_ "GenSigCycleTimeActive" SG_ 946 HighBeamTelltaleStatus 500;
BA_ "GenSigCycleTime" SG_ 946 HighBeamTelltaleStatus 500;
BA_ "GenSigTimeoutMsg_HU_High_X445" SG_ 946 HighBeamTelltaleStatus 2500;
BA_ "GenSigTimeoutMsg_HU_Mid_X445" SG_ 946 HighBeamTelltaleStatus 2500;
BA_ "GenSigTimeoutTime_HU_High_X445" SG_ 946 HighBeamTelltaleStatus 2500;
BA_ "GenSigTimeoutTime_HU_Mid_X445" SG_ 946 HighBeamTelltaleStatus 2500;
BA_ "GenSigTimeoutMsg_IVI" SG_ 946 HighBeamTelltaleStatus 2500;
BA_ "GenSigTimeoutTime_IVI" SG_ 946 HighBeamTelltaleStatus 2500;
BA_ "GenSigTimeoutTime_HU_Mid_X451" SG_ 946 DRLTelltale 2500;
BA_ "GenSigTimeoutTime_HU_High_X451" SG_ 946 DRLTelltale 2500;
BA_ "GenSigTimeoutTime_HU_B" SG_ 946 DRLTelltale 2500;
BA_ "GenSigTimeoutTime_HU_A" SG_ 946 DRLTelltale 2500;
BA_ "GenSigTimeoutMsg_HU_Mid_X451" SG_ 946 DRLTelltale 2500;
BA_ "GenSigTimeoutMsg_HU_High_X451" SG_ 946 DRLTelltale 2500;
BA_ "GenSigTimeoutMsg_HU_B" SG_ 946 DRLTelltale 2500;
BA_ "GenSigTimeoutMsg_HU_A" SG_ 946 DRLTelltale 2500;
BA_ "GenSigSendType" SG_ 946 DRLTelltale 7;
BA_ "GenSigCycleTimeActive" SG_ 946 DRLTelltale 500;
BA_ "GenSigCycleTime" SG_ 946 DRLTelltale 500;
BA_ "GenSigTimeoutMsg_HU_High_X445" SG_ 946 DRLTelltale 2500;
BA_ "GenSigTimeoutMsg_HU_Mid_X445" SG_ 946 DRLTelltale 2500;
BA_ "GenSigTimeoutTime_HU_High_X445" SG_ 946 DRLTelltale 2500;
BA_ "GenSigTimeoutTime_HU_Mid_X445" SG_ 946 DRLTelltale 2500;
BA_ "GenSigTimeoutMsg_IVI" SG_ 946 DRLTelltale 2500;
BA_ "GenSigTimeoutTime_IVI" SG_ 946 DRLTelltale 2500;
BA_ "GenSigTimeoutTime_HU_Mid_X451" SG_ 946 FrontFogTelltale 2500;
BA_ "GenSigTimeoutTime_HU_High_X451" SG_ 946 FrontFogTelltale 2500;
BA_ "GenSigTimeoutTime_HU_B" SG_ 946 FrontFogTelltale 2500;
BA_ "GenSigTimeoutTime_HU_A" SG_ 946 FrontFogTelltale 2500;
BA_ "GenSigTimeoutMsg_HU_Mid_X451" SG_ 946 FrontFogTelltale 2500;
BA_ "GenSigTimeoutMsg_HU_High_X451" SG_ 946 FrontFogTelltale 2500;
BA_ "GenSigTimeoutMsg_HU_B" SG_ 946 FrontFogTelltale 2500;
BA_ "GenSigTimeoutMsg_HU_A" SG_ 946 FrontFogTelltale 2500;
BA_ "GenSigSendType" SG_ 946 FrontFogTelltale 7;
BA_ "GenSigCycleTimeActive" SG_ 946 FrontFogTelltale 500;
BA_ "GenSigCycleTime" SG_ 946 FrontFogTelltale 500;
BA_ "GenSigTimeoutMsg_HU_High_X445" SG_ 946 FrontFogTelltale 2500;
BA_ "GenSigTimeoutMsg_HU_Mid_X445" SG_ 946 FrontFogTelltale 2500;
BA_ "GenSigTimeoutTime_HU_High_X445" SG_ 946 FrontFogTelltale 2500;
BA_ "GenSigTimeoutTime_HU_Mid_X445" SG_ 946 FrontFogTelltale 2500;
BA_ "GenSigTimeoutMsg_IVI" SG_ 946 FrontFogTelltale 2500;
BA_ "GenSigTimeoutTime_IVI" SG_ 946 FrontFogTelltale 2500;
BA_ "GenSigTimeoutTime_HU_Mid_X451" SG_ 946 RearFogTelltaleStatus 2500;
BA_ "GenSigTimeoutTime_HU_High_X451" SG_ 946 RearFogTelltaleStatus 2500;
BA_ "GenSigTimeoutTime_HU_B" SG_ 946 RearFogTelltaleStatus 2500;
BA_ "GenSigTimeoutTime_HU_A" SG_ 946 RearFogTelltaleStatus 2500;
BA_ "GenSigTimeoutMsg_HU_Mid_X451" SG_ 946 RearFogTelltaleStatus 2500;
BA_ "GenSigTimeoutMsg_HU_High_X451" SG_ 946 RearFogTelltaleStatus 2500;
BA_ "GenSigTimeoutMsg_HU_B" SG_ 946 RearFogTelltaleStatus 2500;
BA_ "GenSigTimeoutMsg_HU_A" SG_ 946 RearFogTelltaleStatus 2500;
BA_ "GenSigSendType" SG_ 946 RearFogTelltaleStatus 7;
BA_ "GenSigCycleTimeActive" SG_ 946 RearFogTelltaleStatus 500;
BA_ "GenSigCycleTime" SG_ 946 RearFogTelltaleStatus 500;
BA_ "GenSigTimeoutMsg_HU_High_X445" SG_ 946 RearFogTelltaleStatus 2500;
BA_ "GenSigTimeoutMsg_HU_Mid_X445" SG_ 946 RearFogTelltaleStatus 2500;
BA_ "GenSigTimeoutTime_HU_High_X445" SG_ 946 RearFogTelltaleStatus 2500;
BA_ "GenSigTimeoutTime_HU_Mid_X445" SG_ 946 RearFogTelltaleStatus 2500;
BA_ "GenSigTimeoutMsg_IVI" SG_ 946 RearFogTelltaleStatus 2500;
BA_ "GenSigTimeoutTime_IVI" SG_ 946 RearFogTelltaleStatus 2500;
BA_ "GenSigTimeoutTime_HU_Mid_X451" SG_ 946 FrontFogTelltaleStatus 2500;
BA_ "GenSigTimeoutTime_HU_High_X451" SG_ 946 FrontFogTelltaleStatus 2500;
BA_ "GenSigTimeoutTime_HU_B" SG_ 946 FrontFogTelltaleStatus 2500;
BA_ "GenSigTimeoutTime_HU_A" SG_ 946 FrontFogTelltaleStatus 2500;
BA_ "GenSigTimeoutMsg_HU_Mid_X451" SG_ 946 FrontFogTelltaleStatus 2500;
BA_ "GenSigTimeoutMsg_HU_High_X451" SG_ 946 FrontFogTelltaleStatus 2500;
BA_ "GenSigTimeoutMsg_HU_B" SG_ 946 FrontFogTelltaleStatus 2500;
BA_ "GenSigTimeoutMsg_HU_A" SG_ 946 FrontFogTelltaleStatus 2500;
BA_ "GenSigSendType" SG_ 946 FrontFogTelltaleStatus 7;
BA_ "GenSigCycleTimeActive" SG_ 946 FrontFogTelltaleStatus 500;
BA_ "GenSigCycleTime" SG_ 946 FrontFogTelltaleStatus 500;
BA_ "GenSigTimeoutMsg_HU_High_X445" SG_ 946 FrontFogTelltaleStatus 2500;
BA_ "GenSigTimeoutMsg_HU_Mid_X445" SG_ 946 FrontFogTelltaleStatus 2500;
BA_ "GenSigTimeoutTime_HU_High_X445" SG_ 946 FrontFogTelltaleStatus 2500;
BA_ "GenSigTimeoutTime_HU_Mid_X445" SG_ 946 FrontFogTelltaleStatus 2500;
BA_ "GenSigTimeoutMsg_IVI" SG_ 946 FrontFogTelltaleStatus 2500;
BA_ "GenSigTimeoutTime_IVI" SG_ 946 FrontFogTelltaleStatus 2500;
BA_ "GenSigTimeoutTime_HU_Mid_X451" SG_ 946 DRLTelltaleStatus 2500;
BA_ "GenSigTimeoutTime_HU_High_X451" SG_ 946 DRLTelltaleStatus 2500;
BA_ "GenSigTimeoutTime_HU_B" SG_ 946 DRLTelltaleStatus 2500;
BA_ "GenSigTimeoutTime_HU_A" SG_ 946 DRLTelltaleStatus 2500;
BA_ "GenSigTimeoutMsg_HU_Mid_X451" SG_ 946 DRLTelltaleStatus 2500;
BA_ "GenSigTimeoutMsg_HU_High_X451" SG_ 946 DRLTelltaleStatus 2500;
BA_ "GenSigTimeoutMsg_HU_B" SG_ 946 DRLTelltaleStatus 2500;
BA_ "GenSigTimeoutMsg_HU_A" SG_ 946 DRLTelltaleStatus 2500;
BA_ "GenSigSendType" SG_ 946 DRLTelltaleStatus 7;
BA_ "GenSigCycleTimeActive" SG_ 946 DRLTelltaleStatus 500;
BA_ "GenSigCycleTime" SG_ 946 DRLTelltaleStatus 500;
BA_ "GenSigTimeoutMsg_HU_High_X445" SG_ 946 DRLTelltaleStatus 2500;
BA_ "GenSigTimeoutMsg_HU_Mid_X445" SG_ 946 DRLTelltaleStatus 2500;
BA_ "GenSigTimeoutTime_HU_High_X445" SG_ 946 DRLTelltaleStatus 2500;
BA_ "GenSigTimeoutTime_HU_Mid_X445" SG_ 946 DRLTelltaleStatus 2500;
BA_ "GenSigTimeoutMsg_IVI" SG_ 946 DRLTelltaleStatus 2500;
BA_ "GenSigTimeoutTime_IVI" SG_ 946 DRLTelltaleStatus 2500;
BA_ "GenSigTimeoutTime_HU_Mid_X451" SG_ 946 InfoTheftMsg 2500;
BA_ "GenSigTimeoutTime_HU_B" SG_ 946 InfoTheftMsg 2500;
BA_ "GenSigTimeoutTime_HU_A" SG_ 946 InfoTheftMsg 2500;
BA_ "GenSigTimeoutMsg_HU_Mid_X451" SG_ 946 InfoTheftMsg 2500;
BA_ "GenSigTimeoutMsg_HU_High_X451" SG_ 946 InfoTheftMsg 2500;
BA_ "GenSigTimeoutMsg_HU_B" SG_ 946 InfoTheftMsg 2500;
BA_ "GenSigTimeoutMsg_HU_A" SG_ 946 InfoTheftMsg 2500;
BA_ "GenSigSendType" SG_ 946 InfoTheftMsg 7;
BA_ "GenSigCycleTimeActive" SG_ 946 InfoTheftMsg 500;
BA_ "GenSigCycleTime" SG_ 946 InfoTheftMsg 500;
BA_ "GenSigTimeoutMsg_HU_High_X445" SG_ 946 InfoTheftMsg 2500;
BA_ "GenSigTimeoutMsg_HU_Mid_X445" SG_ 946 InfoTheftMsg 2500;
BA_ "GenSigTimeoutTime_HU_High_X445" SG_ 946 InfoTheftMsg 2500;
BA_ "GenSigTimeoutTime_HU_Mid_X445" SG_ 946 InfoTheftMsg 2500;
BA_ "GenSigTimeoutMsg_IVI" SG_ 946 InfoTheftMsg 2500;
BA_ "GenSigTimeoutTime_IVI" SG_ 946 InfoTheftMsg 2500;
BA_ "GenSigTimeoutTime_HU_B" SG_ 946 WiperHighLowIntermtStateStatus 0;
BA_ "GenSigTimeoutTime_HU_A" SG_ 946 WiperHighLowIntermtStateStatus 0;
BA_ "GenSigTimeoutMsg_HU_B" SG_ 946 WiperHighLowIntermtStateStatus 0;
BA_ "GenSigTimeoutMsg_HU_A" SG_ 946 WiperHighLowIntermtStateStatus 0;
BA_ "GenSigSendType" SG_ 946 WiperHighLowIntermtStateStatus 7;
BA_ "GenSigCycleTimeActive" SG_ 946 WiperHighLowIntermtStateStatus 500;
BA_ "GenSigCycleTime" SG_ 946 WiperHighLowIntermtStateStatus 500;
BA_ "GenSigTimeoutTime_HU_B" SG_ 946 WiperHighLowIntermtState 0;
BA_ "GenSigTimeoutTime_HU_A" SG_ 946 WiperHighLowIntermtState 0;
BA_ "GenSigTimeoutMsg_HU_B" SG_ 946 WiperHighLowIntermtState 0;
BA_ "GenSigTimeoutMsg_HU_A" SG_ 946 WiperHighLowIntermtState 0;
BA_ "GenSigSendType" SG_ 946 WiperHighLowIntermtState 7;
BA_ "GenSigCycleTimeActive" SG_ 946 WiperHighLowIntermtState 500;
BA_ "GenSigCycleTime" SG_ 946 WiperHighLowIntermtState 500;
BA_ "GenSigTimeoutTime_HU_Mid_X451" SG_ 946 LowBeamMalFnStatus 2500;
BA_ "GenSigTimeoutTime_HU_High_X451" SG_ 946 LowBeamMalFnStatus 2500;
BA_ "GenSigTimeoutTime_HU_B" SG_ 946 LowBeamMalFnStatus 2500;
BA_ "GenSigTimeoutTime_HU_A" SG_ 946 LowBeamMalFnStatus 2500;
BA_ "GenSigTimeoutMsg_HU_Mid_X451" SG_ 946 LowBeamMalFnStatus 2500;
BA_ "GenSigTimeoutMsg_HU_High_X451" SG_ 946 LowBeamMalFnStatus 2500;
BA_ "GenSigTimeoutMsg_HU_B" SG_ 946 LowBeamMalFnStatus 2500;
BA_ "GenSigTimeoutMsg_HU_A" SG_ 946 LowBeamMalFnStatus 2500;
BA_ "GenSigSendType" SG_ 946 LowBeamMalFnStatus 7;
BA_ "GenSigCycleTimeActive" SG_ 946 LowBeamMalFnStatus 500;
BA_ "GenSigCycleTime" SG_ 946 LowBeamMalFnStatus 500;
BA_ "GenSigTimeoutMsg_HU_High_X445" SG_ 946 LowBeamMalFnStatus 2500;
BA_ "GenSigTimeoutMsg_HU_Mid_X445" SG_ 946 LowBeamMalFnStatus 2500;
BA_ "GenSigTimeoutTime_HU_High_X445" SG_ 946 LowBeamMalFnStatus 2500;
BA_ "GenSigTimeoutTime_HU_Mid_X445" SG_ 946 LowBeamMalFnStatus 2500;
BA_ "GenSigTimeoutMsg_IVI" SG_ 946 LowBeamMalFnStatus 2500;
BA_ "GenSigTimeoutTime_IVI" SG_ 946 LowBeamMalFnStatus 2500;
BA_ "GenSigTimeoutTime_HU_B" SG_ 946 ESSSwSig 0;
BA_ "GenSigTimeoutTime_HU_A" SG_ 946 ESSSwSig 0;
BA_ "GenSigTimeoutMsg_HU_B" SG_ 946 ESSSwSig 0;
BA_ "GenSigTimeoutMsg_HU_A" SG_ 946 ESSSwSig 0;
BA_ "GenSigSendType" SG_ 946 ESSSwSig 7;
BA_ "GenSigCycleTimeActive" SG_ 946 ESSSwSig 500;
BA_ "GenSigCycleTime" SG_ 946 ESSSwSig 500;
BA_ "GenSigTimeoutTime_HU_B" SG_ 946 BonnetState 0;
BA_ "GenSigTimeoutTime_HU_A" SG_ 946 BonnetState 0;
BA_ "GenSigTimeoutMsg_HU_B" SG_ 946 BonnetState 0;
BA_ "GenSigTimeoutMsg_HU_A" SG_ 946 BonnetState 0;
BA_ "GenSigSendType" SG_ 946 BonnetState 7;
BA_ "GenSigCycleTimeActive" SG_ 946 BonnetState 500;
BA_ "GenSigCycleTime" SG_ 946 BonnetState 500;
BA_ "GenSigTimeoutTime_HU_Mid_X451" SG_ 946 RearFogTelltale 2500;
BA_ "GenSigTimeoutTime_HU_High_X451" SG_ 946 RearFogTelltale 2500;
BA_ "GenSigTimeoutTime_HU_B" SG_ 946 RearFogTelltale 2500;
BA_ "GenSigTimeoutTime_HU_A" SG_ 946 RearFogTelltale 2500;
BA_ "GenSigTimeoutMsg_HU_Mid_X451" SG_ 946 RearFogTelltale 2500;
BA_ "GenSigTimeoutMsg_HU_High_X451" SG_ 946 RearFogTelltale 2500;
BA_ "GenSigTimeoutMsg_HU_B" SG_ 946 RearFogTelltale 2500;
BA_ "GenSigTimeoutMsg_HU_A" SG_ 946 RearFogTelltale 2500;
BA_ "GenSigSendType" SG_ 946 RearFogTelltale 7;
BA_ "GenSigCycleTimeActive" SG_ 946 RearFogTelltale 500;
BA_ "GenSigCycleTime" SG_ 946 RearFogTelltale 500;
BA_ "GenSigTimeoutMsg_HU_High_X445" SG_ 946 RearFogTelltale 2500;
BA_ "GenSigTimeoutMsg_HU_Mid_X445" SG_ 946 RearFogTelltale 2500;
BA_ "GenSigTimeoutTime_HU_High_X445" SG_ 946 RearFogTelltale 2500;
BA_ "GenSigTimeoutTime_HU_Mid_X445" SG_ 946 RearFogTelltale 2500;
BA_ "GenSigTimeoutMsg_IVI" SG_ 946 RearFogTelltale 2500;
BA_ "GenSigTimeoutTime_IVI" SG_ 946 RearFogTelltale 2500;
BA_ "GenSigTimeoutTime_HU_B" SG_ 946 BonnetStateStatus 0;
BA_ "GenSigTimeoutTime_HU_A" SG_ 946 BonnetStateStatus 0;
BA_ "GenSigTimeoutMsg_HU_B" SG_ 946 BonnetStateStatus 0;
BA_ "GenSigTimeoutMsg_HU_A" SG_ 946 BonnetStateStatus 0;
BA_ "GenSigSendType" SG_ 946 BonnetStateStatus 7;
BA_ "GenSigCycleTimeActive" SG_ 946 BonnetStateStatus 500;
BA_ "GenSigCycleTime" SG_ 946 BonnetStateStatus 500;
BA_ "GenSigTimeoutTime_HU_B" SG_ 946 VehicleUnLockTypeConfgStatus 0;
BA_ "GenSigTimeoutTime_HU_A" SG_ 946 VehicleUnLockTypeConfgStatus 0;
BA_ "GenSigTimeoutMsg_HU_B" SG_ 946 VehicleUnLockTypeConfgStatus 0;
BA_ "GenSigTimeoutMsg_HU_A" SG_ 946 VehicleUnLockTypeConfgStatus 0;
BA_ "GenSigSendType" SG_ 946 VehicleUnLockTypeConfgStatus 7;
BA_ "GenSigCycleTimeActive" SG_ 946 VehicleUnLockTypeConfgStatus 500;
BA_ "GenSigCycleTime" SG_ 946 VehicleUnLockTypeConfgStatus 500;
BA_ "GenSigTimeoutTime_HU_B" SG_ 946 VehicleUnLockTypeConfg 0;
BA_ "GenSigTimeoutTime_HU_A" SG_ 946 VehicleUnLockTypeConfg 0;
BA_ "GenSigTimeoutMsg_HU_B" SG_ 946 VehicleUnLockTypeConfg 0;
BA_ "GenSigTimeoutMsg_HU_A" SG_ 946 VehicleUnLockTypeConfg 0;
BA_ "GenSigSendType" SG_ 946 VehicleUnLockTypeConfg 7;
BA_ "GenSigCycleTimeActive" SG_ 946 VehicleUnLockTypeConfg 500;
BA_ "GenSigCycleTime" SG_ 946 VehicleUnLockTypeConfg 500;
BA_ "GenSigTimeoutTime_HU_B" SG_ 946 ESSSwSigStatus 0;
BA_ "GenSigTimeoutTime_HU_A" SG_ 946 ESSSwSigStatus 0;
BA_ "GenSigTimeoutMsg_HU_B" SG_ 946 ESSSwSigStatus 0;
BA_ "GenSigTimeoutMsg_HU_A" SG_ 946 ESSSwSigStatus 0;
BA_ "GenSigStartValue" SG_ 946 ESSSwSigStatus 2;
BA_ "GenSigSendType" SG_ 946 ESSSwSigStatus 7;
BA_ "GenSigCycleTimeActive" SG_ 946 ESSSwSigStatus 500;
BA_ "GenSigCycleTime" SG_ 946 ESSSwSigStatus 500;
BA_ "GenSigSendType" SG_ 948 OdoICFullSigPeriodic 7;
BA_ "GenSigCycleTimeActive" SG_ 948 OdoICFullSigPeriodic 500;
BA_ "GenSigCycleTime" SG_ 948 OdoICFullSigPeriodic 500;
BA_ "GenSigSendType" SG_ 948 OdoICFullSigPeriodicStatus 7;
BA_ "GenSigCycleTimeActive" SG_ 948 OdoICFullSigPeriodicStatus 500;
BA_ "GenSigCycleTime" SG_ 948 OdoICFullSigPeriodicStatus 500;
BA_ "GenSigSendType" SG_ 948 OATRawVoltage 7;
BA_ "GenSigCycleTimeActive" SG_ 948 OATRawVoltage 100;
BA_ "GenSigCycleTime" SG_ 948 OATRawVoltage 100;
BA_ "GenSigTimeoutTime_HU_Mid_X451" SG_ 950 TrailerPositionLmpMalFnToIpc 2500;
BA_ "GenSigTimeoutTime_HU_High_X451" SG_ 950 TrailerPositionLmpMalFnToIpc 2500;
BA_ "GenSigTimeoutTime_HU_B" SG_ 950 TrailerPositionLmpMalFnToIpc 2500;
BA_ "GenSigTimeoutTime_HU_A" SG_ 950 TrailerPositionLmpMalFnToIpc 2500;
BA_ "GenSigTimeoutMsg_HU_Mid_X451" SG_ 950 TrailerPositionLmpMalFnToIpc 2500;
BA_ "GenSigTimeoutMsg_HU_High_X451" SG_ 950 TrailerPositionLmpMalFnToIpc 2500;
BA_ "GenSigTimeoutMsg_HU_B" SG_ 950 TrailerPositionLmpMalFnToIpc 2500;
BA_ "GenSigTimeoutMsg_HU_A" SG_ 950 TrailerPositionLmpMalFnToIpc 2500;
BA_ "GenSigSendType" SG_ 950 TrailerPositionLmpMalFnToIpc 7;
BA_ "GenSigCycleTimeActive" SG_ 950 TrailerPositionLmpMalFnToIpc 500;
BA_ "GenSigCycleTime" SG_ 950 TrailerPositionLmpMalFnToIpc 500;
BA_ "GenSigTimeoutMsg_HU_High_X445" SG_ 950 TrailerPositionLmpMalFnToIpc 2500;
BA_ "GenSigTimeoutMsg_HU_Mid_X445" SG_ 950 TrailerPositionLmpMalFnToIpc 2500;
BA_ "GenSigTimeoutTime_HU_High_X445" SG_ 950 TrailerPositionLmpMalFnToIpc 2500;
BA_ "GenSigTimeoutTime_HU_Mid_X445" SG_ 950 TrailerPositionLmpMalFnToIpc 2500;
BA_ "GenSigTimeoutMsg_IVI" SG_ 950 TrailerPositionLmpMalFnToIpc 2500;
BA_ "GenSigTimeoutTime_IVI" SG_ 950 TrailerPositionLmpMalFnToIpc 2500;
BA_ "GenSigTimeoutTime_HU_Mid_X451" SG_ 950 TrailerPositionLmpMalFnToIpcStat 2500;
BA_ "GenSigTimeoutTime_HU_High_X451" SG_ 950 TrailerPositionLmpMalFnToIpcStat 2500;
BA_ "GenSigTimeoutTime_HU_B" SG_ 950 TrailerPositionLmpMalFnToIpcStat 2500;
BA_ "GenSigTimeoutTime_HU_A" SG_ 950 TrailerPositionLmpMalFnToIpcStat 2500;
BA_ "GenSigTimeoutMsg_HU_Mid_X451" SG_ 950 TrailerPositionLmpMalFnToIpcStat 2500;
BA_ "GenSigTimeoutMsg_HU_High_X451" SG_ 950 TrailerPositionLmpMalFnToIpcStat 2500;
BA_ "GenSigTimeoutMsg_HU_B" SG_ 950 TrailerPositionLmpMalFnToIpcStat 2500;
BA_ "GenSigTimeoutMsg_HU_A" SG_ 950 TrailerPositionLmpMalFnToIpcStat 2500;
BA_ "GenSigSendType" SG_ 950 TrailerPositionLmpMalFnToIpcStat 7;
BA_ "GenSigCycleTimeActive" SG_ 950 TrailerPositionLmpMalFnToIpcStat 500;
BA_ "GenSigCycleTime" SG_ 950 TrailerPositionLmpMalFnToIpcStat 500;
BA_ "GenSigTimeoutMsg_HU_High_X445" SG_ 950 TrailerPositionLmpMalFnToIpcStat 2500;
BA_ "GenSigTimeoutMsg_HU_Mid_X445" SG_ 950 TrailerPositionLmpMalFnToIpcStat 2500;
BA_ "GenSigTimeoutTime_HU_High_X445" SG_ 950 TrailerPositionLmpMalFnToIpcStat 2500;
BA_ "GenSigTimeoutTime_HU_Mid_X445" SG_ 950 TrailerPositionLmpMalFnToIpcStat 2500;
BA_ "GenSigTimeoutMsg_IVI" SG_ 950 TrailerPositionLmpMalFnToIpcStat 2500;
BA_ "GenSigTimeoutTime_IVI" SG_ 950 TrailerPositionLmpMalFnToIpcStat 2500;
BA_ "SystemSignalLongSymbol" SG_ 950 TrailerPositionLmpMalFnToIpcStat "TrailerPositionLmpMalFnToIpcStatus";
BA_ "GenSigTimeoutTime_HU_Mid_X451" SG_ 950 TrailerRevLmpMalFnToIpc 2500;
BA_ "GenSigTimeoutTime_HU_High_X451" SG_ 950 TrailerRevLmpMalFnToIpc 2500;
BA_ "GenSigTimeoutTime_HU_B" SG_ 950 TrailerRevLmpMalFnToIpc 2500;
BA_ "GenSigTimeoutTime_HU_A" SG_ 950 TrailerRevLmpMalFnToIpc 2500;
BA_ "GenSigTimeoutMsg_HU_Mid_X451" SG_ 950 TrailerRevLmpMalFnToIpc 2500;
BA_ "GenSigTimeoutMsg_HU_High_X451" SG_ 950 TrailerRevLmpMalFnToIpc 2500;
BA_ "GenSigTimeoutMsg_HU_B" SG_ 950 TrailerRevLmpMalFnToIpc 2500;
BA_ "GenSigTimeoutMsg_HU_A" SG_ 950 TrailerRevLmpMalFnToIpc 2500;
BA_ "GenSigSendType" SG_ 950 TrailerRevLmpMalFnToIpc 7;
BA_ "GenSigCycleTimeActive" SG_ 950 TrailerRevLmpMalFnToIpc 500;
BA_ "GenSigCycleTime" SG_ 950 TrailerRevLmpMalFnToIpc 500;
BA_ "GenSigTimeoutMsg_HU_High_X445" SG_ 950 TrailerRevLmpMalFnToIpc 2500;
BA_ "GenSigTimeoutMsg_HU_Mid_X445" SG_ 950 TrailerRevLmpMalFnToIpc 2500;
BA_ "GenSigTimeoutTime_HU_High_X445" SG_ 950 TrailerRevLmpMalFnToIpc 2500;
BA_ "GenSigTimeoutTime_HU_Mid_X445" SG_ 950 TrailerRevLmpMalFnToIpc 2500;
BA_ "GenSigTimeoutMsg_IVI" SG_ 950 TrailerRevLmpMalFnToIpc 2500;
BA_ "GenSigTimeoutTime_IVI" SG_ 950 TrailerRevLmpMalFnToIpc 2500;
BA_ "GenSigTimeoutTime_HU_Mid_X451" SG_ 950 TrailerRevLmpMalFnToIpcStatus 2500;
BA_ "GenSigTimeoutTime_HU_High_X451" SG_ 950 TrailerRevLmpMalFnToIpcStatus 2500;
BA_ "GenSigTimeoutTime_HU_B" SG_ 950 TrailerRevLmpMalFnToIpcStatus 2500;
BA_ "GenSigTimeoutTime_HU_A" SG_ 950 TrailerRevLmpMalFnToIpcStatus 2500;
BA_ "GenSigTimeoutMsg_HU_Mid_X451" SG_ 950 TrailerRevLmpMalFnToIpcStatus 2500;
BA_ "GenSigTimeoutMsg_HU_High_X451" SG_ 950 TrailerRevLmpMalFnToIpcStatus 2500;
BA_ "GenSigTimeoutMsg_HU_B" SG_ 950 TrailerRevLmpMalFnToIpcStatus 2500;
BA_ "GenSigTimeoutMsg_HU_A" SG_ 950 TrailerRevLmpMalFnToIpcStatus 2500;
BA_ "GenSigSendType" SG_ 950 TrailerRevLmpMalFnToIpcStatus 7;
BA_ "GenSigCycleTimeActive" SG_ 950 TrailerRevLmpMalFnToIpcStatus 500;
BA_ "GenSigCycleTime" SG_ 950 TrailerRevLmpMalFnToIpcStatus 500;
BA_ "GenSigTimeoutMsg_HU_High_X445" SG_ 950 TrailerRevLmpMalFnToIpcStatus 2500;
BA_ "GenSigTimeoutMsg_HU_Mid_X445" SG_ 950 TrailerRevLmpMalFnToIpcStatus 2500;
BA_ "GenSigTimeoutTime_HU_High_X445" SG_ 950 TrailerRevLmpMalFnToIpcStatus 2500;
BA_ "GenSigTimeoutTime_HU_Mid_X445" SG_ 950 TrailerRevLmpMalFnToIpcStatus 2500;
BA_ "GenSigTimeoutMsg_IVI" SG_ 950 TrailerRevLmpMalFnToIpcStatus 2500;
BA_ "GenSigTimeoutTime_IVI" SG_ 950 TrailerRevLmpMalFnToIpcStatus 2500;
BA_ "GenSigTimeoutTime_HU_Mid_X451" SG_ 950 TrailerFogMalFnToIpcStatus 2500;
BA_ "GenSigTimeoutTime_HU_High_X451" SG_ 950 TrailerFogMalFnToIpcStatus 2500;
BA_ "GenSigTimeoutTime_HU_B" SG_ 950 TrailerFogMalFnToIpcStatus 2500;
BA_ "GenSigTimeoutTime_HU_A" SG_ 950 TrailerFogMalFnToIpcStatus 2500;
BA_ "GenSigTimeoutMsg_HU_Mid_X451" SG_ 950 TrailerFogMalFnToIpcStatus 2500;
BA_ "GenSigTimeoutMsg_HU_High_X451" SG_ 950 TrailerFogMalFnToIpcStatus 2500;
BA_ "GenSigTimeoutMsg_HU_B" SG_ 950 TrailerFogMalFnToIpcStatus 2500;
BA_ "GenSigTimeoutMsg_HU_A" SG_ 950 TrailerFogMalFnToIpcStatus 2500;
BA_ "GenSigSendType" SG_ 950 TrailerFogMalFnToIpcStatus 7;
BA_ "GenSigCycleTimeActive" SG_ 950 TrailerFogMalFnToIpcStatus 500;
BA_ "GenSigCycleTime" SG_ 950 TrailerFogMalFnToIpcStatus 500;
BA_ "GenSigTimeoutMsg_HU_High_X445" SG_ 950 TrailerFogMalFnToIpcStatus 2500;
BA_ "GenSigTimeoutMsg_HU_Mid_X445" SG_ 950 TrailerFogMalFnToIpcStatus 2500;
BA_ "GenSigTimeoutTime_HU_High_X445" SG_ 950 TrailerFogMalFnToIpcStatus 2500;
BA_ "GenSigTimeoutTime_HU_Mid_X445" SG_ 950 TrailerFogMalFnToIpcStatus 2500;
BA_ "GenSigTimeoutMsg_IVI" SG_ 950 TrailerFogMalFnToIpcStatus 2500;
BA_ "GenSigTimeoutTime_IVI" SG_ 950 TrailerFogMalFnToIpcStatus 2500;
BA_ "GenSigTimeoutTime_HU_Mid_X451" SG_ 950 TrailerFogMalFnToIpc 2500;
BA_ "GenSigTimeoutTime_HU_High_X451" SG_ 950 TrailerFogMalFnToIpc 2500;
BA_ "GenSigTimeoutTime_HU_B" SG_ 950 TrailerFogMalFnToIpc 2500;
BA_ "GenSigTimeoutTime_HU_A" SG_ 950 TrailerFogMalFnToIpc 2500;
BA_ "GenSigTimeoutMsg_HU_Mid_X451" SG_ 950 TrailerFogMalFnToIpc 2500;
BA_ "GenSigTimeoutMsg_HU_High_X451" SG_ 950 TrailerFogMalFnToIpc 2500;
BA_ "GenSigTimeoutMsg_HU_B" SG_ 950 TrailerFogMalFnToIpc 2500;
BA_ "GenSigTimeoutMsg_HU_A" SG_ 950 TrailerFogMalFnToIpc 2500;
BA_ "GenSigSendType" SG_ 950 TrailerFogMalFnToIpc 7;
BA_ "GenSigCycleTimeActive" SG_ 950 TrailerFogMalFnToIpc 500;
BA_ "GenSigCycleTime" SG_ 950 TrailerFogMalFnToIpc 500;
BA_ "GenSigTimeoutMsg_HU_High_X445" SG_ 950 TrailerFogMalFnToIpc 2500;
BA_ "GenSigTimeoutMsg_HU_Mid_X445" SG_ 950 TrailerFogMalFnToIpc 2500;
BA_ "GenSigTimeoutTime_HU_High_X445" SG_ 950 TrailerFogMalFnToIpc 2500;
BA_ "GenSigTimeoutTime_HU_Mid_X445" SG_ 950 TrailerFogMalFnToIpc 2500;
BA_ "GenSigTimeoutMsg_IVI" SG_ 950 TrailerFogMalFnToIpc 2500;
BA_ "GenSigTimeoutTime_IVI" SG_ 950 TrailerFogMalFnToIpc 2500;
BA_ "GenSigTimeoutTime_HU_Mid_X451" SG_ 950 TrailerTurnRhMalFnToIpc 2500;
BA_ "GenSigTimeoutTime_HU_High_X451" SG_ 950 TrailerTurnRhMalFnToIpc 2500;
BA_ "GenSigTimeoutTime_HU_B" SG_ 950 TrailerTurnRhMalFnToIpc 2500;
BA_ "GenSigTimeoutTime_HU_A" SG_ 950 TrailerTurnRhMalFnToIpc 2500;
BA_ "GenSigTimeoutMsg_HU_Mid_X451" SG_ 950 TrailerTurnRhMalFnToIpc 2500;
BA_ "GenSigTimeoutMsg_HU_High_X451" SG_ 950 TrailerTurnRhMalFnToIpc 2500;
BA_ "GenSigTimeoutMsg_HU_B" SG_ 950 TrailerTurnRhMalFnToIpc 2500;
BA_ "GenSigTimeoutMsg_HU_A" SG_ 950 TrailerTurnRhMalFnToIpc 2500;
BA_ "GenSigSendType" SG_ 950 TrailerTurnRhMalFnToIpc 7;
BA_ "GenSigCycleTimeActive" SG_ 950 TrailerTurnRhMalFnToIpc 500;
BA_ "GenSigCycleTime" SG_ 950 TrailerTurnRhMalFnToIpc 500;
BA_ "GenSigTimeoutMsg_HU_High_X445" SG_ 950 TrailerTurnRhMalFnToIpc 2500;
BA_ "GenSigTimeoutMsg_HU_Mid_X445" SG_ 950 TrailerTurnRhMalFnToIpc 2500;
BA_ "GenSigTimeoutTime_HU_High_X445" SG_ 950 TrailerTurnRhMalFnToIpc 2500;
BA_ "GenSigTimeoutTime_HU_Mid_X445" SG_ 950 TrailerTurnRhMalFnToIpc 2500;
BA_ "GenSigTimeoutMsg_IVI" SG_ 950 TrailerTurnRhMalFnToIpc 2500;
BA_ "GenSigTimeoutTime_IVI" SG_ 950 TrailerTurnRhMalFnToIpc 2500;
BA_ "GenSigTimeoutTime_HU_Mid_X451" SG_ 950 TrailerTurnLhMalFnToIpcStatus 2500;
BA_ "GenSigTimeoutTime_HU_High_X451" SG_ 950 TrailerTurnLhMalFnToIpcStatus 2500;
BA_ "GenSigTimeoutTime_HU_B" SG_ 950 TrailerTurnLhMalFnToIpcStatus 2500;
BA_ "GenSigTimeoutTime_HU_A" SG_ 950 TrailerTurnLhMalFnToIpcStatus 2500;
BA_ "GenSigTimeoutMsg_HU_Mid_X451" SG_ 950 TrailerTurnLhMalFnToIpcStatus 2500;
BA_ "GenSigTimeoutMsg_HU_High_X451" SG_ 950 TrailerTurnLhMalFnToIpcStatus 2500;
BA_ "GenSigTimeoutMsg_HU_B" SG_ 950 TrailerTurnLhMalFnToIpcStatus 2500;
BA_ "GenSigTimeoutMsg_HU_A" SG_ 950 TrailerTurnLhMalFnToIpcStatus 2500;
BA_ "GenSigSendType" SG_ 950 TrailerTurnLhMalFnToIpcStatus 7;
BA_ "GenSigCycleTimeActive" SG_ 950 TrailerTurnLhMalFnToIpcStatus 500;
BA_ "GenSigCycleTime" SG_ 950 TrailerTurnLhMalFnToIpcStatus 500;
BA_ "GenSigTimeoutMsg_HU_High_X445" SG_ 950 TrailerTurnLhMalFnToIpcStatus 2500;
BA_ "GenSigTimeoutMsg_HU_Mid_X445" SG_ 950 TrailerTurnLhMalFnToIpcStatus 2500;
BA_ "GenSigTimeoutTime_HU_High_X445" SG_ 950 TrailerTurnLhMalFnToIpcStatus 2500;
BA_ "GenSigTimeoutTime_HU_Mid_X445" SG_ 950 TrailerTurnLhMalFnToIpcStatus 2500;
BA_ "GenSigTimeoutMsg_IVI" SG_ 950 TrailerTurnLhMalFnToIpcStatus 2500;
BA_ "GenSigTimeoutTime_IVI" SG_ 950 TrailerTurnLhMalFnToIpcStatus 2500;
BA_ "GenSigTimeoutTime_HU_Mid_X451" SG_ 950 TrailerTurnLhMalFnToIpc 2500;
BA_ "GenSigTimeoutTime_HU_High_X451" SG_ 950 TrailerTurnLhMalFnToIpc 2500;
BA_ "GenSigTimeoutTime_HU_B" SG_ 950 TrailerTurnLhMalFnToIpc 2500;
BA_ "GenSigTimeoutTime_HU_A" SG_ 950 TrailerTurnLhMalFnToIpc 2500;
BA_ "GenSigTimeoutMsg_HU_Mid_X451" SG_ 950 TrailerTurnLhMalFnToIpc 2500;
BA_ "GenSigTimeoutMsg_HU_High_X451" SG_ 950 TrailerTurnLhMalFnToIpc 2500;
BA_ "GenSigTimeoutMsg_HU_B" SG_ 950 TrailerTurnLhMalFnToIpc 2500;
BA_ "GenSigTimeoutMsg_HU_A" SG_ 950 TrailerTurnLhMalFnToIpc 2500;
BA_ "GenSigSendType" SG_ 950 TrailerTurnLhMalFnToIpc 7;
BA_ "GenSigCycleTimeActive" SG_ 950 TrailerTurnLhMalFnToIpc 500;
BA_ "GenSigCycleTime" SG_ 950 TrailerTurnLhMalFnToIpc 500;
BA_ "GenSigTimeoutMsg_HU_High_X445" SG_ 950 TrailerTurnLhMalFnToIpc 2500;
BA_ "GenSigTimeoutMsg_HU_Mid_X445" SG_ 950 TrailerTurnLhMalFnToIpc 2500;
BA_ "GenSigTimeoutTime_HU_High_X445" SG_ 950 TrailerTurnLhMalFnToIpc 2500;
BA_ "GenSigTimeoutTime_HU_Mid_X445" SG_ 950 TrailerTurnLhMalFnToIpc 2500;
BA_ "GenSigTimeoutMsg_IVI" SG_ 950 TrailerTurnLhMalFnToIpc 2500;
BA_ "GenSigTimeoutTime_IVI" SG_ 950 TrailerTurnLhMalFnToIpc 2500;
BA_ "GenSigTimeoutTime_HU_Mid_X451" SG_ 950 TrailerTurnRhMalFnToIpcStatus 2500;
BA_ "GenSigTimeoutTime_HU_High_X451" SG_ 950 TrailerTurnRhMalFnToIpcStatus 2500;
BA_ "GenSigTimeoutTime_HU_B" SG_ 950 TrailerTurnRhMalFnToIpcStatus 2500;
BA_ "GenSigTimeoutTime_HU_A" SG_ 950 TrailerTurnRhMalFnToIpcStatus 2500;
BA_ "GenSigTimeoutMsg_HU_Mid_X451" SG_ 950 TrailerTurnRhMalFnToIpcStatus 2500;
BA_ "GenSigTimeoutMsg_HU_High_X451" SG_ 950 TrailerTurnRhMalFnToIpcStatus 2500;
BA_ "GenSigTimeoutMsg_HU_B" SG_ 950 TrailerTurnRhMalFnToIpcStatus 2500;
BA_ "GenSigTimeoutMsg_HU_A" SG_ 950 TrailerTurnRhMalFnToIpcStatus 2500;
BA_ "GenSigSendType" SG_ 950 TrailerTurnRhMalFnToIpcStatus 7;
BA_ "GenSigCycleTimeActive" SG_ 950 TrailerTurnRhMalFnToIpcStatus 500;
BA_ "GenSigCycleTime" SG_ 950 TrailerTurnRhMalFnToIpcStatus 500;
BA_ "GenSigTimeoutMsg_HU_High_X445" SG_ 950 TrailerTurnRhMalFnToIpcStatus 2500;
BA_ "GenSigTimeoutMsg_HU_Mid_X445" SG_ 950 TrailerTurnRhMalFnToIpcStatus 2500;
BA_ "GenSigTimeoutTime_HU_High_X445" SG_ 950 TrailerTurnRhMalFnToIpcStatus 2500;
BA_ "GenSigTimeoutTime_HU_Mid_X445" SG_ 950 TrailerTurnRhMalFnToIpcStatus 2500;
BA_ "GenSigTimeoutMsg_IVI" SG_ 950 TrailerTurnRhMalFnToIpcStatus 2500;
BA_ "GenSigTimeoutTime_IVI" SG_ 950 TrailerTurnRhMalFnToIpcStatus 2500;
BA_ "GenSigTimeoutTime_HU_Mid_X451" SG_ 950 TrailerBrkLmpMalFnToIpc 2500;
BA_ "GenSigTimeoutTime_HU_High_X451" SG_ 950 TrailerBrkLmpMalFnToIpc 2500;
BA_ "GenSigTimeoutTime_HU_B" SG_ 950 TrailerBrkLmpMalFnToIpc 2500;
BA_ "GenSigTimeoutTime_HU_A" SG_ 950 TrailerBrkLmpMalFnToIpc 2500;
BA_ "GenSigTimeoutMsg_HU_Mid_X451" SG_ 950 TrailerBrkLmpMalFnToIpc 2500;
BA_ "GenSigTimeoutMsg_HU_High_X451" SG_ 950 TrailerBrkLmpMalFnToIpc 2500;
BA_ "GenSigTimeoutMsg_HU_B" SG_ 950 TrailerBrkLmpMalFnToIpc 2500;
BA_ "GenSigTimeoutMsg_HU_A" SG_ 950 TrailerBrkLmpMalFnToIpc 2500;
BA_ "GenSigSendType" SG_ 950 TrailerBrkLmpMalFnToIpc 7;
BA_ "GenSigCycleTimeActive" SG_ 950 TrailerBrkLmpMalFnToIpc 500;
BA_ "GenSigCycleTime" SG_ 950 TrailerBrkLmpMalFnToIpc 500;
BA_ "GenSigTimeoutMsg_HU_High_X445" SG_ 950 TrailerBrkLmpMalFnToIpc 2500;
BA_ "GenSigTimeoutMsg_HU_Mid_X445" SG_ 950 TrailerBrkLmpMalFnToIpc 2500;
BA_ "GenSigTimeoutTime_HU_High_X445" SG_ 950 TrailerBrkLmpMalFnToIpc 2500;
BA_ "GenSigTimeoutTime_HU_Mid_X445" SG_ 950 TrailerBrkLmpMalFnToIpc 2500;
BA_ "GenSigTimeoutMsg_IVI" SG_ 950 TrailerBrkLmpMalFnToIpc 2500;
BA_ "GenSigTimeoutTime_IVI" SG_ 950 TrailerBrkLmpMalFnToIpc 2500;
BA_ "GenSigTimeoutTime_HU_Mid_X451" SG_ 950 TrailerBrkLmpMalFnToIpcStatus 2500;
BA_ "GenSigTimeoutTime_HU_High_X451" SG_ 950 TrailerBrkLmpMalFnToIpcStatus 2500;
BA_ "GenSigTimeoutTime_HU_B" SG_ 950 TrailerBrkLmpMalFnToIpcStatus 2500;
BA_ "GenSigTimeoutTime_HU_A" SG_ 950 TrailerBrkLmpMalFnToIpcStatus 2500;
BA_ "GenSigTimeoutMsg_HU_Mid_X451" SG_ 950 TrailerBrkLmpMalFnToIpcStatus 2500;
BA_ "GenSigTimeoutMsg_HU_High_X451" SG_ 950 TrailerBrkLmpMalFnToIpcStatus 2500;
BA_ "GenSigTimeoutMsg_HU_B" SG_ 950 TrailerBrkLmpMalFnToIpcStatus 2500;
BA_ "GenSigTimeoutMsg_HU_A" SG_ 950 TrailerBrkLmpMalFnToIpcStatus 2500;
BA_ "GenSigSendType" SG_ 950 TrailerBrkLmpMalFnToIpcStatus 7;
BA_ "GenSigCycleTimeActive" SG_ 950 TrailerBrkLmpMalFnToIpcStatus 500;
BA_ "GenSigCycleTime" SG_ 950 TrailerBrkLmpMalFnToIpcStatus 500;
BA_ "GenSigTimeoutMsg_HU_High_X445" SG_ 950 TrailerBrkLmpMalFnToIpcStatus 2500;
BA_ "GenSigTimeoutMsg_HU_Mid_X445" SG_ 950 TrailerBrkLmpMalFnToIpcStatus 2500;
BA_ "GenSigTimeoutTime_HU_High_X445" SG_ 950 TrailerBrkLmpMalFnToIpcStatus 2500;
BA_ "GenSigTimeoutTime_HU_Mid_X445" SG_ 950 TrailerBrkLmpMalFnToIpcStatus 2500;
BA_ "GenSigTimeoutMsg_IVI" SG_ 950 TrailerBrkLmpMalFnToIpcStatus 2500;
BA_ "GenSigTimeoutTime_IVI" SG_ 950 TrailerBrkLmpMalFnToIpcStatus 2500;
BA_ "GenSigTimeoutTime_HU_Mid_X451" SG_ 1068 IcHuVcInfo 5000;
BA_ "GenSigTimeoutTime_HU_High_X451" SG_ 1068 IcHuVcInfo 5000;
BA_ "GenSigTimeoutTime_HU_B" SG_ 1068 IcHuVcInfo 5000;
BA_ "GenSigTimeoutTime_HU_A" SG_ 1068 IcHuVcInfo 5000;
BA_ "GenSigTimeoutMsg_HU_Mid_X451" SG_ 1068 IcHuVcInfo 5000;
BA_ "GenSigTimeoutMsg_HU_High_X451" SG_ 1068 IcHuVcInfo 5000;
BA_ "GenSigTimeoutMsg_HU_B" SG_ 1068 IcHuVcInfo 5000;
BA_ "GenSigTimeoutMsg_HU_A" SG_ 1068 IcHuVcInfo 5000;
BA_ "GenSigSendType" SG_ 1068 IcHuVcInfo 7;
BA_ "GenSigCycleTimeActive" SG_ 1068 IcHuVcInfo 1000;
BA_ "GenSigCycleTime" SG_ 1068 IcHuVcInfo 1000;
BA_ "GenSigTimeoutMsg_HU_High_X445" SG_ 1068 IcHuVcInfo 5000;
BA_ "GenSigTimeoutMsg_HU_Mid_X445" SG_ 1068 IcHuVcInfo 5000;
BA_ "GenSigTimeoutTime_HU_High_X445" SG_ 1068 IcHuVcInfo 5000;
BA_ "GenSigTimeoutTime_HU_Mid_X445" SG_ 1068 IcHuVcInfo 5000;
BA_ "GenSigTimeoutMsg_IVI" SG_ 1068 IcHuVcInfo 5000;
BA_ "GenSigTimeoutTime_IVI" SG_ 1068 IcHuVcInfo 5000;
BA_ "GenSigTimeoutTime_HU_Mid_X451" SG_ 1068 ICDrvModeFunVariant 5000;
BA_ "GenSigTimeoutTime_HU_High_X451" SG_ 1068 ICDrvModeFunVariant 5000;
BA_ "GenSigTimeoutTime_HU_B" SG_ 1068 ICDrvModeFunVariant 5000;
BA_ "GenSigTimeoutTime_HU_A" SG_ 1068 ICDrvModeFunVariant 5000;
BA_ "GenSigTimeoutMsg_HU_Mid_X451" SG_ 1068 ICDrvModeFunVariant 5000;
BA_ "GenSigTimeoutMsg_HU_High_X451" SG_ 1068 ICDrvModeFunVariant 5000;
BA_ "GenSigTimeoutMsg_HU_B" SG_ 1068 ICDrvModeFunVariant 5000;
BA_ "GenSigTimeoutMsg_HU_A" SG_ 1068 ICDrvModeFunVariant 5000;
BA_ "GenSigSendType" SG_ 1068 ICDrvModeFunVariant 7;
BA_ "GenSigCycleTimeActive" SG_ 1068 ICDrvModeFunVariant 1000;
BA_ "GenSigCycleTime" SG_ 1068 ICDrvModeFunVariant 1000;
BA_ "GenSigTimeoutMsg_HU_High_X445" SG_ 1068 ICDrvModeFunVariant 5000;
BA_ "GenSigTimeoutMsg_HU_Mid_X445" SG_ 1068 ICDrvModeFunVariant 5000;
BA_ "GenSigTimeoutTime_HU_High_X445" SG_ 1068 ICDrvModeFunVariant 5000;
BA_ "GenSigTimeoutTime_HU_Mid_X445" SG_ 1068 ICDrvModeFunVariant 5000;
BA_ "GenSigTimeoutMsg_IVI" SG_ 1068 ICDrvModeFunVariant 5000;
BA_ "GenSigTimeoutTime_IVI" SG_ 1068 ICDrvModeFunVariant 5000;
BA_ "GenSigTimeoutTime_HU_Mid_X451" SG_ 1069 IcHuVcInfonew 5000;
BA_ "GenSigTimeoutTime_HU_High_X451" SG_ 1069 IcHuVcInfonew 5000;
BA_ "GenSigTimeoutTime_HU_B" SG_ 1069 IcHuVcInfonew 5000;
BA_ "GenSigTimeoutTime_HU_A" SG_ 1069 IcHuVcInfonew 5000;
BA_ "GenSigTimeoutMsg_HU_Mid_X451" SG_ 1069 IcHuVcInfonew 5000;
BA_ "GenSigTimeoutMsg_HU_High_X451" SG_ 1069 IcHuVcInfonew 5000;
BA_ "GenSigTimeoutMsg_HU_B" SG_ 1069 IcHuVcInfonew 5000;
BA_ "GenSigTimeoutMsg_HU_A" SG_ 1069 IcHuVcInfonew 5000;
BA_ "GenSigSendType" SG_ 1069 IcHuVcInfonew 7;
BA_ "GenSigCycleTimeActive" SG_ 1069 IcHuVcInfonew 1000;
BA_ "GenSigCycleTime" SG_ 1069 IcHuVcInfonew 1000;
BA_ "GenSigTimeoutMsg_HU_High_X445" SG_ 1069 IcHuVcInfonew 5000;
BA_ "GenSigTimeoutMsg_HU_Mid_X445" SG_ 1069 IcHuVcInfonew 5000;
BA_ "GenSigTimeoutTime_HU_High_X445" SG_ 1069 IcHuVcInfonew 5000;
BA_ "GenSigTimeoutTime_HU_Mid_X445" SG_ 1069 IcHuVcInfonew 5000;
BA_ "GenSigTimeoutMsg_IVI" SG_ 1069 IcHuVcInfonew 5000;
BA_ "GenSigTimeoutTime_IVI" SG_ 1069 IcHuVcInfonew 5000;
BA_ "GenSigTimeoutTime_HU_B" SG_ 1104 BattVolt_DCS 0;
BA_ "GenSigTimeoutTime_HU_A" SG_ 1104 BattVolt_DCS 0;
BA_ "GenSigTimeoutMsg_HU_B" SG_ 1104 BattVolt_DCS 0;
BA_ "GenSigTimeoutMsg_HU_A" SG_ 1104 BattVolt_DCS 0;
BA_ "GenSigSendType" SG_ 1104 BattVolt_DCS 7;
BA_ "GenSigCycleTimeActive" SG_ 1104 BattVolt_DCS 100;
BA_ "GenSigCycleTime" SG_ 1104 BattVolt_DCS 100;
BA_ "GenSigTimeoutTime_HU_B" SG_ 1104 DCS_Err_State_Trans_Cntr 0;
BA_ "GenSigTimeoutTime_HU_A" SG_ 1104 DCS_Err_State_Trans_Cntr 0;
BA_ "GenSigTimeoutMsg_HU_B" SG_ 1104 DCS_Err_State_Trans_Cntr 0;
BA_ "GenSigTimeoutMsg_HU_A" SG_ 1104 DCS_Err_State_Trans_Cntr 0;
BA_ "GenSigSendType" SG_ 1104 DCS_Err_State_Trans_Cntr 7;
BA_ "GenSigCycleTimeActive" SG_ 1104 DCS_Err_State_Trans_Cntr 100;
BA_ "GenSigCycleTime" SG_ 1104 DCS_Err_State_Trans_Cntr 100;
BA_ "GenSigTimeoutTime_HU_B" SG_ 1104 DCS_HW_Ver 0;
BA_ "GenSigTimeoutTime_HU_A" SG_ 1104 DCS_HW_Ver 0;
BA_ "GenSigTimeoutMsg_HU_B" SG_ 1104 DCS_HW_Ver 0;
BA_ "GenSigTimeoutMsg_HU_A" SG_ 1104 DCS_HW_Ver 0;
BA_ "GenSigSendType" SG_ 1104 DCS_HW_Ver 7;
BA_ "GenSigCycleTimeActive" SG_ 1104 DCS_HW_Ver 100;
BA_ "GenSigCycleTime" SG_ 1104 DCS_HW_Ver 100;
BA_ "GenSigTimeoutTime_HU_B" SG_ 1104 DCS_SW_Ver 0;
BA_ "GenSigTimeoutTime_HU_A" SG_ 1104 DCS_SW_Ver 0;
BA_ "GenSigTimeoutMsg_HU_B" SG_ 1104 DCS_SW_Ver 0;
BA_ "GenSigTimeoutMsg_HU_A" SG_ 1104 DCS_SW_Ver 0;
BA_ "GenSigSendType" SG_ 1104 DCS_SW_Ver 7;
BA_ "GenSigCycleTimeActive" SG_ 1104 DCS_SW_Ver 100;
BA_ "GenSigCycleTime" SG_ 1104 DCS_SW_Ver 100;
BA_ "GenSigTimeoutTime_HU_B" SG_ 1104 BCM_MTO_Failure_status 0;
BA_ "GenSigTimeoutTime_HU_A" SG_ 1104 BCM_MTO_Failure_status 0;
BA_ "GenSigTimeoutMsg_HU_B" SG_ 1104 BCM_MTO_Failure_status 0;
BA_ "GenSigTimeoutMsg_HU_A" SG_ 1104 BCM_MTO_Failure_status 0;
BA_ "GenSigSendType" SG_ 1104 BCM_MTO_Failure_status 7;
BA_ "GenSigCycleTimeActive" SG_ 1104 BCM_MTO_Failure_status 100;
BA_ "GenSigCycleTime" SG_ 1104 BCM_MTO_Failure_status 100;
BA_ "GenSigTimeoutTime_HU_B" SG_ 1104 EMS_MTO_Failure_Status 0;
BA_ "GenSigTimeoutTime_HU_A" SG_ 1104 EMS_MTO_Failure_Status 0;
BA_ "GenSigTimeoutMsg_HU_B" SG_ 1104 EMS_MTO_Failure_Status 0;
BA_ "GenSigTimeoutMsg_HU_A" SG_ 1104 EMS_MTO_Failure_Status 0;
BA_ "GenSigSendType" SG_ 1104 EMS_MTO_Failure_Status 7;
BA_ "GenSigCycleTimeActive" SG_ 1104 EMS_MTO_Failure_Status 100;
BA_ "GenSigCycleTime" SG_ 1104 EMS_MTO_Failure_Status 100;
BA_ "GenSigTimeoutTime_HU_B" SG_ 1104 ESP_MTO_Failure_Status 0;
BA_ "GenSigTimeoutTime_HU_A" SG_ 1104 ESP_MTO_Failure_Status 0;
BA_ "GenSigTimeoutMsg_HU_B" SG_ 1104 ESP_MTO_Failure_Status 0;
BA_ "GenSigTimeoutMsg_HU_A" SG_ 1104 ESP_MTO_Failure_Status 0;
BA_ "GenSigSendType" SG_ 1104 ESP_MTO_Failure_Status 7;
BA_ "GenSigCycleTimeActive" SG_ 1104 ESP_MTO_Failure_Status 100;
BA_ "GenSigCycleTime" SG_ 1104 ESP_MTO_Failure_Status 100;
BA_ "GenSigTimeoutTime_HU_B" SG_ 1104 DCS_BO_Failure_Status 0;
BA_ "GenSigTimeoutTime_HU_A" SG_ 1104 DCS_BO_Failure_Status 0;
BA_ "GenSigTimeoutMsg_HU_B" SG_ 1104 DCS_BO_Failure_Status 0;
BA_ "GenSigTimeoutMsg_HU_A" SG_ 1104 DCS_BO_Failure_Status 0;
BA_ "GenSigSendType" SG_ 1104 DCS_BO_Failure_Status 7;
BA_ "GenSigCycleTimeActive" SG_ 1104 DCS_BO_Failure_Status 100;
BA_ "GenSigCycleTime" SG_ 1104 DCS_BO_Failure_Status 100;
BA_ "GenSigTimeoutTime_HU_B" SG_ 1104 IPcMToFailureStatus 0;
BA_ "GenSigTimeoutTime_HU_A" SG_ 1104 IPcMToFailureStatus 0;
BA_ "GenSigTimeoutMsg_HU_B" SG_ 1104 IPcMToFailureStatus 0;
BA_ "GenSigTimeoutMsg_HU_A" SG_ 1104 IPcMToFailureStatus 0;
BA_ "GenSigSendType" SG_ 1104 IPcMToFailureStatus 7;
BA_ "GenSigCycleTimeActive" SG_ 1104 IPcMToFailureStatus 100;
BA_ "GenSigCycleTime" SG_ 1104 IPcMToFailureStatus 100;
BA_ "GenSigTimeoutTime_HU_B" SG_ 1104 EMsInvalidFailureStatus 0;
BA_ "GenSigTimeoutTime_HU_A" SG_ 1104 EMsInvalidFailureStatus 0;
BA_ "GenSigTimeoutMsg_HU_B" SG_ 1104 EMsInvalidFailureStatus 0;
BA_ "GenSigTimeoutMsg_HU_A" SG_ 1104 EMsInvalidFailureStatus 0;
BA_ "GenSigSendType" SG_ 1104 EMsInvalidFailureStatus 7;
BA_ "GenSigCycleTimeActive" SG_ 1104 EMsInvalidFailureStatus 100;
BA_ "GenSigCycleTime" SG_ 1104 EMsInvalidFailureStatus 100;
BA_ "GenSigTimeoutTime_HU_B" SG_ 1104 ESpInvalidFailureStatus 0;
BA_ "GenSigTimeoutTime_HU_A" SG_ 1104 ESpInvalidFailureStatus 0;
BA_ "GenSigTimeoutMsg_HU_B" SG_ 1104 ESpInvalidFailureStatus 0;
BA_ "GenSigTimeoutMsg_HU_A" SG_ 1104 ESpInvalidFailureStatus 0;
BA_ "GenSigSendType" SG_ 1104 ESpInvalidFailureStatus 7;
BA_ "GenSigCycleTimeActive" SG_ 1104 ESpInvalidFailureStatus 100;
BA_ "GenSigCycleTime" SG_ 1104 ESpInvalidFailureStatus 100;
BA_ "GenSigTimeoutTime_HU_B" SG_ 1104 BCM_Invalid_Status_Failure 0;
BA_ "GenSigTimeoutTime_HU_A" SG_ 1104 BCM_Invalid_Status_Failure 0;
BA_ "GenSigTimeoutMsg_HU_B" SG_ 1104 BCM_Invalid_Status_Failure 0;
BA_ "GenSigTimeoutMsg_HU_A" SG_ 1104 BCM_Invalid_Status_Failure 0;
BA_ "GenSigSendType" SG_ 1104 BCM_Invalid_Status_Failure 7;
BA_ "GenSigCycleTimeActive" SG_ 1104 BCM_Invalid_Status_Failure 100;
BA_ "GenSigCycleTime" SG_ 1104 BCM_Invalid_Status_Failure 100;
BA_ "GenSigTimeoutTime_HU_B" SG_ 1104 DCS_EP_Failure_Status 0;
BA_ "GenSigTimeoutTime_HU_A" SG_ 1104 DCS_EP_Failure_Status 0;
BA_ "GenSigTimeoutMsg_HU_B" SG_ 1104 DCS_EP_Failure_Status 0;
BA_ "GenSigTimeoutMsg_HU_A" SG_ 1104 DCS_EP_Failure_Status 0;
BA_ "GenSigSendType" SG_ 1104 DCS_EP_Failure_Status 7;
BA_ "GenSigCycleTimeActive" SG_ 1104 DCS_EP_Failure_Status 100;
BA_ "GenSigCycleTime" SG_ 1104 DCS_EP_Failure_Status 100;
BA_ "GenSigTimeoutTime_HU_Mid_X451" SG_ 1120 HuIcTpSig 0;
BA_ "GenSigTimeoutTime_HU_High_X451" SG_ 1120 HuIcTpSig 0;
BA_ "GenSigTimeoutTime_HU_B" SG_ 1120 HuIcTpSig 0;
BA_ "GenSigTimeoutTime_HU_A" SG_ 1120 HuIcTpSig 0;
BA_ "GenSigTimeoutMsg_HU_Mid_X451" SG_ 1120 HuIcTpSig 0;
BA_ "GenSigTimeoutMsg_HU_High_X451" SG_ 1120 HuIcTpSig 0;
BA_ "GenSigTimeoutMsg_HU_B" SG_ 1120 HuIcTpSig 0;
BA_ "GenSigTimeoutMsg_HU_A" SG_ 1120 HuIcTpSig 0;
BA_ "GenSigSendType" SG_ 1120 HuIcTpSig 1;
BA_ "GenSigTimeoutMsg_HU_High_X445" SG_ 1120 HuIcTpSig 0;
BA_ "GenSigTimeoutMsg_HU_Mid_X445" SG_ 1120 HuIcTpSig 0;
BA_ "GenSigTimeoutTime_HU_High_X445" SG_ 1120 HuIcTpSig 0;
BA_ "GenSigTimeoutTime_HU_Mid_X445" SG_ 1120 HuIcTpSig 0;
BA_ "GenSigTimeoutMsg_IVI" SG_ 1120 HuIcTpSig 0;
BA_ "GenSigTimeoutTime_IVI" SG_ 1120 HuIcTpSig 0;
BA_ "GenSigTimeoutTime_HU_Mid_X451" SG_ 1121 IcHuTpSig 0;
BA_ "GenSigTimeoutTime_HU_High_X451" SG_ 1121 IcHuTpSig 0;
BA_ "GenSigTimeoutTime_HU_B" SG_ 1121 IcHuTpSig 0;
BA_ "GenSigTimeoutTime_HU_A" SG_ 1121 IcHuTpSig 0;
BA_ "GenSigTimeoutMsg_HU_Mid_X451" SG_ 1121 IcHuTpSig 0;
BA_ "GenSigTimeoutMsg_HU_High_X451" SG_ 1121 IcHuTpSig 0;
BA_ "GenSigTimeoutMsg_HU_B" SG_ 1121 IcHuTpSig 0;
BA_ "GenSigTimeoutMsg_HU_A" SG_ 1121 IcHuTpSig 0;
BA_ "GenSigSendType" SG_ 1121 IcHuTpSig 1;
BA_ "GenSigTimeoutMsg_HU_High_X445" SG_ 1121 IcHuTpSig 0;
BA_ "GenSigTimeoutMsg_HU_Mid_X445" SG_ 1121 IcHuTpSig 0;
BA_ "GenSigTimeoutTime_HU_High_X445" SG_ 1121 IcHuTpSig 0;
BA_ "GenSigTimeoutTime_HU_Mid_X445" SG_ 1121 IcHuTpSig 0;
BA_ "GenSigTimeoutMsg_IVI" SG_ 1121 IcHuTpSig 0;
BA_ "GenSigTimeoutTime_IVI" SG_ 1121 IcHuTpSig 0;
BA_ "GenSigTimeoutTime_HU_B" SG_ 1136 AuthMechKeyStatus 0;
BA_ "GenSigTimeoutTime_HU_A" SG_ 1136 AuthMechKeyStatus 0;
BA_ "GenSigTimeoutMsg_HU_B" SG_ 1136 AuthMechKeyStatus 0;
BA_ "GenSigTimeoutMsg_HU_A" SG_ 1136 AuthMechKeyStatus 0;
BA_ "GenSigSendType" SG_ 1136 AuthMechKeyStatus 7;
BA_ "GenSigCycleTimeActive" SG_ 1136 AuthMechKeyStatus 100;
BA_ "GenSigCycleTime" SG_ 1136 AuthMechKeyStatus 100;
BA_ "GenSigTimeoutTime_HU_B" SG_ 1136 AuthMechKey 0;
BA_ "GenSigTimeoutTime_HU_A" SG_ 1136 AuthMechKey 0;
BA_ "GenSigTimeoutMsg_HU_B" SG_ 1136 AuthMechKey 0;
BA_ "GenSigTimeoutMsg_HU_A" SG_ 1136 AuthMechKey 0;
BA_ "GenSigSendType" SG_ 1136 AuthMechKey 7;
BA_ "GenSigCycleTimeActive" SG_ 1136 AuthMechKey 100;
BA_ "GenSigCycleTime" SG_ 1136 AuthMechKey 100;
BA_ "GenSigTimeoutTime_HU_B" SG_ 1136 PEPSPeriodicSig1 0;
BA_ "GenSigTimeoutTime_HU_A" SG_ 1136 PEPSPeriodicSig1 0;
BA_ "GenSigTimeoutMsg_HU_B" SG_ 1136 PEPSPeriodicSig1 0;
BA_ "GenSigTimeoutMsg_HU_A" SG_ 1136 PEPSPeriodicSig1 0;
BA_ "GenSigSendType" SG_ 1136 PEPSPeriodicSig1 7;
BA_ "GenSigCycleTimeActive" SG_ 1136 PEPSPeriodicSig1 100;
BA_ "GenSigCycleTime" SG_ 1136 PEPSPeriodicSig1 100;
BA_ "GenSigTimeoutTime_HU_B" SG_ 1136 PEPSPeriodicSig2 0;
BA_ "GenSigTimeoutTime_HU_A" SG_ 1136 PEPSPeriodicSig2 0;
BA_ "GenSigTimeoutMsg_HU_B" SG_ 1136 PEPSPeriodicSig2 0;
BA_ "GenSigTimeoutMsg_HU_A" SG_ 1136 PEPSPeriodicSig2 0;
BA_ "GenSigSendType" SG_ 1136 PEPSPeriodicSig2 7;
BA_ "GenSigCycleTimeActive" SG_ 1136 PEPSPeriodicSig2 100;
BA_ "GenSigCycleTime" SG_ 1136 PEPSPeriodicSig2 100;
BA_ "GenSigTimeoutTime_HU_B" SG_ 1136 PEPSPeriodicSig3 0;
BA_ "GenSigTimeoutTime_HU_A" SG_ 1136 PEPSPeriodicSig3 0;
BA_ "GenSigTimeoutMsg_HU_B" SG_ 1136 PEPSPeriodicSig3 0;
BA_ "GenSigTimeoutMsg_HU_A" SG_ 1136 PEPSPeriodicSig3 0;
BA_ "GenSigSendType" SG_ 1136 PEPSPeriodicSig3 7;
BA_ "GenSigCycleTimeActive" SG_ 1136 PEPSPeriodicSig3 100;
BA_ "GenSigCycleTime" SG_ 1136 PEPSPeriodicSig3 100;
BA_ "GenSigTimeoutTime_HU_B" SG_ 1136 PEPSPeriodicSig4 0;
BA_ "GenSigTimeoutTime_HU_A" SG_ 1136 PEPSPeriodicSig4 0;
BA_ "GenSigTimeoutMsg_HU_B" SG_ 1136 PEPSPeriodicSig4 0;
BA_ "GenSigTimeoutMsg_HU_A" SG_ 1136 PEPSPeriodicSig4 0;
BA_ "GenSigSendType" SG_ 1136 PEPSPeriodicSig4 7;
BA_ "GenSigCycleTimeActive" SG_ 1136 PEPSPeriodicSig4 100;
BA_ "GenSigCycleTime" SG_ 1136 PEPSPeriodicSig4 100;
BA_ "GenSigTimeoutTime_HU_B" SG_ 1136 PEPSPeriodicSig5 0;
BA_ "GenSigTimeoutTime_HU_A" SG_ 1136 PEPSPeriodicSig5 0;
BA_ "GenSigTimeoutMsg_HU_B" SG_ 1136 PEPSPeriodicSig5 0;
BA_ "GenSigTimeoutMsg_HU_A" SG_ 1136 PEPSPeriodicSig5 0;
BA_ "GenSigSendType" SG_ 1136 PEPSPeriodicSig5 7;
BA_ "GenSigCycleTimeActive" SG_ 1136 PEPSPeriodicSig5 100;
BA_ "GenSigCycleTime" SG_ 1136 PEPSPeriodicSig5 100;
BA_ "GenSigTimeoutTime_HU_B" SG_ 1136 PEPSPeriodicSig6 0;
BA_ "GenSigTimeoutTime_HU_A" SG_ 1136 PEPSPeriodicSig6 0;
BA_ "GenSigTimeoutMsg_HU_B" SG_ 1136 PEPSPeriodicSig6 0;
BA_ "GenSigTimeoutMsg_HU_A" SG_ 1136 PEPSPeriodicSig6 0;
BA_ "GenSigSendType" SG_ 1136 PEPSPeriodicSig6 7;
BA_ "GenSigCycleTimeActive" SG_ 1136 PEPSPeriodicSig6 100;
BA_ "GenSigCycleTime" SG_ 1136 PEPSPeriodicSig6 100;
BA_ "GenSigTimeoutTime_HU_B" SG_ 1136 PEPSPeriodicSig7 0;
BA_ "GenSigTimeoutTime_HU_A" SG_ 1136 PEPSPeriodicSig7 0;
BA_ "GenSigTimeoutMsg_HU_B" SG_ 1136 PEPSPeriodicSig7 0;
BA_ "GenSigTimeoutMsg_HU_A" SG_ 1136 PEPSPeriodicSig7 0;
BA_ "GenSigSendType" SG_ 1136 PEPSPeriodicSig7 7;
BA_ "GenSigCycleTimeActive" SG_ 1136 PEPSPeriodicSig7 100;
BA_ "GenSigCycleTime" SG_ 1136 PEPSPeriodicSig7 100;
BA_ "GenSigSendType" SG_ 1140 Telematics_MTO_Failure_Status 7;
BA_ "GenSigCycleTimeActive" SG_ 1140 Telematics_MTO_Failure_Status 100;
BA_ "GenSigCycleTime" SG_ 1140 Telematics_MTO_Failure_Status 100;
BA_ "GenSigSendType" SG_ 1140 Telematics_Invalid_Failure__0000 7;
BA_ "GenSigCycleTimeActive" SG_ 1140 Telematics_Invalid_Failure__0000 100;
BA_ "GenSigCycleTime" SG_ 1140 Telematics_Invalid_Failure__0000 100;
BA_ "SystemSignalLongSymbol" SG_ 1140 Telematics_Invalid_Failure__0000 "Telematics_Invalid_Failure_Status";
BA_ "GenSigTimeoutTime_HU_B" SG_ 1140 HU_MTO_Failure_Status 0;
BA_ "GenSigTimeoutTime_HU_A" SG_ 1140 HU_MTO_Failure_Status 0;
BA_ "GenSigTimeoutMsg_HU_B" SG_ 1140 HU_MTO_Failure_Status 0;
BA_ "GenSigTimeoutMsg_HU_A" SG_ 1140 HU_MTO_Failure_Status 0;
BA_ "GenSigSendType" SG_ 1140 HU_MTO_Failure_Status 7;
BA_ "GenSigCycleTimeActive" SG_ 1140 HU_MTO_Failure_Status 100;
BA_ "GenSigCycleTime" SG_ 1140 HU_MTO_Failure_Status 100;
BA_ "GenSigTimeoutTime_HU_B" SG_ 1140 HU_Invalid_Failure_Status 0;
BA_ "GenSigTimeoutTime_HU_A" SG_ 1140 HU_Invalid_Failure_Status 0;
BA_ "GenSigTimeoutMsg_HU_B" SG_ 1140 HU_Invalid_Failure_Status 0;
BA_ "GenSigTimeoutMsg_HU_A" SG_ 1140 HU_Invalid_Failure_Status 0;
BA_ "GenSigSendType" SG_ 1140 HU_Invalid_Failure_Status 7;
BA_ "GenSigCycleTimeActive" SG_ 1140 HU_Invalid_Failure_Status 100;
BA_ "GenSigCycleTime" SG_ 1140 HU_Invalid_Failure_Status 100;
BA_ "GenSigTimeoutTime_HU_Mid_X451" SG_ 1140 CCM_Invalid_Failure_Status 0;
BA_ "GenSigTimeoutTime_HU_High_X451" SG_ 1140 CCM_Invalid_Failure_Status 0;
BA_ "GenSigTimeoutTime_HU_B" SG_ 1140 CCM_Invalid_Failure_Status 0;
BA_ "GenSigTimeoutTime_HU_A" SG_ 1140 CCM_Invalid_Failure_Status 0;
BA_ "GenSigTimeoutMsg_HU_Mid_X451" SG_ 1140 CCM_Invalid_Failure_Status 0;
BA_ "GenSigTimeoutMsg_HU_High_X451" SG_ 1140 CCM_Invalid_Failure_Status 0;
BA_ "GenSigTimeoutMsg_HU_B" SG_ 1140 CCM_Invalid_Failure_Status 0;
BA_ "GenSigTimeoutMsg_HU_A" SG_ 1140 CCM_Invalid_Failure_Status 0;
BA_ "GenSigSendType" SG_ 1140 CCM_Invalid_Failure_Status 7;
BA_ "GenSigCycleTimeActive" SG_ 1140 CCM_Invalid_Failure_Status 100;
BA_ "GenSigCycleTime" SG_ 1140 CCM_Invalid_Failure_Status 100;
BA_ "GenSigTimeoutTime_HU_B" SG_ 1140 EMS_SW_Version 0;
BA_ "GenSigTimeoutTime_HU_A" SG_ 1140 EMS_SW_Version 0;
BA_ "GenSigTimeoutMsg_HU_B" SG_ 1140 EMS_SW_Version 0;
BA_ "GenSigTimeoutMsg_HU_A" SG_ 1140 EMS_SW_Version 0;
BA_ "GenSigSendType" SG_ 1140 EMS_SW_Version 7;
BA_ "GenSigCycleTimeActive" SG_ 1140 EMS_SW_Version 100;
BA_ "GenSigCycleTime" SG_ 1140 EMS_SW_Version 100;
BA_ "GenSigTimeoutTime_HU_B" SG_ 1140 AT_AMT_DCT_MTO_Failure_Status 0;
BA_ "GenSigTimeoutTime_HU_A" SG_ 1140 AT_AMT_DCT_MTO_Failure_Status 0;
BA_ "GenSigTimeoutMsg_HU_B" SG_ 1140 AT_AMT_DCT_MTO_Failure_Status 0;
BA_ "GenSigTimeoutMsg_HU_A" SG_ 1140 AT_AMT_DCT_MTO_Failure_Status 0;
BA_ "GenSigSendType" SG_ 1140 AT_AMT_DCT_MTO_Failure_Status 7;
BA_ "GenSigCycleTimeActive" SG_ 1140 AT_AMT_DCT_MTO_Failure_Status 100;
BA_ "GenSigCycleTime" SG_ 1140 AT_AMT_DCT_MTO_Failure_Status 100;
BA_ "GenSigTimeoutTime_HU_B" SG_ 1140 EPAS_Invalid_Failure_Status 0;
BA_ "GenSigTimeoutTime_HU_A" SG_ 1140 EPAS_Invalid_Failure_Status 0;
BA_ "GenSigTimeoutMsg_HU_B" SG_ 1140 EPAS_Invalid_Failure_Status 0;
BA_ "GenSigTimeoutMsg_HU_A" SG_ 1140 EPAS_Invalid_Failure_Status 0;
BA_ "GenSigSendType" SG_ 1140 EPAS_Invalid_Failure_Status 7;
BA_ "GenSigCycleTimeActive" SG_ 1140 EPAS_Invalid_Failure_Status 100;
BA_ "GenSigCycleTime" SG_ 1140 EPAS_Invalid_Failure_Status 100;
BA_ "GenSigTimeoutTime_HU_B" SG_ 1140 BCmMToFailureStatus 0;
BA_ "GenSigTimeoutTime_HU_A" SG_ 1140 BCmMToFailureStatus 0;
BA_ "GenSigTimeoutMsg_HU_B" SG_ 1140 BCmMToFailureStatus 0;
BA_ "GenSigTimeoutMsg_HU_A" SG_ 1140 BCmMToFailureStatus 0;
BA_ "GenSigSendType" SG_ 1140 BCmMToFailureStatus 7;
BA_ "GenSigCycleTimeActive" SG_ 1140 BCmMToFailureStatus 100;
BA_ "GenSigCycleTime" SG_ 1140 BCmMToFailureStatus 100;
BA_ "GenSigTimeoutTime_HU_B" SG_ 1140 EPAS_MTO_Failure_Status 0;
BA_ "GenSigTimeoutTime_HU_A" SG_ 1140 EPAS_MTO_Failure_Status 0;
BA_ "GenSigTimeoutMsg_HU_B" SG_ 1140 EPAS_MTO_Failure_Status 0;
BA_ "GenSigTimeoutMsg_HU_A" SG_ 1140 EPAS_MTO_Failure_Status 0;
BA_ "GenSigSendType" SG_ 1140 EPAS_MTO_Failure_Status 7;
BA_ "GenSigCycleTimeActive" SG_ 1140 EPAS_MTO_Failure_Status 100;
BA_ "GenSigCycleTime" SG_ 1140 EPAS_MTO_Failure_Status 100;
BA_ "GenSigTimeoutTime_HU_B" SG_ 1140 EMS_BO_Failure_Status 0;
BA_ "GenSigTimeoutTime_HU_A" SG_ 1140 EMS_BO_Failure_Status 0;
BA_ "GenSigTimeoutMsg_HU_B" SG_ 1140 EMS_BO_Failure_Status 0;
BA_ "GenSigTimeoutMsg_HU_A" SG_ 1140 EMS_BO_Failure_Status 0;
BA_ "GenSigSendType" SG_ 1140 EMS_BO_Failure_Status 7;
BA_ "GenSigCycleTimeActive" SG_ 1140 EMS_BO_Failure_Status 100;
BA_ "GenSigCycleTime" SG_ 1140 EMS_BO_Failure_Status 100;
BA_ "GenSigTimeoutTime_HU_B" SG_ 1140 EMS_EP_Failure_Status 0;
BA_ "GenSigTimeoutTime_HU_A" SG_ 1140 EMS_EP_Failure_Status 0;
BA_ "GenSigTimeoutMsg_HU_B" SG_ 1140 EMS_EP_Failure_Status 0;
BA_ "GenSigTimeoutMsg_HU_A" SG_ 1140 EMS_EP_Failure_Status 0;
BA_ "GenSigSendType" SG_ 1140 EMS_EP_Failure_Status 7;
BA_ "GenSigCycleTimeActive" SG_ 1140 EMS_EP_Failure_Status 100;
BA_ "GenSigCycleTime" SG_ 1140 EMS_EP_Failure_Status 100;
BA_ "GenSigTimeoutTime_HU_B" SG_ 1140 ABS_ESP_MTO_Failure_Status 0;
BA_ "GenSigTimeoutTime_HU_A" SG_ 1140 ABS_ESP_MTO_Failure_Status 0;
BA_ "GenSigTimeoutMsg_HU_B" SG_ 1140 ABS_ESP_MTO_Failure_Status 0;
BA_ "GenSigTimeoutMsg_HU_A" SG_ 1140 ABS_ESP_MTO_Failure_Status 0;
BA_ "GenSigSendType" SG_ 1140 ABS_ESP_MTO_Failure_Status 7;
BA_ "GenSigCycleTimeActive" SG_ 1140 ABS_ESP_MTO_Failure_Status 100;
BA_ "GenSigCycleTime" SG_ 1140 ABS_ESP_MTO_Failure_Status 100;
BA_ "GenSigTimeoutTime_HU_B" SG_ 1140 PEPS_MTO_Failure_Status 0;
BA_ "GenSigTimeoutTime_HU_A" SG_ 1140 PEPS_MTO_Failure_Status 0;
BA_ "GenSigTimeoutMsg_HU_B" SG_ 1140 PEPS_MTO_Failure_Status 0;
BA_ "GenSigTimeoutMsg_HU_A" SG_ 1140 PEPS_MTO_Failure_Status 0;
BA_ "GenSigSendType" SG_ 1140 PEPS_MTO_Failure_Status 7;
BA_ "GenSigCycleTimeActive" SG_ 1140 PEPS_MTO_Failure_Status 100;
BA_ "GenSigCycleTime" SG_ 1140 PEPS_MTO_Failure_Status 100;
BA_ "GenSigTimeoutTime_HU_B" SG_ 1140 AT_AMT_DCT_Invalid_Failure_Statu 0;
BA_ "GenSigTimeoutTime_HU_A" SG_ 1140 AT_AMT_DCT_Invalid_Failure_Statu 0;
BA_ "GenSigTimeoutMsg_HU_B" SG_ 1140 AT_AMT_DCT_Invalid_Failure_Statu 0;
BA_ "GenSigTimeoutMsg_HU_A" SG_ 1140 AT_AMT_DCT_Invalid_Failure_Statu 0;
BA_ "GenSigSendType" SG_ 1140 AT_AMT_DCT_Invalid_Failure_Statu 7;
BA_ "GenSigCycleTimeActive" SG_ 1140 AT_AMT_DCT_Invalid_Failure_Statu 100;
BA_ "GenSigCycleTime" SG_ 1140 AT_AMT_DCT_Invalid_Failure_Statu 100;
BA_ "SystemSignalLongSymbol" SG_ 1140 AT_AMT_DCT_Invalid_Failure_Statu "AT_AMT_DCT_Invalid_Failure_Status";
BA_ "GenSigTimeoutTime_HU_B" SG_ 1140 ABS_ESP_Invalid_Failure_Status 0;
BA_ "GenSigTimeoutTime_HU_A" SG_ 1140 ABS_ESP_Invalid_Failure_Status 0;
BA_ "GenSigTimeoutMsg_HU_B" SG_ 1140 ABS_ESP_Invalid_Failure_Status 0;
BA_ "GenSigTimeoutMsg_HU_A" SG_ 1140 ABS_ESP_Invalid_Failure_Status 0;
BA_ "GenSigSendType" SG_ 1140 ABS_ESP_Invalid_Failure_Status 7;
BA_ "GenSigCycleTimeActive" SG_ 1140 ABS_ESP_Invalid_Failure_Status 100;
BA_ "GenSigCycleTime" SG_ 1140 ABS_ESP_Invalid_Failure_Status 100;
BA_ "GenSigTimeoutTime_HU_B" SG_ 1140 IPcInvalidFailureStatus 0;
BA_ "GenSigTimeoutTime_HU_A" SG_ 1140 IPcInvalidFailureStatus 0;
BA_ "GenSigTimeoutMsg_HU_B" SG_ 1140 IPcInvalidFailureStatus 0;
BA_ "GenSigTimeoutMsg_HU_A" SG_ 1140 IPcInvalidFailureStatus 0;
BA_ "GenSigSendType" SG_ 1140 IPcInvalidFailureStatus 7;
BA_ "GenSigCycleTimeActive" SG_ 1140 IPcInvalidFailureStatus 100;
BA_ "GenSigCycleTime" SG_ 1140 IPcInvalidFailureStatus 100;
BA_ "GenSigTimeoutTime_HU_B" SG_ 1140 BCmInvalidFailureStatus 0;
BA_ "GenSigTimeoutTime_HU_A" SG_ 1140 BCmInvalidFailureStatus 0;
BA_ "GenSigTimeoutMsg_HU_B" SG_ 1140 BCmInvalidFailureStatus 0;
BA_ "GenSigTimeoutMsg_HU_A" SG_ 1140 BCmInvalidFailureStatus 0;
BA_ "GenSigSendType" SG_ 1140 BCmInvalidFailureStatus 7;
BA_ "GenSigCycleTimeActive" SG_ 1140 BCmInvalidFailureStatus 100;
BA_ "GenSigCycleTime" SG_ 1140 BCmInvalidFailureStatus 100;
BA_ "GenSigTimeoutTime_HU_B" SG_ 1140 IPcMToFailureStatus 0;
BA_ "GenSigTimeoutTime_HU_A" SG_ 1140 IPcMToFailureStatus 0;
BA_ "GenSigTimeoutMsg_HU_B" SG_ 1140 IPcMToFailureStatus 0;
BA_ "GenSigTimeoutMsg_HU_A" SG_ 1140 IPcMToFailureStatus 0;
BA_ "GenSigSendType" SG_ 1140 IPcMToFailureStatus 7;
BA_ "GenSigCycleTimeActive" SG_ 1140 IPcMToFailureStatus 100;
BA_ "GenSigCycleTime" SG_ 1140 IPcMToFailureStatus 100;
BA_ "GenSigTimeoutTime_HU_B" SG_ 1140 CCM_MTO_Failure_Status 0;
BA_ "GenSigTimeoutTime_HU_A" SG_ 1140 CCM_MTO_Failure_Status 0;
BA_ "GenSigTimeoutMsg_HU_B" SG_ 1140 CCM_MTO_Failure_Status 0;
BA_ "GenSigTimeoutMsg_HU_A" SG_ 1140 CCM_MTO_Failure_Status 0;
BA_ "GenSigSendType" SG_ 1140 CCM_MTO_Failure_Status 7;
BA_ "GenSigCycleTimeActive" SG_ 1140 CCM_MTO_Failure_Status 100;
BA_ "GenSigCycleTime" SG_ 1140 CCM_MTO_Failure_Status 100;
BA_ "GenSigTimeoutTime_HU_B" SG_ 1140 DCS_Invalid_Failure_Status 0;
BA_ "GenSigTimeoutTime_HU_A" SG_ 1140 DCS_Invalid_Failure_Status 0;
BA_ "GenSigTimeoutMsg_HU_B" SG_ 1140 DCS_Invalid_Failure_Status 0;
BA_ "GenSigTimeoutMsg_HU_A" SG_ 1140 DCS_Invalid_Failure_Status 0;
BA_ "GenSigSendType" SG_ 1140 DCS_Invalid_Failure_Status 7;
BA_ "GenSigCycleTimeActive" SG_ 1140 DCS_Invalid_Failure_Status 100;
BA_ "GenSigCycleTime" SG_ 1140 DCS_Invalid_Failure_Status 100;
BA_ "GenSigTimeoutTime_HU_B" SG_ 1140 DCS_MTO_Failure_Status 0;
BA_ "GenSigTimeoutTime_HU_A" SG_ 1140 DCS_MTO_Failure_Status 0;
BA_ "GenSigTimeoutMsg_HU_B" SG_ 1140 DCS_MTO_Failure_Status 0;
BA_ "GenSigTimeoutMsg_HU_A" SG_ 1140 DCS_MTO_Failure_Status 0;
BA_ "GenSigSendType" SG_ 1140 DCS_MTO_Failure_Status 7;
BA_ "GenSigCycleTimeActive" SG_ 1140 DCS_MTO_Failure_Status 100;
BA_ "GenSigCycleTime" SG_ 1140 DCS_MTO_Failure_Status 100;
BA_ "GenSigTimeoutTime_HU_B" SG_ 1140 ABS_ESP_MRC_Failure_Status 0;
BA_ "GenSigTimeoutTime_HU_A" SG_ 1140 ABS_ESP_MRC_Failure_Status 0;
BA_ "GenSigTimeoutMsg_HU_B" SG_ 1140 ABS_ESP_MRC_Failure_Status 0;
BA_ "GenSigTimeoutMsg_HU_A" SG_ 1140 ABS_ESP_MRC_Failure_Status 0;
BA_ "GenSigSendType" SG_ 1140 ABS_ESP_MRC_Failure_Status 7;
BA_ "GenSigCycleTimeActive" SG_ 1140 ABS_ESP_MRC_Failure_Status 100;
BA_ "GenSigCycleTime" SG_ 1140 ABS_ESP_MRC_Failure_Status 100;
BA_ "GenSigTimeoutTime_HU_B" SG_ 1140 ABS_ESP_CRC_Failure_Status 0;
BA_ "GenSigTimeoutTime_HU_A" SG_ 1140 ABS_ESP_CRC_Failure_Status 0;
BA_ "GenSigTimeoutMsg_HU_B" SG_ 1140 ABS_ESP_CRC_Failure_Status 0;
BA_ "GenSigTimeoutMsg_HU_A" SG_ 1140 ABS_ESP_CRC_Failure_Status 0;
BA_ "GenSigSendType" SG_ 1140 ABS_ESP_CRC_Failure_Status 7;
BA_ "GenSigCycleTimeActive" SG_ 1140 ABS_ESP_CRC_Failure_Status 100;
BA_ "GenSigCycleTime" SG_ 1140 ABS_ESP_CRC_Failure_Status 100;
BA_ "GenSigTimeoutTime_HU_B" SG_ 1140 SRS_MTO_Failure_Status 0;
BA_ "GenSigTimeoutTime_HU_A" SG_ 1140 SRS_MTO_Failure_Status 0;
BA_ "GenSigTimeoutMsg_HU_B" SG_ 1140 SRS_MTO_Failure_Status 0;
BA_ "GenSigTimeoutMsg_HU_A" SG_ 1140 SRS_MTO_Failure_Status 0;
BA_ "GenSigSendType" SG_ 1140 SRS_MTO_Failure_Status 7;
BA_ "GenSigCycleTimeActive" SG_ 1140 SRS_MTO_Failure_Status 100;
BA_ "GenSigCycleTime" SG_ 1140 SRS_MTO_Failure_Status 100;
BA_ "GenSigTimeoutTime_HU_B" SG_ 1154 EPAS_SW_Version 0;
BA_ "GenSigTimeoutTime_HU_A" SG_ 1154 EPAS_SW_Version 0;
BA_ "GenSigTimeoutMsg_HU_B" SG_ 1154 EPAS_SW_Version 0;
BA_ "GenSigTimeoutMsg_HU_A" SG_ 1154 EPAS_SW_Version 0;
BA_ "GenSigSendType" SG_ 1154 EPAS_SW_Version 7;
BA_ "GenSigCycleTimeActive" SG_ 1154 EPAS_SW_Version 100;
BA_ "GenSigCycleTime" SG_ 1154 EPAS_SW_Version 100;
BA_ "GenSigTimeoutTime_HU_B" SG_ 1154 BattVolt_EPAS 0;
BA_ "GenSigTimeoutTime_HU_A" SG_ 1154 BattVolt_EPAS 0;
BA_ "GenSigTimeoutMsg_HU_B" SG_ 1154 BattVolt_EPAS 0;
BA_ "GenSigTimeoutMsg_HU_A" SG_ 1154 BattVolt_EPAS 0;
BA_ "GenSigSendType" SG_ 1154 BattVolt_EPAS 7;
BA_ "GenSigCycleTimeActive" SG_ 1154 BattVolt_EPAS 100;
BA_ "GenSigCycleTime" SG_ 1154 BattVolt_EPAS 100;
BA_ "GenSigTimeoutTime_HU_B" SG_ 1154 ABsESpMRcFailureStatus 0;
BA_ "GenSigTimeoutTime_HU_A" SG_ 1154 ABsESpMRcFailureStatus 0;
BA_ "GenSigTimeoutMsg_HU_B" SG_ 1154 ABsESpMRcFailureStatus 0;
BA_ "GenSigTimeoutMsg_HU_A" SG_ 1154 ABsESpMRcFailureStatus 0;
BA_ "GenSigSendType" SG_ 1154 ABsESpMRcFailureStatus 7;
BA_ "GenSigCycleTimeActive" SG_ 1154 ABsESpMRcFailureStatus 100;
BA_ "GenSigCycleTime" SG_ 1154 ABsESpMRcFailureStatus 100;
BA_ "GenSigTimeoutTime_HU_B" SG_ 1154 ABsESpCRcFailureStatus 0;
BA_ "GenSigTimeoutTime_HU_A" SG_ 1154 ABsESpCRcFailureStatus 0;
BA_ "GenSigTimeoutMsg_HU_B" SG_ 1154 ABsESpCRcFailureStatus 0;
BA_ "GenSigTimeoutMsg_HU_A" SG_ 1154 ABsESpCRcFailureStatus 0;
BA_ "GenSigSendType" SG_ 1154 ABsESpCRcFailureStatus 7;
BA_ "GenSigCycleTimeActive" SG_ 1154 ABsESpCRcFailureStatus 100;
BA_ "GenSigCycleTime" SG_ 1154 ABsESpCRcFailureStatus 100;
BA_ "GenSigTimeoutTime_HU_B" SG_ 1154 EMsInvalidFailureStatus 0;
BA_ "GenSigTimeoutTime_HU_A" SG_ 1154 EMsInvalidFailureStatus 0;
BA_ "GenSigTimeoutMsg_HU_B" SG_ 1154 EMsInvalidFailureStatus 0;
BA_ "GenSigTimeoutMsg_HU_A" SG_ 1154 EMsInvalidFailureStatus 0;
BA_ "GenSigSendType" SG_ 1154 EMsInvalidFailureStatus 7;
BA_ "GenSigCycleTimeActive" SG_ 1154 EMsInvalidFailureStatus 100;
BA_ "GenSigCycleTime" SG_ 1154 EMsInvalidFailureStatus 100;
BA_ "GenSigTimeoutTime_HU_B" SG_ 1154 ABsESpMToFailureStatus 0;
BA_ "GenSigTimeoutTime_HU_A" SG_ 1154 ABsESpMToFailureStatus 0;
BA_ "GenSigTimeoutMsg_HU_B" SG_ 1154 ABsESpMToFailureStatus 0;
BA_ "GenSigTimeoutMsg_HU_A" SG_ 1154 ABsESpMToFailureStatus 0;
BA_ "GenSigSendType" SG_ 1154 ABsESpMToFailureStatus 7;
BA_ "GenSigCycleTimeActive" SG_ 1154 ABsESpMToFailureStatus 100;
BA_ "GenSigCycleTime" SG_ 1154 ABsESpMToFailureStatus 100;
BA_ "GenSigTimeoutTime_HU_B" SG_ 1154 IPC_MRC_Failure_Status 0;
BA_ "GenSigTimeoutTime_HU_A" SG_ 1154 IPC_MRC_Failure_Status 0;
BA_ "GenSigTimeoutMsg_HU_B" SG_ 1154 IPC_MRC_Failure_Status 0;
BA_ "GenSigTimeoutMsg_HU_A" SG_ 1154 IPC_MRC_Failure_Status 0;
BA_ "GenSigSendType" SG_ 1154 IPC_MRC_Failure_Status 7;
BA_ "GenSigCycleTimeActive" SG_ 1154 IPC_MRC_Failure_Status 100;
BA_ "GenSigCycleTime" SG_ 1154 IPC_MRC_Failure_Status 100;
BA_ "GenSigTimeoutTime_HU_B" SG_ 1154 IPC_CRC_Failure_Status 0;
BA_ "GenSigTimeoutTime_HU_A" SG_ 1154 IPC_CRC_Failure_Status 0;
BA_ "GenSigTimeoutMsg_HU_B" SG_ 1154 IPC_CRC_Failure_Status 0;
BA_ "GenSigTimeoutMsg_HU_A" SG_ 1154 IPC_CRC_Failure_Status 0;
BA_ "GenSigSendType" SG_ 1154 IPC_CRC_Failure_Status 7;
BA_ "GenSigCycleTimeActive" SG_ 1154 IPC_CRC_Failure_Status 100;
BA_ "GenSigCycleTime" SG_ 1154 IPC_CRC_Failure_Status 100;
BA_ "GenSigTimeoutTime_HU_B" SG_ 1154 EPAS_EP_Failure_Status 0;
BA_ "GenSigTimeoutTime_HU_A" SG_ 1154 EPAS_EP_Failure_Status 0;
BA_ "GenSigTimeoutMsg_HU_B" SG_ 1154 EPAS_EP_Failure_Status 0;
BA_ "GenSigTimeoutMsg_HU_A" SG_ 1154 EPAS_EP_Failure_Status 0;
BA_ "GenSigSendType" SG_ 1154 EPAS_EP_Failure_Status 7;
BA_ "GenSigCycleTimeActive" SG_ 1154 EPAS_EP_Failure_Status 100;
BA_ "GenSigCycleTime" SG_ 1154 EPAS_EP_Failure_Status 100;
BA_ "GenSigTimeoutTime_HU_B" SG_ 1154 EPAS_BO_Failure_Status 0;
BA_ "GenSigTimeoutTime_HU_A" SG_ 1154 EPAS_BO_Failure_Status 0;
BA_ "GenSigTimeoutMsg_HU_B" SG_ 1154 EPAS_BO_Failure_Status 0;
BA_ "GenSigTimeoutMsg_HU_A" SG_ 1154 EPAS_BO_Failure_Status 0;
BA_ "GenSigSendType" SG_ 1154 EPAS_BO_Failure_Status 7;
BA_ "GenSigCycleTimeActive" SG_ 1154 EPAS_BO_Failure_Status 100;
BA_ "GenSigCycleTime" SG_ 1154 EPAS_BO_Failure_Status 100;
BA_ "GenSigTimeoutTime_HU_B" SG_ 1154 IPcInvalidFailureStatus 0;
BA_ "GenSigTimeoutTime_HU_A" SG_ 1154 IPcInvalidFailureStatus 0;
BA_ "GenSigTimeoutMsg_HU_B" SG_ 1154 IPcInvalidFailureStatus 0;
BA_ "GenSigTimeoutMsg_HU_A" SG_ 1154 IPcInvalidFailureStatus 0;
BA_ "GenSigSendType" SG_ 1154 IPcInvalidFailureStatus 7;
BA_ "GenSigCycleTimeActive" SG_ 1154 IPcInvalidFailureStatus 100;
BA_ "GenSigCycleTime" SG_ 1154 IPcInvalidFailureStatus 100;
BA_ "GenSigTimeoutTime_HU_B" SG_ 1154 BCM_MTO_Failure_status 0;
BA_ "GenSigTimeoutTime_HU_A" SG_ 1154 BCM_MTO_Failure_status 0;
BA_ "GenSigTimeoutMsg_HU_B" SG_ 1154 BCM_MTO_Failure_status 0;
BA_ "GenSigTimeoutMsg_HU_A" SG_ 1154 BCM_MTO_Failure_status 0;
BA_ "GenSigSendType" SG_ 1154 BCM_MTO_Failure_status 7;
BA_ "GenSigCycleTimeActive" SG_ 1154 BCM_MTO_Failure_status 100;
BA_ "GenSigCycleTime" SG_ 1154 BCM_MTO_Failure_status 100;
BA_ "GenSigTimeoutTime_HU_B" SG_ 1154 IPcMToFailureStatus 0;
BA_ "GenSigTimeoutTime_HU_A" SG_ 1154 IPcMToFailureStatus 0;
BA_ "GenSigTimeoutMsg_HU_B" SG_ 1154 IPcMToFailureStatus 0;
BA_ "GenSigTimeoutMsg_HU_A" SG_ 1154 IPcMToFailureStatus 0;
BA_ "GenSigSendType" SG_ 1154 IPcMToFailureStatus 7;
BA_ "GenSigCycleTimeActive" SG_ 1154 IPcMToFailureStatus 100;
BA_ "GenSigCycleTime" SG_ 1154 IPcMToFailureStatus 100;
BA_ "GenSigTimeoutTime_HU_B" SG_ 1154 EMsMToFailureStatus 0;
BA_ "GenSigTimeoutTime_HU_A" SG_ 1154 EMsMToFailureStatus 0;
BA_ "GenSigTimeoutMsg_HU_B" SG_ 1154 EMsMToFailureStatus 0;
BA_ "GenSigTimeoutMsg_HU_A" SG_ 1154 EMsMToFailureStatus 0;
BA_ "GenSigSendType" SG_ 1154 EMsMToFailureStatus 7;
BA_ "GenSigCycleTimeActive" SG_ 1154 EMsMToFailureStatus 100;
BA_ "GenSigCycleTime" SG_ 1154 EMsMToFailureStatus 100;
BA_ "GenSigTimeoutTime_HU_B" SG_ 1154 ABsESpInvalidFailureStatus 0;
BA_ "GenSigTimeoutTime_HU_A" SG_ 1154 ABsESpInvalidFailureStatus 0;
BA_ "GenSigTimeoutMsg_HU_B" SG_ 1154 ABsESpInvalidFailureStatus 0;
BA_ "GenSigTimeoutMsg_HU_A" SG_ 1154 ABsESpInvalidFailureStatus 0;
BA_ "GenSigSendType" SG_ 1154 ABsESpInvalidFailureStatus 7;
BA_ "GenSigCycleTimeActive" SG_ 1154 ABsESpInvalidFailureStatus 100;
BA_ "GenSigCycleTime" SG_ 1154 ABsESpInvalidFailureStatus 100;
BA_ "GenSigTimeoutTime_HU_B" SG_ 1154 AMT_AT_DCT_MTO_Failure_Status 0;
BA_ "GenSigTimeoutTime_HU_A" SG_ 1154 AMT_AT_DCT_MTO_Failure_Status 0;
BA_ "GenSigTimeoutMsg_HU_B" SG_ 1154 AMT_AT_DCT_MTO_Failure_Status 0;
BA_ "GenSigTimeoutMsg_HU_A" SG_ 1154 AMT_AT_DCT_MTO_Failure_Status 0;
BA_ "GenSigSendType" SG_ 1154 AMT_AT_DCT_MTO_Failure_Status 7;
BA_ "GenSigCycleTimeActive" SG_ 1154 AMT_AT_DCT_MTO_Failure_Status 100;
BA_ "GenSigCycleTime" SG_ 1154 AMT_AT_DCT_MTO_Failure_Status 100;
BA_ "GenSigTimeoutTime_HU_B" SG_ 1154 AMT_AT_DCT_Invalid_Failure_Statu 0;
BA_ "GenSigTimeoutTime_HU_A" SG_ 1154 AMT_AT_DCT_Invalid_Failure_Statu 0;
BA_ "GenSigTimeoutMsg_HU_B" SG_ 1154 AMT_AT_DCT_Invalid_Failure_Statu 0;
BA_ "GenSigTimeoutMsg_HU_A" SG_ 1154 AMT_AT_DCT_Invalid_Failure_Statu 0;
BA_ "GenSigSendType" SG_ 1154 AMT_AT_DCT_Invalid_Failure_Statu 7;
BA_ "GenSigCycleTimeActive" SG_ 1154 AMT_AT_DCT_Invalid_Failure_Statu 100;
BA_ "GenSigCycleTime" SG_ 1154 AMT_AT_DCT_Invalid_Failure_Statu 100;
BA_ "SystemSignalLongSymbol" SG_ 1154 AMT_AT_DCT_Invalid_Failure_Statu "AMT_AT_DCT_Invalid_Failure_Status";
VAL_ 732 TpmsTireSensorConfig 3 "Reserved" 2 "Reserved" 1 "5 tire sensor Configuration" 0 "4 tire sensor Configuration" ;
VAL_ 732 TPMSPresence 1 "Reserved" 0 "TPMS is present" ;
VAL_ 732 LowTirePresAlertSpare 1 "Low Pressure Alert In Spare Tire" 0 "No Low Pressure In Spare Tire" ;
VAL_ 732 LowTirePresAlertRL 1 "Low Pressure Alert In RL Tire" 0 "No Low Pressure In RL Tire" ;
VAL_ 732 LowTirePresAlertRR 1 "Low Pressure Alert In RR Tire" 0 "No Low Pressure In RR Tire" ;
VAL_ 732 LowTirePresAlertFR 1 "Low Pressure Alert In FR Tire" 0 "No Low Pressure In FR Tire" ;
VAL_ 732 LowTirePresAlertFL 1 "Low Pressure Alert In FL Tire" 0 "No Low Pressure In FL Tire" ;
VAL_ 732 HighTirePresAlertSpare 1 "High Pressure Alert In Spare Tire" 0 "No High Pressure In Spare Tire" ;
VAL_ 732 HighTirePresAlertRL 1 "High Pressure Alert In RL Tire" 0 "No High Pressure In RL Tire" ;
VAL_ 732 HighTirePresAlertRR 1 "High Pressure Alert In RR Tire" 0 "No High Pressure In RR Tire" ;
VAL_ 732 HighTirePresAlertFR 1 "High Pressure Alert In FR Tire" 0 "No High Pressure In FR Tire" ;
VAL_ 732 HighTirePresAlertFL 1 "High Pressure Alert In FL Tire" 0 "No High Pressure In FL Tire" ;
VAL_ 732 HighTireTempAlertSpare 1 "High Temperature Alert In Spare Tire" 0 "No High Temperature In Spare Tire" ;
VAL_ 732 HighTireTempAlertRL 1 "High Temperature Alert In RL Tire" 0 "No High Temperature In RL Tire" ;
VAL_ 732 HighTireTempAlertRR 1 "High Temperature Alert In RR Tire" 0 "No High temperature in RR Tire" ;
VAL_ 732 HighTireTempAlertFR 1 "High Temperature Alert In FR Tire" 0 "No High Temperature In FR Tire" ;
VAL_ 732 HighTireTempAlertFL 1 "High Temperature Alert In FL Tire" 0 "No High Temperature In FL Tire" ;
VAL_ 732 PresLeakageAlertSpare 1 "Pressure Leakage Alert In Spare Tire" 0 "No Pressure leakage in Spare Tire" ;
VAL_ 732 PresLeakageAlertRL 1 "Pressure Leakage Alert In RL Tire" 0 "No Pressure leakage in RL Tire" ;
VAL_ 732 PresLeakageAlertRR 1 "Pressure Leakage Alert In RR Tire" 0 "No Pressure leakage in RR Tire" ;
VAL_ 732 PresLeakageAlertFR 1 "Pressure Leakage Alert In FR Tire" 0 "No Pressure leakage in FR Tire" ;
VAL_ 732 PresLeakageAlertFL 1 "Pressure Leakage Alert In FL Tire" 0 "No Pressure leakage in FL Tire" ;
VAL_ 732 TpmsAlertStatus 3 "Any Alert to be Issued" 2 "Reserved" 0 "No Alert to be Issued" 1 "Reserved" ;
VAL_ 732 TpmsReceiverRXFault 1 "Receiver Has Rx Fault" 0 "No Rx Fault Present" ;
VAL_ 732 SensorMalfncFaultSpare 1 "Low Bat or Tx Fault In Spare Tire" 0 "No Low Bat or Tx Fault In Spare Tire" ;
VAL_ 732 SensorMalfncFaultRL 1 "Low Bat or Tx Fault In RL Tire" 0 "No Low Bat or Tx Fault In RL Tire" ;
VAL_ 732 SensorMalfncFaultRR 1 "Low Bat or Tx Fault In RR Tire" 0 "No Low Bat or Tx Fault In RR Tire" ;
VAL_ 732 SensorMalfncFaultFR 1 "Low Bat or Tx Fault In FR Tire" 0 "No Low Bat or Tx Fault In FR Tire" ;
VAL_ 732 SensorMalfncFaultFL 1 "Low Bat or Tx Fault In FL Tire" 0 "No Low Bat or Tx Fault In FL Tire" ;
VAL_ 732 TpmsFaultStatus 3 "TPMS System Has Fault" 2 "Reserved" 1 "Reserved" 0 "TPMS System Is Fully Functional" ;
VAL_ 732 TpmsNotLearntFault 1 "Receiver is not Learnt" 0 "Receiver is Learnt" ;
VAL_ 732 SensorMissingFaultRL 1 "Sensor Missing in RL Tire" 0 "No Sensor Missing in RL Tire" ;
VAL_ 732 SensorMissingFaultRR 1 "Sensor Missing in RR Tire" 0 "No Sensor Missing in RR Tire" ;
VAL_ 732 SensorMissingFaultFR 1 "Sensor Missing in FR Tire" 0 "No Sensor Missing in FR Tire" ;
VAL_ 732 SensorMissingFaultFL 1 "Sensor Missing in FL Tire" 0 "No Sensor Missing In FL Tire" ;
VAL_ 732 TpmsLearnStatus 3 "Last Learning Is Failed" 2 "Last Learning Is Passed" 1 "TPMS Is In Learning Mode" 0 "Default Status" ;
VAL_ 732 SpareTireSwapFlagRL 1 "RL Tire Has Spare Tire Swap" 0 "No Spare Tire Swap with RL Tire" ;
VAL_ 732 SpareTireSwapFlagRR 1 "RR Tire Has Spare Tire Swap" 0 "No Spare Tire Swap with RR Tire" ;
VAL_ 732 SpareTireSwapFlagFR 1 "FR Tire Has Spare Tire Swap" 0 "No Spare Tire Swap with FR Tire" ;
VAL_ 732 SpareTireSwapFlagFL 1 "FL Tire Has Spare Tire Swap" 0 "No Spare Tire Swap With FL Tire" ;
VAL_ 732 SensorLearningStatus 7 "Signal Is Invalid" 6 "Reserved" 5 "TPMS Learning Spare Tire" 4 "TPMS Learning RL Tire" 3 "TPMS Learning RR Tire" 2 "TPMS Learning FR Tire" 1 "TPMS Learning FL Tire" 0 "Learning No Tire" ;
VAL_ 732 SensorDetectFlagSpare 0 "Sensor Not Detected In Spare Tire" 1 "Sensor Detected In Spare Tire" ;
VAL_ 732 SensorDetectFlagRL 0 "Sensor not Detected in RL Tire" 1 "Sensor Detected In RL Tire" ;
VAL_ 732 SensorDetectFlagRR 0 "Sensor not Detected in RR Tire" 1 "Sensor Detected In RR Tire" ;
VAL_ 732 SensorDetectFlagFR 0 "Sensor not Detected in FR Tire" 1 "Sensor Detected In FR Tire" ;
VAL_ 732 SensorDetectFlagFL 0 "Sensor Not Detected In FL Tire" 1 "Sensor Detected In FL Tire" ;
VAL_ 733 SensorIDnotLearntSpare 1 "Sensor ID Not Learnt In Spare Tire" 0 "Sensor ID Learnt In Spare Tire" ;
VAL_ 733 SensorIDnotLearntRL 1 "Sensor ID Not Learnt In RL Tire" 0 "Sensor ID Learnt In RL Tire" ;
VAL_ 733 SensorIDnotLearntRR 1 "Sensor ID Not Learnt In RR Tire" 0 "Sensor ID Learnt In RR Tire" ;
VAL_ 733 SensorIDnotLearntFR 1 "Sensor ID Not Learnt In FR Tire" 0 "Sensor ID Learnt In FR Tire" ;
VAL_ 733 SensorIDnotLearntFL 1 "Sensor ID Not Learnt In FL Tire" 0 "Sensor ID Learnt In FL Tire" ;
VAL_ 733 TireFillAlertSpare 0 "No Filling Process in Spare Tire" 1 "Pressure Fill Alert In Spare Tire" ;
VAL_ 733 TireFillAlertRL 1 "Pressure Fill Alert In RL Tire" 0 "No Filling Process in RL Tire" ;
VAL_ 733 TireFillAlertRR 0 "No Filling Process in RR Tire" 1 "Pressure Fill Alert In RR Tire" ;
VAL_ 733 TireFillAlertFR 0 "No Filling Process in FR Tire" 1 "Pressure Fill Alert In FR Tire" ;
VAL_ 733 TireFillAlertFL 1 "Pressure Fill Alert In FL Tire" 0 "No Filling Process In FL Tire" ;
VAL_ 733 PresBurstAlertRL 1 "Pressure Burst In RL Tire" 0 "No Pressure Burst in RL Tire" ;
VAL_ 733 PresBurstAlertRR 1 "Pressure Burst In RR Tire" 0 "No Pressure Burst in RR Tire" ;
VAL_ 733 PresBurstAlertFR 0 "No Pressure Burst in FR Tire" 1 "Pressure Burst In FR Tire" ;
VAL_ 733 PresBurstAlertFL 1 "Pressure Burst In FL Tire" 0 "No Pressure Burst In FL Tire" ;
VAL_ 744 HuCCmFanSpdDuringVR 15 "Reserved" 14 "Reserved" 13 "Reserved" 12 "Reserved" 11 "Reserved" 10 "Reserved" 9 "Reserved" 8 "Reserved" 7 "Speed 7" 6 "Speed 6" 5 "Speed 5" 4 "Speed 4" 3 "Speed 3" 2 "Speed 2" 1 "Speed 1" 0 "Speed 0" ;
VAL_ 744 HuCCmVRSession 3 "Reserved" 2 "Reserved" 1 "Active" 0 "Not Active" ;
VAL_ 938 VehSlowDownWarning 1 "Display Warning message" 0 "Do Not Display Warning message" ;
VAL_ 938 NoKeyDetectedTelltaleMsg 1 "Display - Key Not Detected" 0 "Don't Display - Key Not Detected" ;
VAL_ 938 LowBatUIdMsg 1 "Display -  UID battery is low" 0 "Don't Display -  UID battery is low" ;
VAL_ 938 PressClutchTelltaleMsgStatus 3 "Signal PressClutchTelltaleMsg Not Available" 2 "Reserved" 1 "Reserved" 0 "Signal is plausible" ;
VAL_ 938 PEPSAudioWarning 1 "Issue Warning" 0 "Do not Issue Warning" ;
VAL_ 938 PressBrakeTelltaleMsg 1 "Display -  Press Brake Pedal to Start Engine" 0 "Don't Display -  Press Brake Pedal to Start Engine" ;
VAL_ 938 PressClutchTelltaleMsg 1 "Display -  Press Clutch Pedal to Start Engine" 0 "Don't Display -  Press Clutch Pedal to Start Engine" ;
VAL_ 938 PressBrakeTelltaleMsgStatus 3 "Signal PressBrakeTelltaleMsg Not Available" 2 "Reserved" 1 "Reserved" 0 "Signal is plausible" ;
VAL_ 946 DoorStateRearLHStatus 3 "Signal not available" 2 "Reserved" 1 "Reserved" 0 "Value is plausible" ;
VAL_ 946 DoorStatePassStatus 3 "Signal not avialable" 2 "Reserved" 1 "Reserved" 0 "Value is plausible" ;
VAL_ 946 DoorStatePass 1 "Open" 0 "Close" ;
VAL_ 946 DoorStateDrvrStatus 3 "Signal not available" 2 "Reserved" 1 "Reserved " 0 "Signal is plausible" ;
VAL_ 946 DoorStateDrvr 1 "open" 0 "Close" ;
VAL_ 946 DoorStateRearRH 1 "Open" 0 "Close" ;
VAL_ 946 DoorStateRearRHStatus 3 "Signal not available" 2 "Reserved" 1 "Reserved" 0 "Value is plausible" ;
VAL_ 946 DoorStateRearLH 1 "open" 0 "close" ;
VAL_ 946 WiperState 7 "Reserved" 6 "Reserved" 5 "Reserved" 4 "Reserved" 3 "Reserved" 2 "Reserved" 1 "Wiper ON" 0 "Wiper OFF" ;
VAL_ 946 TailgateState 1 "Open" 0 "Close" ;
VAL_ 946 WiperStateStatus 3 "Signal not available" 2 "Reserved" 1 "Reserved" 0 "Value is plausible" ;
VAL_ 946 TailgateStateStatus 3 "Signal not available" 2 "Reserved" 1 "Reserved" 0 "Value is plausible" ;
VAL_ 946 PositionLmpMalFn 1 "Position Lamp Malfunction" 0 "Position Lamp Normal" ;
VAL_ 946 TrailerState 1 "Trailer connected" 0 "Trailer not connected" ;
VAL_ 946 PositionLmpMalFnStatus 3 "Signal not available" 2 "Reserved" 1 "Reserved" 0 "Value is plausible" ;
VAL_ 946 BrakeLmpMalFn 1 "Brake Lamp Malfunction" 0 "Brake Lamp Normal" ;
VAL_ 946 BrakeLmpMalFnStatus 3 "Signal not available" 2 "Reserved" 1 "Reserved" 0 "Value is plausible" ;
VAL_ 946 RevLampMalFn 1 "Reverse Lamp Malfunction" 0 "Reverse Lamp Normal" ;
VAL_ 946 RevLampMalFnStatus 3 "Signal not available" 2 "Reserved" 1 "Reserved" 0 "Value is plausible" ;
VAL_ 946 TrailerStateStatus 3 "Signal not available" 2 "Reserved" 1 "Reserved" 0 "Value is plausible" ;
VAL_ 946 LowBeamMalFn 1 "Low Beam Malfunction" 0 "Low Beam Normal" ;
VAL_ 946 HighBeamTelltale 1 "High Beam ON" 0 "High Beam OFF" ;
VAL_ 946 HighBeamTelltaleStatus 3 "Signal not available" 2 "Reserved" 1 "Reserved" 0 "Value is plausible" ;
VAL_ 946 DRLTelltale 1 "DRL ON" 0 "DRL OFF" ;
VAL_ 946 FrontFogTelltale 1 "Front Fog Lamps ON" 0 "Front Fog Lamps OFF" ;
VAL_ 946 RearFogTelltaleStatus 3 "Signal not available" 2 "Reserved" 1 "Reserved" 0 "Value is plausible" ;
VAL_ 946 FrontFogTelltaleStatus 3 "Signal not available" 2 "Reserved" 1 "Reserved" 0 "Value is plausible" ;
VAL_ 946 DRLTelltaleStatus 3 "Signal not available" 2 "Reserved" 1 "Reserved" 0 "Value is plausible" ;
VAL_ 946 InfoTheftMsg 3 "Reserved " 2 "Reserved " 1 "YES-Theft Message" 0 "NO-Theft Message" ;
VAL_ 946 WiperHighLowIntermtStateStatus 3 "Signal WiperState not available" 2 "Reserved for future use" 1 "Reserved for future use" 0 "Plausible-Information given by WiperState is correct and according to specification" ;
VAL_ 946 WiperHighLowIntermtState 7 "Reserved Bit" 6 "Reserved Bit" 5 "Reserved Bit" 4 "Reserved Bit" 3 "Wiper INTERMITTENT Mode Enable" 2 "Wiper LOW Speed Mode Enable" 1 "Wiper HIGH Speed Mode Enable" 0 "Wiper OFF" ;
VAL_ 946 LowBeamMalFnStatus 3 "Signal not available" 2 "Reserved" 1 "Reserved" 0 "Value is plausible" ;
VAL_ 946 ESSSwSig 1 "ESS switch pressed" 0 "ESS switch not pressed" ;
VAL_ 946 BonnetState 1 "Open" 0 "Close" ;
VAL_ 946 RearFogTelltale 1 "Rear Fog Lamps ON" 0 "Rear Fog Lamps OFF" ;
VAL_ 946 BonnetStateStatus 3 "Signal Not Available" 2 "Reserved for future" 1 "Reserved for future" 0 "Value is plausible" ;
VAL_ 946 VehicleUnLockTypeConfgStatus 3 "Signal is not available" 2 "Signal is implausible" 1 "Reserved" 0 "Signal is plausible" ;
VAL_ 946 VehicleUnLockTypeConfg 3 "Reserved for future use" 2 "Single Stage With Tailgate Unlock" 1 "Double Stage Unlock" 0 "Single Stage Unlock" ;
VAL_ 946 ESSSwSigStatus 3 "Signal not available" 2 "Value is implausibe" 1 "Reserved" 0 "Value is plausible" ;
VAL_ 948 OdoICFullSigPeriodicStatus 3 "Signal Not Available" 2 "Information given by IC is implausible" 1 "Reserved for future use" 0 "Information given by IC is correct" ;
VAL_ 950 TrailerPositionLmpMalFnToIpc 1 "Trailer Position Lamp Malfunction to IPC" 0 "Trailer Position Lamp Normal" ;
VAL_ 950 TrailerPositionLmpMalFnToIpcStat 3 "Signal not available" 2 "Reserved" 1 "Reserved" 0 "Value is plausible" ;
VAL_ 950 TrailerRevLmpMalFnToIpc 1 "Trailer Reverse lamp Malfunction to IPC" 0 "Trailer Reverse lamp Normal" ;
VAL_ 950 TrailerRevLmpMalFnToIpcStatus 3 "Signal not available" 2 "Reserved" 1 "Reserved" 0 "Value is plausible" ;
VAL_ 950 TrailerFogMalFnToIpcStatus 3 "Signal not available" 2 "Reserved" 1 "Reserved" 0 "Value is plausible" ;
VAL_ 950 TrailerFogMalFnToIpc 1 "Trailer Fog Lamp Malfunction to IPC" 0 "Trailer Fog Lamp Normal" ;
VAL_ 950 TrailerTurnRhMalFnToIpc 1 "Trailer Turn right indicator light malfunction to IPC" 0 "Trailer Turn right indicator light Normal" ;
VAL_ 950 TrailerTurnLhMalFnToIpcStatus 3 "Signal not available" 2 "Reserved" 1 "Reserved" 0 "Value is plausible" ;
VAL_ 950 TrailerTurnLhMalFnToIpc 1 "Trailer Turn left indicator light malfunction to IPC" 0 "Trailer Turn left indicator light Normal" ;
VAL_ 950 TrailerTurnRhMalFnToIpcStatus 3 "Signal not available" 2 "Reserved" 1 "Reserved" 0 "Value is plausible" ;
VAL_ 950 TrailerBrkLmpMalFnToIpc 1 "Trailer Brake Lamp Malfunction to IPC" 0 "Trailer Brake Lamp Normal" ;
VAL_ 950 TrailerBrkLmpMalFnToIpcStatus 3 "Signal not available" 2 "Reserved" 1 "Reserved" 0 "Value is plausible" ;
VAL_ 1104 BCM_MTO_Failure_status 3 "Reserved" 2 "Failure is cleared and DTC is moved to history." 1 "Failure is detected and active DTC is stored in the error memory." 0 "Failure is currently not detected." ;
VAL_ 1104 EMS_MTO_Failure_Status 3 "Reserved" 2 "Failure is cleared and DTC is moved to history." 1 "Failure is detected and active DTC is stored in the error memory." 0 "Failure is currently not detected." ;
VAL_ 1104 ESP_MTO_Failure_Status 3 "Reserved" 2 "Failure is cleared and DTC is moved to history." 1 "Failure is detected and active DTC is stored in the error memory." 0 "Failure is currently not detected." ;
VAL_ 1104 DCS_BO_Failure_Status 3 "Reserved" 2 "Failure healed Ageing in progress" 1 "Failure matured & DTC in memory" 0 "Faiulure is not detected " ;
VAL_ 1104 IPcMToFailureStatus 3 "Reserved" 2 "Failure healed Ageing in progress" 1 "Failure matured & DTC in memory" 0 "Failure is not detected" ;
VAL_ 1104 EMsInvalidFailureStatus 3 "Reserved" 2 "Failure healed Ageing in progress" 1 "Failure matured & DTC in memory" 0 "Failure is not detected" ;
VAL_ 1104 ESpInvalidFailureStatus 3 "Reserved" 2 "Failure healed ageing in progress" 1 "fail detected and DTC  in memory" 0 "failure not detected" ;
VAL_ 1104 BCM_Invalid_Status_Failure 3 "Reserved" 2 "Failure healed aging in progress" 1 "Failure detected DTC in memory" 0 "Failure is not detected" ;
VAL_ 1104 DCS_EP_Failure_Status 3 "Reserved" 2 "Failurehealed Ageing in progress" 1 "Failure matured & DTC in memory" 0 "Faiulure is not detected " ;
VAL_ 1136 AuthMechKeyStatus 3 "Signal not available" 2 "value is implausible" 1 "Reserved" 0 "Value is plausible" ;
VAL_ 1136 AuthMechKey 3 "A valid key was detected in the last 30 seconds" 2 "Valid key no more available (after 30second validity time is expired)." 1 "Key detection running" 0 "No valid key detected since IGN ON or MCU request " ;
VAL_ 1140 Telematics_MTO_Failure_Status 3 "Reserved" 2 "Failure healed aging in progress" 1 "Failure matured & DTC in memory" 0 "Failure is not detected" ;
VAL_ 1140 Telematics_Invalid_Failure__0000 3 "Reserved" 2 "Failure healed aging in progress" 1 "Failure matured & DTC in memory" 0 "Failure is not detected" ;
VAL_ 1140 HU_MTO_Failure_Status 3 "Reserved" 2 "Failure healed aging in progress" 1 "Failrue detected DTC in mem" 0 "Failure is not detected" ;
VAL_ 1140 HU_Invalid_Failure_Status 3 "Reserved" 2 "Failure healed Ageing in progress" 1 "Failure matured & DTC in memory" 0 "Failure is not detected" ;
VAL_ 1140 CCM_Invalid_Failure_Status 3 "Reserved" 2 "Failure healed Ageing in progress" 1 "Failure matured & DTC in memory" 0 "Failure is not detected" ;
VAL_ 1140 AT_AMT_DCT_MTO_Failure_Status 3 "Reserved" 2 "Failure healed Ageing in progress" 1 "Failure matured & DTC in memory" 0 "Failure is not detected" ;
VAL_ 1140 EPAS_Invalid_Failure_Status 3 "Reserved" 2 "Ageing in progress" 1 "fail detected and DTC memory" 0 "failure not detected" ;
VAL_ 1140 BCmMToFailureStatus 3 "Reserved" 2 "Failure healed aging in progress" 1 "Failure detected; DTC in memory" 0 "Failrue is not detected" ;
VAL_ 1140 EPAS_MTO_Failure_Status 3 "Reserved" 2 "Failure healed aging in progress" 1 "Failrue detected DTC in mem" 0 "Failure is not detected" ;
VAL_ 1140 EMS_BO_Failure_Status 3 "Historic DTC" 2 "Failurehealed Ageing in progress" 1 "Failure matured & DTC in memory" 0 "Faiulure is not detected " ;
VAL_ 1140 EMS_EP_Failure_Status 3 "Historic DTC" 2 "Failurehealed Ageing in progress" 1 "Failure matured & DTC in memory" 0 "Faiulure is not detected " ;
VAL_ 1140 ABS_ESP_MTO_Failure_Status 3 "Reserved" 2 "Failure healed aging in progress" 1 "Failrue detected DTC in memory" 0 "Failure is not detected" ;
VAL_ 1140 PEPS_MTO_Failure_Status 3 "Reserved" 2 "Failure healed aging in progress" 1 "Failure detected DTC in Memory" 0 "Failure is not detected" ;
VAL_ 1140 AT_AMT_DCT_Invalid_Failure_Statu 3 "Reserved" 2 "Failure healed Ageing in progress" 1 "Failure matured & DTC in memory" 0 "Failure is not detected" ;
VAL_ 1140 ABS_ESP_Invalid_Failure_Status 3 "Reserved" 2 "Failure healed ageing in progress" 1 "fail detected and DTC  in memory" 0 "failure not detected" ;
VAL_ 1140 IPcInvalidFailureStatus 3 "Reserved" 2 "Failure healed Ageing in progress" 1 "Failure matured & DTC in memory" 0 "Failure is not detected" ;
VAL_ 1140 BCmInvalidFailureStatus 3 "Reserved" 2 "Failure healed Ageing in progress" 1 "Failure matured & DTC in memory" 0 "Failure is not detected" ;
VAL_ 1140 IPcMToFailureStatus 3 "Reserved" 2 "Failure healed Ageing in progress" 1 "Failure matured & DTC in memory" 0 "Failure is not detected" ;
VAL_ 1140 CCM_MTO_Failure_Status 3 "Reserved" 2 "Failure healed & Ageing in progress" 1 "failure is detected & DTC in memeory" 0 "Failure is not detected" ;
VAL_ 1140 DCS_Invalid_Failure_Status 3 "Reserved" 2 "Failure healed Ageing in progress" 1 "Failure matured & DTC in memory" 0 "Failure is not detected" ;
VAL_ 1140 DCS_MTO_Failure_Status 3 "Reserved" 2 "Failure Healed; aging in progress" 1 "Failure Detected; DTC in memory" 0 "Failure is not Detected" ;
VAL_ 1140 ABS_ESP_MRC_Failure_Status 3 "Reserved" 2 "Failurehealed Ageing in progress" 1 "Failure matured & DTC in memory" 0 "Faiulure is not detected " ;
VAL_ 1140 ABS_ESP_CRC_Failure_Status 3 "Reserved" 2 "Failurehealed Ageing in progress" 1 "Failure matured & DTC in memory" 0 "Faiulure is not detected " ;
VAL_ 1140 SRS_MTO_Failure_Status 3 "Reserved" 2 "Failure healed aging in progress" 1 "Failure detected DTC in Memory" 0 "Failure is not detected" ;
VAL_ 1154 ABsESpMRcFailureStatus 3 "Reserved" 2 "Failurehealed Ageing in progress" 1 "Failure matured & DTC in memory" 0 "Faiulure is not detected " ;
VAL_ 1154 ABsESpCRcFailureStatus 3 "Reserved" 2 "Failurehealed Ageing in progress" 1 "Failure matured & DTC in memory" 0 "Faiulure is not detected " ;
VAL_ 1154 EMsInvalidFailureStatus 3 "Reserved" 2 "Failure healed Ageing in progress" 1 "Failure matured & DTC in memory" 0 "Failure is not detected" ;
VAL_ 1154 ABsESpMToFailureStatus 3 "Reserved" 2 "Failure healed aging in progress" 1 "Failrue detected DTC in memory" 0 "Failure is not detected" ;
VAL_ 1154 IPC_MRC_Failure_Status 3 "Reserved" 2 "Failurehealed Ageing in progress" 1 "Failure matured & DTC in memory" 0 "Faiulure is not detected " ;
VAL_ 1154 IPC_CRC_Failure_Status 3 "Reserved" 2 "Failurehealed Ageing in progress" 1 "Failure matured & DTC in memory" 0 "Faiulure is not detected " ;
VAL_ 1154 EPAS_EP_Failure_Status 3 "Historic DTC" 2 "Failurehealed Ageing in progress" 1 "Failure matured & DTC in memory" 0 "Faiulure is not detected " ;
VAL_ 1154 EPAS_BO_Failure_Status 3 "Historic DTC" 2 "Failurehealed Ageing in progress" 1 "Failure matured & DTC in memory" 0 "Faiulure is not detected " ;
VAL_ 1154 IPcInvalidFailureStatus 3 "Reserved" 2 "Failure healed Ageing in progress" 1 "Failure matured & DTC in memory" 0 "Failure is not detected" ;
VAL_ 1154 BCM_MTO_Failure_status 3 "Reserved" 2 "Failure is cleared and DTC is moved to history." 1 "Failure is detected and active DTC is stored in the error memory." 0 "Failure is currently not detected." ;
VAL_ 1154 IPcMToFailureStatus 3 "Reserved" 2 "Failure healed Ageing in progress" 1 "Failure matured & DTC in memory" 0 "Failure is not detected" ;
VAL_ 1154 EMsMToFailureStatus 3 "Historic DTC" 2 "Failurehealed Ageing in progress" 1 "Failure matured & DTC in memory" 0 "Faiulure is not detected " ;
VAL_ 1154 ABsESpInvalidFailureStatus 3 "Reserved" 2 "Failure healed ageing in progress" 1 "fail detected and DTC  in memory" 0 "failure not detected" ;
VAL_ 1154 AMT_AT_DCT_MTO_Failure_Status 3 "Reserved" 2 "Failure healed Ageing in progress" 1 "Failure matured & DTC in memory" 0 "Failure is not detected" ;
VAL_ 1154 AMT_AT_DCT_Invalid_Failure_Statu 3 "Reserved" 2 "Failure healed Ageing in progress" 1 "Failure matured & DTC in memory" 0 "Failure is not detected" ;
